VERSION ""

NS_ :

BS_:
BU_: ME SC01 BMS01 BMS PT
BO_ 1860 BMS05_DebugSlowMpex1: 8 BMS05
 SG_ SOHRecentChange_BMS05 m43 : 15|8@0+ (0.1,-15) [-15|10.5] ""  PT
 SG_ SOHConvergenceIndicator_BMS05 m43 : 31|8@0+ (1,0) [0|255] ""  PT
 SG_ SOHConvergenceCounter_BMS05 m43 : 39|8@0+ (0.024,3) [0|6] ""  PT
 SG_ SOHMinFiltered_BMS05 m43 : 23|8@0+ (0.3,50) [50|126.5] "PCT"  PT
 SG_ prechargeCyMatchWaitTime_BMS05 m43 : 47|16@0+ (1,0) [0|65535] "ms"  PT
 SG_ medianModuleTempGrp2_BMS05 m13 : 63|8@0+ (1,-40) [-40|200] "C"  PT
 SG_ medianModuleTempGrp1_BMS05 m13 : 55|8@0+ (1,-40) [-40|200] "C"  PT
 SG_ coolantWarningtAlert_BMS05 m12 : 49|2@0+ (1,0) [0|3] ""  PT
 SG_ coolantFaultAlert_BMS05 m12 : 51|2@0+ (1,0) [0|3] ""  PT
 SG_ hvilShutdownStrategy_BMS05 m42 : 63|8@0+ (1,0) [0|255] ""  PT
 SG_ J1939_nmState m12 : 55|4@0+ (1,0) [0|0] ""  PT
 SG_ PrechargeXCapMin_BMS05 m42 : 47|16@0+ (0.01,0) [0|1] "mF"  PT
 SG_ LimpHomeTimeOut_BMS05 m42 : 15|32@0+ (1,0) [0|4294967295] "ms"  PT
 SG_ hvWithstandTests_BMS05 m40 : 15|8@0+ (1,0) [0|255] ""  PT
 SG_ aux3prechargeState_BMS05 m41 : 19|4@0+ (1,0) [0|0] ""  PT
 SG_ aux2prechargeState_BMS05 m41 : 31|4@0+ (1,0) [0|0] ""  PT
 SG_ aux1prechargeState_BMS05 m41 : 27|4@0+ (1,0) [0|0] ""  PT
 SG_ auxLinkVoltage_BMS05 m40 : 23|16@0+ (0.02,0) [0|1310.7] "V"  PT
 SG_ invalidModuleVoltageFlags_BMS05 m41 : 39|32@0+ (1,0) [0|0] ""  PT
 SG_ invalidModuleTempFlags_BMS05 m40 : 39|32@0+ (1,0) [0|0] ""  PT
 SG_ pumpSpeedExpected_BMS05 m30 : 15|8@0+ (0.4,0) [0|102] "%"  PT
 SG_ rangeRequestIgnoreVehicle m28 : 55|4@0+ (1,0) [0|65535] ""  PT
 SG_ rangeRequestEepromValue m28 : 63|4@0+ (1,0) [0|65535] ""  PT
 SG_ pressure2_BMS05 m35 : 31|8@0+ (0.4,0) [0|19] "psi"  PT
 SG_ calibration_version_BMS05 m37 : 63|8@0+ (1,0) [0|0] ""  PT
 SG_ currentLowTimer_BMS05 m39 : 55|16@0+ (1,0) [0|65535] "s"  PT
 SG_ auxCntrrOpenUnderLoadCntr_BMS05 m39 : 39|16@0+ (1,0) [0|0] ""  PT
 SG_ rabbitContactorState_BMS05 m34 : 31|8@0+ (1,0) [0|255] ""  PT
 SG_ analogIsenseSupplyCurr_BMS05 m37 : 55|8@0+ (0.04,0) [0|10] "A"  PT
 SG_ pumpSpeedReqCoolPrfmc_BMS05 m29 : 15|8@0+ (1,0) [0|0] "PCT"  PT
 SG_ microsarOs_IdleTask_OsCr0_BMS05 m39 : 23|8@0+ (1,0) [0|100] "PCT"  PT
 SG_ microsarOs_BswTask_BMS05 m39 : 15|8@0+ (1,0) [0|100] "PCT"  PT
 SG_ microsarOs_InitTask_BMS05 m39 : 31|8@0+ (1,0) [0|100] "PCT"  PT
 SG_ microsarOs_ApplTask_1Hz_BMS05 m38 : 63|8@0+ (1,0) [0|100] "PCT"  PT
 SG_ microsarOs_ApplTask_10Hz_BMS05 m38 : 55|8@0+ (1,0) [0|100] "PCT"  PT
 SG_ microsarOs_ApplTask_100Hz_BMS05 m38 : 47|8@0+ (1,0) [0|100] "PCT"  PT
 SG_ microsarOs_ApplLowTask_BMS05 m38 : 39|8@0+ (1,0) [0|100] "PCT"  PT
 SG_ microsarOs_ApplLateInit_BMS05 m38 : 31|8@0+ (1,0) [0|100] "PCT"  PT
 SG_ microsarOs_ApplHighTask_BMS05 m38 : 23|8@0+ (1,0) [0|100] "PCT"  PT
 SG_ microsarOs_ApplEarlyInit_BMS05 m38 : 15|8@0+ (1,0) [0|100] "PCT"  PT
 SG_ pumpRecoveryAttempts_BMS05 m31 : 15|8@0+ (1,0) [0|0] ""  PT
 SG_ appTaskBSWMaxDuration_BMS05 m37 : 47|8@0+ (0.5,0) [0|100] "PCT"  PT
 SG_ appTaskApplHighMaxDuration_BMS05 m37 : 15|16@0+ (0.5,0) [0|100] "PCT"  PT
 SG_ appTask1HzMaxDuration_BMS05 m36 : 63|8@0+ (0.5,0) [0|100] "PCT"  PT
 SG_ appTask100HzMaxDuration_BMS05 m36 : 47|8@0+ (0.5,0) [0|100] "PCT"  PT
 SG_ appTask10HzMaxDuration_BMS05 m36 : 55|8@0+ (0.5,0) [0|100] "PCT"  PT
 SG_ appTask100HzDuration_BMS05 m36 : 15|8@0+ (0.5,0) [0|100] "PCT"  PT
 SG_ appTask10HzDuration_BMS05 m36 : 23|8@0+ (0.5,0) [0|100] "PCT"  PT
 SG_ appTask1HzDuration_BMS05 m36 : 31|8@0+ (0.5,0) [0|100] "PCT"  PT
 SG_ appTaskBSWDuration_BMS05 m36 : 39|8@0+ (0.5,0) [0|100] "PCT"  PT
 SG_ appTaskApplHighDuration_BMS05 m37 : 31|16@0+ (0.5,0) [0|100] "PCT"  PT
 SG_ iumprMaxRatioDTCId_BMS05 m35 : 15|8@0+ (1,0) [0|0] ""  PT
 SG_ iumprMaxRatio_BMS05 m35 : 23|8@0+ (1,0) [0|0] ""  PT
 SG_ iumprMinRatioDTCId_BMS05 m33 : 63|8@0+ (1,0) [0|0] ""  PT
 SG_ iumprMinRatio_BMS05 m33 : 55|8@0+ (1,0) [0|0] ""  PT
 SG_ eepromWriteCyclesMax_BMS05 m11 : 55|16@0+ (64,0) [0|0] ""  PT
 SG_ eepromWriteCyclesUds_BMS05 m10 : 55|8@0+ (1,0) [0|0] ""  PT
 SG_ eepromWriteCyclesStat_BMS05 m10 : 63|8@0+ (1,0) [0|0] ""  PT
 SG_ eepromWriteCyclesSoh_BMS05 m11 : 47|8@0+ (1,0) [0|0] ""  PT
 SG_ fluidLvlCount_BMS05 m34 : 15|8@0+ (1,0) [0|255] ""  PT
 SG_ fluidLvlSensr2_BMS05 m34 : 19|2@0+ (1,0) [0|0] ""  PT
 SG_ fluidLvlSensr1_BMS05 m34 : 17|2@0+ (1,0) [0|0] ""  PT
 SG_ pumpSpeedReqVhcleSpeed_BMS05 m2 : 15|8@0+ (1,0) [0|0] "PCT"  PT
 SG_ appTaskBSWCpuUsage_BMS05 m18 : 15|8@0+ (0.5,0) [0|100] "PCT"  PT
 SG_ appTask200HzCpuUsage_BMS05 m17 : 15|8@0+ (0.5,0) [0|100] "PCT"  PT
 SG_ SWVersionBL_BMS05 m34 : 39|32@0+ (1,0) [0|4294967295] ""  PT
 SG_ SWVersionApp_BMS05 m35 : 39|32@0+ (1,0) [0|4294967295] ""  PT
 SG_ hvSNACounter_BMS05 m31 : 23|16@0+ (1,0) [0|0] ""  PT
 SG_ pyroState_BMS05 m28 : 59|4@0+ (1,0) [0|0] ""  PT
 SG_ ecuSerialNrChar15_BMS05 m33 : 47|8@0+ (1,0) [0|0] ""  PT
 SG_ ecuSerialNrChar14_BMS05 m33 : 39|8@0+ (1,0) [0|0] ""  PT
 SG_ ecuSerialNrChar13_BMS05 m33 : 31|8@0+ (1,0) [0|0] ""  PT
 SG_ ecuSerialNrChar12_BMS05 m33 : 23|8@0+ (1,0) [0|0] ""  PT
 SG_ ecuSerialNrChar11_BMS05 m32 : 63|8@0+ (1,0) [0|0] ""  PT
 SG_ ecuSerialNrChar10_BMS05 m32 : 55|8@0+ (1,0) [0|0] ""  PT
 SG_ ecuSerialNrChar09_BMS05 m32 : 47|8@0+ (1,0) [0|0] ""  PT
 SG_ ecuSerialNrChar08_BMS05 m32 : 39|8@0+ (1,0) [0|0] ""  PT
 SG_ ecuSerialNrChar07_BMS05 m32 : 31|8@0+ (1,0) [0|0] ""  PT
 SG_ ecuSerialNrChar06_BMS05 m32 : 23|8@0+ (1,0) [0|0] ""  PT
 SG_ ecuSerialNrChar05_BMS05 m32 : 15|8@0+ (1,0) [0|0] ""  PT
 SG_ analogGPIO1Current_BMS05 m22 : 39|8@0+ (0.015,0) [0|3.825] "A"  PT
 SG_ analogGPIO1Volt_BMS05 m22 : 55|8@0+ (0.1,0) [0|25] "V"  PT
 SG_ analogGPIO2Current_BMS05 m22 : 47|8@0+ (0.015,0) [0|3.825] "A"  PT
 SG_ analogGPIO2Volt_BMS05 m22 : 63|8@0+ (0.1,0) [0|25] "V"  PT
 SG_ pumpSpeedReqLoadValue_BMS05 m22 : 15|8@0+ (1,0) [0|0] "PCT"  PT
 SG_ ssaRTYear_BMS05 m31 : 55|16@0+ (1,0) [0|0] "yyyy"  PT
 SG_ ssaRTMonth_BMS05 m31 : 47|8@0+ (1,0) [0|0] "mm"  PT
 SG_ ssaRTDay_BMS05 m31 : 39|8@0+ (1,0) [0|0] "dd"  PT
 SG_ ssaTimeMRealTimeOffset_BMS05 m30 : 23|48@0+ (1,0) [0|0] ""  PT
 SG_ ssaTimeMTickCount_BMS05 m29 : 23|48@0+ (1,0) [0|0] ""  PT
 SG_ appTask50HzStackUsage_BMS05 m24 : 15|8@0+ (0.5,0) [0|100] "PCT"  PT
 SG_ OBDMILRequested_BMS05 m28 : 49|2@0+ (1,0) [0|3] ""  PT
 SG_ OBDConfirmedDTCsCount_BMS05 m28 : 15|8@0+ (1,0) [0|255] ""  PT
 SG_ OBDFirstConfirmedDTC_BMS05 m28 : 31|8@0+ (1,0) [0|255] ""  PT
 SG_ OBDFirstConfDTCWarmCyc_BMS05 m28 : 47|6@0+ (1,0) [0|63] ""  PT
 SG_ OBDPermanentDTCCount_BMS05 m28 : 23|8@0+ (1,0) [0|255] ""  PT
 SG_ OBDFirstPermanentDTC_BMS05 m28 : 39|8@0+ (1,0) [0|255] ""  PT
 SG_ OBDFirstPermDTCDriveCyc_BMS05 m28 : 41|2@0+ (1,0) [0|3] ""  PT
 SG_ nmStartupReason_BMS05 m16 : 15|4@0+ (1,0) [0|0] ""  PT
 SG_ SOCdynamicRecal_BMS05 m10 : 19|1@0+ (1,0) [0|1] ""  PT
 SG_ SOCuserSOCInit_BMS05 m10 : 18|1@0+ (1,0) [0|1] ""  PT
 SG_ contactorType_BMS05 m25 : 11|4@0+ (1,0) [0|0] ""  PT
 SG_ activeIsoTestDuration_BMS05 m13 : 15|8@0+ (200,0) [0|51000] "ms"  PT
 SG_ balancingState_BMS05 m16 : 11|4@0+ (1,0) [0|0] ""  PT
 SG_ storCondSysNwOk_BMS05 m27 : 25|1@0+ (1,0) [0|0] ""  PT
 SG_ storCondSysPwrOk_BMS05 m27 : 26|1@0+ (1,0) [0|0] ""  PT
 SG_ storCondECUOk_BMS05 m27 : 24|1@0+ (1,0) [0|0] ""  PT
 SG_ chronoStackWrCnt_BMS05 m27 : 39|32@0+ (1,0) [0|0] ""  PT
 SG_ wakeReason_BMS05 m10 : 15|4@0+ (1,0) [0|0] ""  PT
 SG_ cntrUnderLoadOpenCntr7_BMS05 m26 : 63|8@0+ (1,0) [0|0] ""  PT
 SG_ cntrUnderLoadOpenCntr6_BMS05 m26 : 55|8@0+ (1,0) [0|0] ""  PT
 SG_ cntrUnderLoadOpenCntr5_BMS05 m26 : 47|8@0+ (1,0) [0|0] ""  PT
 SG_ cntrUnderLoadOpenCntr4_BMS05 m26 : 39|8@0+ (1,0) [0|0] ""  PT
 SG_ cntrUnderLoadOpenCntr3_BMS05 m26 : 31|8@0+ (1,0) [0|0] ""  PT
 SG_ cntrUnderLoadOpenCntr2_BMS05 m26 : 23|8@0+ (1,0) [0|0] ""  PT
 SG_ cntrUnderLoadOpenCntr1_BMS05 m26 : 15|8@0+ (1,0) [0|0] ""  PT
 SG_ coolantOutletTemperature_BMS05 m27 : 23|8@0+ (1,-40) [-40|215] "C"  PT
 SG_ coolantInletTemperature_BMS05 m27 : 15|8@0+ (1,-40) [-40|215] "C"  PT
 SG_ prchgResHeatModel_BMS05 m3 : 55|16@0+ (0.1,0) [0|0] "Ws"  PT
 SG_ variantCodingCount_BMS05 m7 : 15|8@0+ (1,0) [0|0] ""  PT
 SG_ SWVersionCusApp_BMS05 m7 : 39|32@0+ (1,0) [0|0] ""  PT
 SG_ contactorOpenRequest_BMS05 m25 : 15|4@0+ (1,0) [0|0] ""  PT
 SG_ maxBrickVoltageChargeLimit_BMS05 m25 : 23|16@0+ (0.0001,0) [0|6.5] "V"  PT
 SG_ desiccantTimer_BMS05 m25 : 39|32@0+ (1,0) [0|0] "s"  PT
 SG_ batSwitchOpenReason_BMS05 m4 : 55|16@0+ (1,0) [0|0] ""  PT
 SG_ balancingTime_BMS05 m24 : 55|16@0+ (1,0) [0|65535] ""  PT
 SG_ bmsIsESSMaster_BMS05 m6 : 14|1@0+ (1,0) [0|0] ""  PT
 SG_ ecuSerialNrChar01_BMS05 m12 : 23|8@0+ (1,0) [0|0] ""  PT
 SG_ ecuSerialNrChar02_BMS05 m12 : 31|8@0+ (1,0) [0|0] ""  PT
 SG_ ecuSerialNrChar03_BMS05 m12 : 39|8@0+ (1,0) [0|0] ""  PT
 SG_ ecuSerialNrChar04_BMS05 m12 : 47|8@0+ (1,0) [0|0] ""  PT
 SG_ ecuSerialNrChar16_BMS05 m13 : 23|8@0+ (1,0) [0|0] ""  PT
 SG_ ecuSerialNrChar17_BMS05 m13 : 31|8@0+ (1,0) [0|0] ""  PT
 SG_ ecuSerialNrChar18_BMS05 m13 : 39|8@0+ (1,0) [0|0] ""  PT
 SG_ ecuSerialNrChar19_BMS05 m13 : 47|8@0+ (1,0) [0|0] ""  PT
 SG_ maxModuleTemperature_BMS05 m5 : 63|8@0+ (1,-40) [-40|200] "C"  PT
 SG_ meanModuleTemperature_BMS05 m8 : 15|8@0+ (1,-40) [-40|200] "C"  PT
 SG_ minModuleTemperature_BMS05 m5 : 55|8@0+ (1,-40) [-40|200] "C"  PT
 SG_ currentEventsShrt_BMS05 m6 : 15|1@0+ (1,0) [0|0] ""  PT
 SG_ nmOperationalMode_BMS05 m1 : 13|2@0+ (1,0) [0|0] ""  PT
 SG_ nmNetworkMode_BMS05 m1 : 15|2@0+ (1,0) [0|0] ""  PT
 SG_ nmNetworkState_BMS05 m1 : 11|1@0+ (1,0) [0|0] ""  PT
 SG_ ecuState_BMS05 m1 : 10|3@0+ (1,0) [0|7] ""  PT
 SG_ SPIRxTxDiag_BMS05 m10 : 11|4@0+ (2,0) [0|30] ""  PT
 SG_ minSOC_BMS05 m24 : 23|16@0+ (0.01,0) [0|100] "PCT"  PT
 SG_ maxSOC_BMS05 m24 : 39|16@0+ (0.01,0) [0|100] "PCT"  PT
 SG_ appTaskMaxCpuUsage_BMS05 m23 : 63|8@0+ (0.5,0) [0|100] "PCT"  PT
 SG_ appTaskCpuUsage_BMS05 m23 : 55|8@0+ (0.5,0) [0|100] "PCT"  PT
 SG_ appTask50HzCpuUsage_BMS05 m23 : 47|8@0+ (0.5,0) [0|100] "PCT"  PT
 SG_ appTask10HzStackUsage_BMS05 m23 : 39|8@0+ (0.5,0) [0|100] "PCT"  PT
 SG_ appTask100HzCpuUsage_BMS05 m23 : 31|8@0+ (0.5,0) [0|100] "PCT"  PT
 SG_ appTask10HzCpuUsage_BMS05 m23 : 23|8@0+ (0.5,0) [0|100] "PCT"  PT
 SG_ appTask1HzCpuUsage_BMS05 m23 : 15|8@0+ (0.5,0) [0|100] "PCT"  PT
 SG_ pumpSpeedReq_BMS05 m12 : 15|8@0+ (1,0) [0|0] "PCT"  PT
 SG_ numberOfStrings_BMS05 m4 : 15|5@0+ (1,0) [0|0] ""  PT
 SG_ hvComponentOpLimit_BMS05 m22 : 23|16@0+ (0.05,0) [0|3276.75] "A"  PT
 SG_ regenCurrPredBrickVOffset_BMS05 m5 : 15|8@0+ (0.5,0) [0|127.5] "A"  PT
 SG_ dischgCurrPredBrickVOffset_BMS05 m3 : 15|8@0+ (0.5,0) [0|127.5] "A"  PT
 SG_ PCANBusOffState_BMS05 m6 : 11|2@0+ (1,0) [0|0] ""  PT
 SG_ SCANBusOffState_BMS05 m6 : 13|2@0+ (1,0) [0|0] ""  PT
 SG_ PTCANBusOffState_BMS05 m6 : 9|2@0+ (1,0) [0|0] ""  PT
 SG_ eepromWriteCyclesSoc_BMS05 m11 : 39|8@0+ (1,0) [0|0] ""  PT
 SG_ eepromWriteCyclesDiag_BMS05 m11 : 31|8@0+ (1,0) [0|0] ""  PT
 SG_ eepromWriteCyclesChrono_BMS05 m10 : 39|8@0+ (1,0) [0|0] ""  PT
 SG_ eepromWriteCyclesCust_BMS05 m10 : 47|8@0+ (1,0) [0|0] ""  PT
 SG_ customerModelVsYear_BMS05 m14 : 23|8@0+ (1,0) [0|0] ""  PT
 SG_ customerModelVsWeek_BMS05 m14 : 31|8@0+ (1,0) [0|0] ""  PT
 SG_ customerModelVsCellType_BMS05 m14 : 15|1@0+ (1,0) [0|0] ""  PT
 SG_ customerModelVsCellGen_BMS05 m14 : 14|7@0+ (1,0) [0|0] ""  PT
 SG_ SWVersion_BMS05 m14 : 39|32@0+ (1,0) [0|4294967295] ""  PT
 SG_ balancingRequest288_to_295_BMS05 m21 : 63|8@0+ (1,0) [0|0] ""  PT
 SG_ balancingRequest296_to_303_BMS05 m21 : 55|8@0+ (1,0) [0|0] ""  PT
 SG_ balancingRequest304_to_311_BMS05 m21 : 47|8@0+ (1,0) [0|0] ""  PT
 SG_ balancingRequest312_to_319_BMS05 m21 : 39|8@0+ (1,0) [0|0] ""  PT
 SG_ balancingRequest320_to_327_BMS05 m21 : 31|8@0+ (1,0) [0|0] ""  PT
 SG_ balancingRequest328_to_335_BMS05 m21 : 23|8@0+ (1,0) [0|0] ""  PT
 SG_ balancingRequest240_to_247_BMS05 m20 : 63|8@0+ (1,0) [0|0] ""  PT
 SG_ balancingRequest248_to_255_BMS05 m20 : 55|8@0+ (1,0) [0|0] ""  PT
 SG_ balancingRequest256_to_263_BMS05 m20 : 47|8@0+ (1,0) [0|0] ""  PT
 SG_ balancingRequest264_to_271_BMS05 m20 : 39|8@0+ (1,0) [0|0] ""  PT
 SG_ balancingRequest272_to_279_BMS05 m20 : 31|8@0+ (1,0) [0|0] ""  PT
 SG_ balancingRequest280_to_287_BMS05 m20 : 23|8@0+ (1,0) [0|0] ""  PT
 SG_ balancingRequest192_to_199_BMS05 m19 : 63|8@0+ (1,0) [0|0] ""  PT
 SG_ balancingRequest200_to_207_BMS05 m19 : 55|8@0+ (1,0) [0|0] ""  PT
 SG_ balancingRequest208_to_215_BMS05 m19 : 47|8@0+ (1,0) [0|0] ""  PT
 SG_ balancingRequest216_to_223_BMS05 m19 : 39|8@0+ (1,0) [0|0] ""  PT
 SG_ balancingRequest224_to_231_BMS05 m19 : 31|8@0+ (1,0) [0|0] ""  PT
 SG_ balancingRequest232_to_239_BMS05 m19 : 23|8@0+ (1,0) [0|0] ""  PT
 SG_ balancingRequest144_to_151_BMS05 m18 : 63|8@0+ (1,0) [0|0] ""  PT
 SG_ balancingRequest152_to_159_BMS05 m18 : 55|8@0+ (1,0) [0|0] ""  PT
 SG_ balancingRequest160_to_167_BMS05 m18 : 47|8@0+ (1,0) [0|0] ""  PT
 SG_ balancingRequest168_to_175_BMS05 m18 : 39|8@0+ (1,0) [0|0] ""  PT
 SG_ balancingRequest176_to_183_BMS05 m18 : 31|8@0+ (1,0) [0|0] ""  PT
 SG_ balancingRequest184_to_191_BMS05 m18 : 23|8@0+ (1,0) [0|0] ""  PT
 SG_ balancingRequest096_to_103_BMS05 m17 : 63|8@0+ (1,0) [0|0] ""  PT
 SG_ balancingRequest104_to_111_BMS05 m17 : 55|8@0+ (1,0) [0|0] ""  PT
 SG_ balancingRequest112_to_119_BMS05 m17 : 47|8@0+ (1,0) [0|0] ""  PT
 SG_ balancingRequest120_to_127_BMS05 m17 : 39|8@0+ (1,0) [0|0] ""  PT
 SG_ balancingRequest128_to_135_BMS05 m17 : 31|8@0+ (1,0) [0|0] ""  PT
 SG_ balancingRequest136_to_143_BMS05 m17 : 23|8@0+ (1,0) [0|0] ""  PT
 SG_ balancingRequest048_to_055_BMS05 m16 : 63|8@0+ (1,0) [0|0] ""  PT
 SG_ balancingRequest056_to_063_BMS05 m16 : 55|8@0+ (1,0) [0|0] ""  PT
 SG_ balancingRequest064_to_071_BMS05 m16 : 47|8@0+ (1,0) [0|0] ""  PT
 SG_ balancingRequest072_to_079_BMS05 m16 : 39|8@0+ (1,0) [0|0] ""  PT
 SG_ balancingRequest080_to_087_BMS05 m16 : 31|8@0+ (1,0) [0|0] ""  PT
 SG_ balancingRequest088_to_095_BMS05 m16 : 23|8@0+ (1,0) [0|0] ""  PT
 SG_ balancingRequest000_to_007_BMS05 m15 : 63|8@0+ (1,0) [0|0] ""  PT
 SG_ balancingRequest008_to_015_BMS05 m15 : 55|8@0+ (1,0) [0|0] ""  PT
 SG_ balancingRequest016_to_023_BMS05 m15 : 47|8@0+ (1,0) [0|0] ""  PT
 SG_ balancingRequest024_to_031_BMS05 m15 : 39|8@0+ (1,0) [0|0] ""  PT
 SG_ balancingRequest032_to_039_BMS05 m15 : 31|8@0+ (1,0) [0|0] ""  PT
 SG_ balancingRequest040_to_047_BMS05 m15 : 23|8@0+ (1,0) [0|0] ""  PT
 SG_ balancingVoltageTarget_BMS05 m15 : 15|8@0+ (0.02,0) [0|5.1] ""  PT
 SG_ numberOfPacksPerString_BMS05 m4 : 10|3@0+ (1,0) [0|0] ""  PT
 SG_ analogAddr5_BMS05 m1 : 23|8@0+ (0.05,0) [0|12] "V"  PT
 SG_ analogAddr0_BMS05 m1 : 63|8@0+ (0.05,0) [0|12] "V"  PT
 SG_ analogAddr4_BMS05 m1 : 31|8@0+ (0.05,0) [0|12] "V"  PT
 SG_ analogAddr3_BMS05 m1 : 39|8@0+ (0.05,0) [0|12] "V"  PT
 SG_ analogAddr2_BMS05 m1 : 47|8@0+ (0.05,0) [0|12] "V"  PT
 SG_ analogAddr1_BMS05 m1 : 55|8@0+ (0.05,0) [0|12] "V"  PT
 SG_ debugSlowMpex1_BMS05 M : 7|8@0+ (1,0) [0|0] ""  PT
 SG_ analog3V3DSupply_BMS05 m9 : 15|8@0+ (0.015,0) [0|0] "V"  PT
 SG_ pressure_BMS05 m9 : 63|8@0+ (0.4,0) [0|19] "psi"  PT
 SG_ analog3P3VA_BMS05 m9 : 55|8@0+ (0.015,0) [0|3.825] "V"  PT
 SG_ analog5VA_BMS05 m9 : 31|8@0+ (0.025,0) [0|6] "V"  PT
 SG_ analog5VD_BMS05 m9 : 23|8@0+ (0.025,0) [0|6] "V"  PT
 SG_ analog5VSensorSupply_BMS05 m9 : 47|8@0+ (0.025,0) [0|6.375] "V"  PT
 SG_ analog6V5_BMS05 m9 : 39|8@0+ (0.0075,5) [5|6.9125] "V"  PT
 SG_ isolationResistanceIntern_BMS05 m8 : 55|16@0+ (2,0) [0|130000] "kOhm"  PT
 SG_ isolationResistanceExtern_BMS05 m8 : 39|16@0+ (2,0) [0|130000] "kOhm"  PT
 SG_ linkVoltage_BMS05 m8 : 23|16@0+ (0.02,0) [0|1310.7] "V"  PT
 SG_ eepromWriteCyclesBasics_BMS05 m11 : 23|8@0+ (1,0) [0|0] ""  PT
 SG_ eepromBlockIndex_BMS05 m11 : 15|8@0+ (1,0) [0|0] ""  PT
 SG_ CAN1MIATimerISR_BMS05 m7 : 23|8@0+ (1,0) [0|255] ""  PT
 SG_ CAN2MIATimerISR_BMS05 m7 : 31|8@0+ (1,0) [0|255] ""  PT
 SG_ regenCurrentOpLimit_BMS05 m5 : 39|16@0+ (0.05,0) [0|3200] "A"  PT
 SG_ regenCurrentErrorLimit_BMS05 m5 : 23|16@0+ (0.05,0) [0|3200] "A"  PT
 SG_ lifetime_BMS05 m6 : 39|32@0+ (1,0) [0|0] "s"  PT
 SG_ eepromReadTime_BMS05 m0 : 15|8@0+ (10,0) [0|2550] "ms"  PT
 SG_ chargerCurrentOpLimit_BMS05 m4 : 39|16@0+ (0.05,0) [0|3200] "A"  PT
 SG_ dischargeCurrentOpLimit_BMS05 m3 : 39|16@0+ (0.05,-3200) [-3200|0] "A"  PT
 SG_ chargerCurrentErrorLimit_BMS05 m4 : 23|16@0+ (0.05,0) [0|3200] "A"  PT
 SG_ dischargeCurrentErrorLimit_BMS05 m3 : 23|16@0+ (0.05,-3200) [-3200|0] "A"  PT
 SG_ pumpSpeedReqMaxT_BMS05 m2 : 23|8@0+ (1,0) [0|0] "PCT"  PT
 SG_ pumpSpeedReqDeltaT_BMS05 m2 : 31|8@0+ (1,0) [0|0] "PCT"  PT
 SG_ energyThroughput_BMS05 m2 : 39|32@0+ (0.001,0) [0|4294967.295] "kWh"  PT
 SG_ packVoltageCMB_BMS05 m6 : 23|16@0+ (0.02,0) [0|1200] "V"  PT
 SG_ ctrOffTimeLast_BMS05 m0 : 23|16@0+ (1,0) [0|0] "s"  PT
 SG_ ctrOffTime_BMS05 m0 : 39|16@0+ (1,0) [0|0] "s"  PT
 SG_ sleepTime_BMS05 m0 : 55|16@0+ (1,0) [0|0] "s"  PT
 SG_ SPIRxTxTimeAllPckts_BMS05 m10 : 31|8@0+ (2,0) [0|500] "ms"  PT
 SG_ isolationTestState_BMS05 m10 : 17|2@0+ (1,0) [0|0] ""  PT
 SG_ SOCvoltageInit_BMS05 m10 : 21|1@0+ (1,0) [0|1] ""  PT
 SG_ SOCocvInit_BMS05 m10 : 23|1@0+ (1,0) [0|1] ""  PT
 SG_ SOCeepromInit_BMS05 m10 : 22|1@0+ (1,0) [0|1] ""  PT
 SG_ SOCdefaultInit_BMS05 m10 : 20|1@0+ (1,0) [0|1] ""  PT

BO_ 1732 BMS05_DebugFastMpex1: 8 BMS05
 SG_ SPIRxTxHeaderMux3Status_BMS05 m1 : 23|1@0+ (1,0) [0|1] ""  PT
 SG_ SPIRxTxHeaderMux2Status_BMS05 m1 : 22|1@0+ (1,0) [0|1] ""  PT
 SG_ SPIRxTxHeaderMux1Status_BMS05 m1 : 21|1@0+ (1,0) [0|1] ""  PT
 SG_ SPIRxTxHeaderMux0Status_BMS05 m1 : 20|1@0+ (1,0) [0|1] ""  PT
 SG_ activeIsoTestPsbl_BMS05 m0 : 27|1@0+ (1,0) [0|0] ""  PT
 SG_ activeIsoState_BMS05 m3 : 15|8@0+ (1,0) [0|0] ""  PT
 SG_ activeIsoNegLink_BMS05 m3 : 39|16@0+ (0.04,-1250) [-1250|1371.4] "V"  PT
 SG_ activeIsoPosLink_BMS05 m3 : 23|16@0+ (0.04,-1250) [-1250|1371.4] "V"  PT
 SG_ activeIsoTestStateTimer_BMS05 m2 : 15|8@0+ (200,0) [0|51000] "ms"  PT
 SG_ activeIsoPosBuffer_BMS05 m2 : 23|16@0+ (0.04,-1250) [-1250|1371.4] "V"  PT
 SG_ activeIsoNegBuffer_BMS05 m2 : 39|16@0+ (0.04,-1250) [-1250|1371.4] "V"  PT
 SG_ activeIsoResRaw_BMS05 m2 : 55|16@0+ (2,0) [0|130000] "kOhm"  PT
 SG_ activeIsoResFilter_BMS05 m3 : 55|16@0+ (2,0) [0|130000] "kOhm"  PT
 SG_ contactorStateAux_BMS05 m1 : 34|3@0+ (1,0) [0|0] ""  PT
 SG_ batSwitchOpenReqEssMstr_BMS05 m0 : 35|2@0+ (1,0) [0|0] ""  PT
 SG_ packShutdownTarget_BMS05 m1 : 12|2@0+ (1,0) [0|0] ""  PT
 SG_ weldedState_BMS05 m1 : 39|2@0+ (1,0) [0|0] ""  PT
 SG_ DIGIO_GPIO2_ON_BMS05 m1 : 19|1@0+ (1,0) [0|0] ""  PT
 SG_ DIGIO_GPIO1_ON_BMS05 m1 : 18|1@0+ (1,0) [0|0] ""  PT
 SG_ DIGIO_12VCURR_SENSE_ON_BMS05 m1 : 37|1@0+ (1,0) [0|0] ""  PT
 SG_ DIGIO_PSUP_SAFETY_OK_BMS05 m1 : 17|1@0+ (1,0) [0|0] ""  PT
 SG_ contactorStateRq_BMS05 m1 : 36|2@0+ (1,0) [0|0] ""  PT
 SG_ contactorPwrOkToPrechg_BMS05 m1 : 16|1@0+ (1,0) [0|0] ""  PT
 SG_ strMstrStrPrechgState_BMS05 m1 : 58|3@0+ (1,0) [0|0] ""  PT
 SG_ packShutdwnTmrQual_BMS05 m1 : 27|1@0+ (1,0) [0|0] ""  PT
 SG_ packStateRequest_BMS05 m1 : 15|3@0+ (1,0) [0|0] ""  PT
 SG_ packState_BMS05 m1 : 31|4@0+ (1,0) [0|0] ""  PT
 SG_ SPIRxTxTimer_BMS05 m1 : 47|8@0+ (2,0) [0|500] "ms"  PT
 SG_ moduleTMinMaxMeanQual_BMS05 m1 : 26|1@0+ (1,0) [0|0] ""  PT
 SG_ currentQual_BMS05 m1 : 25|1@0+ (1,0) [0|0] ""  PT
 SG_ brickVMinMaxMeanQual_BMS05 m1 : 24|1@0+ (1,0) [0|0] ""  PT
 SG_ negCtr1OnReqASW_BMS05 m1 : 8|1@0+ (1,0) [0|0] ""  PT
 SG_ prechgCtr1OnReqASW_BMS05 m1 : 9|1@0+ (1,0) [0|0] ""  PT
 SG_ posCtr1OnReqASW_BMS05 m1 : 10|1@0+ (1,0) [0|0] ""  PT
 SG_ DIGIO_CNTR_HISIDE_ON_MC_BMS05 m0 : 38|1@0+ (1,0) [0|0] ""  PT
 SG_ DIGIO_CNTR_HISIDE_ON_CHCKD_BMS05 m0 : 37|1@0+ (1,0) [0|0] ""  PT
 SG_ DIGIO_CNTR_CLOSE_OK_CHCKD_BMS05 m0 : 36|1@0+ (1,0) [0|0] ""  PT
 SG_ debugFastMpex1_BMS05 M : 7|8@0+ (1,0) [0|0] ""  PT
 SG_ stateContactorControl_BMS05 m0 : 41|1@0+ (1,0) [0|0] ""  PT
 SG_ stateVoltage_BMS05 m0 : 43|1@0+ (1,0) [0|0] ""  PT
 SG_ stateTemperature_BMS05 m0 : 44|1@0+ (1,0) [0|0] ""  PT
 SG_ stateSelfTest_BMS05 m0 : 45|1@0+ (1,0) [0|0] ""  PT
 SG_ stateHVIL_BMS05 m0 : 46|1@0+ (1,0) [0|0] ""  PT
 SG_ stateCurrent_BMS05 m0 : 47|1@0+ (1,0) [0|0] ""  PT
 SG_ stateCrash_BMS05 m0 : 42|1@0+ (1,0) [0|0] ""  PT
 SG_ stateContactors_BMS05 m0 : 40|1@0+ (1,0) [0|0] ""  PT
 SG_ stateCANRx_BMS05 m0 : 39|1@0+ (1,0) [0|0] ""  PT
 SG_ itemState_BMS05 m0 : 33|2@0+ (1,0) [0|0] ""  PT
 SG_ negLink_BMS05 m0 : 23|8@0+ (10,-1200) [-1200|1350] "V"  PT
 SG_ posLink_BMS05 m0 : 15|8@0+ (10,-1200) [-1200|1350] "V"  PT
 SG_ negPack_BMS05 m0 : 63|8@0+ (10,-1200) [-1200|1350] "V"  PT
 SG_ posPack_BMS05 m0 : 55|8@0+ (10,-1200) [-1200|1350] "V"  PT
 SG_ prechargeState_BMS05 m0 : 31|4@0+ (1,0) [0|0] ""  PT
 SG_ contactorState_BMS05 m0 : 26|3@0+ (1,0) [0|0] ""  PT
 SG_ diagStandbyImmShutdown_BMS05 m1 : 61|1@0+ (1,0) [0|1] ""  PT
 SG_ diagAllOffRequired_BMS05 m1 : 60|1@0+ (1,0) [0|1] ""  PT
 SG_ diagDriveTransitionNotOK_BMS05 m1 : 55|1@0+ (1,0) [0|1] ""  PT
 SG_ diagDriveImmShutdown_BMS05 m1 : 54|1@0+ (1,0) [0|1] ""  PT
 SG_ diagDriveDelShutdown2_BMS05 m1 : 52|1@0+ (1,0) [0|1] ""  PT
 SG_ diagDriveDelShutdown1_BMS05 m1 : 53|1@0+ (1,0) [0|1] ""  PT
 SG_ diagUnused_BMS05 m1 : 59|1@0+ (1,0) [0|1] ""  PT
 SG_ diagChargeTransitionNotOK_BMS05 m1 : 51|1@0+ (1,0) [0|1] ""  PT
 SG_ diagChargeImmShutdown_BMS05 m1 : 50|1@0+ (1,0) [0|1] ""  PT
 SG_ diagAccDelShutdown1_BMS05 m1 : 62|1@0+ (1,0) [0|1] ""  PT
 SG_ diagChargeDelShutdown1_BMS05 m1 : 49|1@0+ (1,0) [0|1] ""  PT
 SG_ diagAccTransitionNotOK_BMS05 m1 : 48|1@0+ (1,0) [0|1] ""  PT
 SG_ diagAccImmShutdown_BMS05 m1 : 63|1@0+ (1,0) [0|1] ""  PT

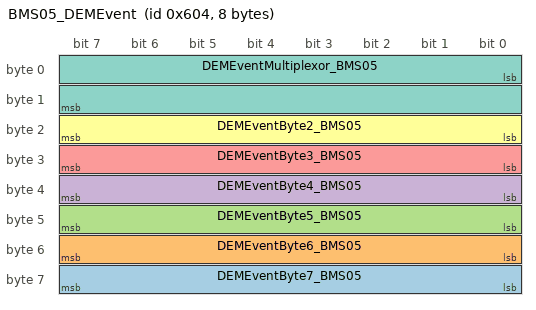
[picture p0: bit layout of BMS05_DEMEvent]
BO_ 1540 BMS05_DEMEvent: 8 BMS05
 SG_ DEMEventByte7_BMS05 : 63|8@0+ (1,0) [0|0] ""  PT
 SG_ DEMEventByte6_BMS05 : 55|8@0+ (1,0) [0|0] ""  PT
 SG_ DEMEventByte5_BMS05 : 47|8@0+ (1,0) [0|0] ""  PT
 SG_ DEMEventByte4_BMS05 : 39|8@0+ (1,0) [0|0] ""  PT
 SG_ DEMEventByte3_BMS05 : 31|8@0+ (1,0) [0|0] ""  PT
 SG_ DEMEventByte2_BMS05 : 23|8@0+ (1,0) [0|0] ""  PT
 SG_ DEMEventMultiplexor_BMS05 M : 0|16@1+ (1,0) [0|0] ""  PT

BO_ 1028 BMS05_DebugEventMap1: 8 BMS05
 SG_ DEM001_POWERUP_BMS05 : 11|2@0+ (1,0) [0|0] ""  PT
 SG_ DEM002_VOLTAGE_BRICK_OV_BMS05 : 13|2@0+ (1,0) [0|0] ""  PT
 SG_ DEM003_VOLTAGE_BRICK_UV_BMS05 : 15|2@0+ (1,0) [0|0] ""  PT
 SG_ DEM004_VOLTAGE_BRICK_SNA_BMS05 : 1|2@0+ (1,0) [0|0] ""  PT
 SG_ DEM005_VOLTAGE_BRICK_IMBAL_BMS05 : 3|2@0+ (1,0) [0|0] ""  PT
 SG_ DEM006_VOLTAGE_CAPCY_IMBAL_BMS05 : 5|2@0+ (1,0) [0|0] ""  PT
 SG_ DEM007_MODULET_HIGH_DELTA_BMS05 : 7|2@0+ (1,0) [0|0] ""  PT
 SG_ DEM008_VOLTAGE_PACK_UV_BMS05 : 25|2@0+ (1,0) [0|0] ""  PT
 SG_ DEM009_VOLTAGE_PACK_OV_BMS05 : 27|2@0+ (1,0) [0|0] ""  PT
 SG_ DEM010_VOLTAGE_PACK_PLAUSI_BMS05 : 29|2@0+ (1,0) [0|0] ""  PT
 SG_ DEM011_VOLTAGE_PCKLINK_MIS_BMS05 : 31|2@0+ (1,0) [0|0] ""  PT
 SG_ DEM012_VOLTAGE_BMS_SUPPLY_BMS05 : 17|2@0+ (1,0) [0|0] ""  PT
 SG_ DEM013_ADC_ERROR_BMS05 : 19|2@0+ (1,0) [0|0] ""  PT
 SG_ DEM014_MODULET_OT_BMS05 : 21|2@0+ (1,0) [0|0] ""  PT
 SG_ DEM015_MODULET_SNA_BMS05 : 23|2@0+ (1,0) [0|0] ""  PT
 SG_ DEM016_MODULET_LIMPHOME_BMS05 : 41|2@0+ (1,0) [0|0] ""  PT
 SG_ DEM017_COOLING_SYS_LHOME_BMS05 : 43|2@0+ (1,0) [0|0] ""  PT
 SG_ DEM018_HVIL_LIMPHOME_BMS05 : 45|2@0+ (1,0) [0|0] ""  PT
 SG_ DEM019_HVIL_ESS_INHIBIT_BMS05 : 47|2@0+ (1,0) [0|0] ""  PT
 SG_ DEM020_MODULET_CHANGE_BMS05 : 33|2@0+ (1,0) [0|0] ""  PT
 SG_ DEM021_LG_MAVD_FAULT_BMS05 : 35|2@0+ (1,0) [0|0] ""  PT
 SG_ DEM022_LG_RDV_FAULT_BMS05 : 37|2@0+ (1,0) [0|0] ""  PT
 SG_ DEM023_BMS_ONBOARDT_SNA_BMS05 : 39|2@0+ (1,0) [0|0] ""  PT
 SG_ DEM024_BMS_ONBOARDRH_OH_BMS05 : 57|2@0+ (1,0) [0|0] ""  PT
 SG_ DEM025_BMS_ONBOARDRH_SNA_BMS05 : 59|2@0+ (1,0) [0|0] ""  PT
 SG_ DEM026_CURRENT_OVERCHARGE_BMS05 : 61|2@0+ (1,0) [0|0] ""  PT
 SG_ DEM027_CURRENT_OVERDISCHGE_BMS05 : 63|2@0+ (1,0) [0|0] ""  PT
 SG_ DEM028_CURRENT_INVALID_BMS05 : 49|2@0+ (1,0) [0|0] ""  PT
 SG_ DEM029_CURRENT_SHORTCIRCT_BMS05 : 51|2@0+ (1,0) [0|0] ""  PT
 SG_ DEM030_CRASH_CAN_LATCH_BMS05 : 53|2@0+ (1,0) [0|0] ""  PT
 SG_ DEM031_EEPROM_FAIL_BMS05 : 55|2@0+ (1,0) [0|0] ""  PT

BO_ 1092 BMS05_DebugEventMap2: 8 BMS05
 SG_ DEM032_PCHG_PACKS_CONNECT_BMS05 : 9|2@0+ (1,0) [0|0] ""  PT
 SG_ DEM033_PCHG_ILLEGAL_PRCHG_BMS05 : 11|2@0+ (1,0) [0|0] ""  PT
 SG_ DEM034_PCHG_RELAY_FAIL_BMS05 : 13|2@0+ (1,0) [0|0] ""  PT
 SG_ DEM035_PCHG_NEG_WELD_BMS05 : 15|2@0+ (1,0) [0|0] ""  PT
 SG_ DEM036_PCHG_NEG_PULLIN_BMS05 : 1|2@0+ (1,0) [0|0] ""  PT
 SG_ DEM037_PCHG_SHORTCIRCUIT_BMS05 : 3|2@0+ (1,0) [0|0] ""  PT
 SG_ DEM038_PCHG_OPENCIRCUIT_BMS05 : 5|2@0+ (1,0) [0|0] ""  PT
 SG_ DEM039_PCHG_TIMEOUT_BMS05 : 7|2@0+ (1,0) [0|0] ""  PT
 SG_ DEM040_PCHG_FAILED_BMS05 : 25|2@0+ (1,0) [0|0] ""  PT
 SG_ DEM041_HVIL_SHUTDOWN_BMS05 : 27|2@0+ (1,0) [0|0] ""  PT
 SG_ DEM042_PCHG_POS_WELD_BMS05 : 29|2@0+ (1,0) [0|0] ""  PT
 SG_ DEM043_HV_LOCK_TRANSPORT_BMS05 : 31|2@0+ (1,0) [0|0] ""  PT
 SG_ DEM044_CTRS_END_OF_LIFE_BMS05 : 17|2@0+ (1,0) [0|0] ""  PT
 SG_ DEM045_CTRS_CTRPWRV_HI_BMS05 : 19|2@0+ (1,0) [0|0] ""  PT
 SG_ DEM046_CTRS_COILCURR_LOW_BMS05 : 21|2@0+ (1,0) [0|0] ""  PT
 SG_ DEM047_CTRS_COILCURR_HIGH_BMS05 : 23|2@0+ (1,0) [0|0] ""  PT
 SG_ DEM048_CTRS_CTRPWRV_LOW_BMS05 : 41|2@0+ (1,0) [0|0] ""  PT
 SG_ DEM049_CHGE_ILLEGAL_DISCHG_BMS05 : 43|2@0+ (1,0) [0|0] ""  PT
 SG_ DEM050_STARTUP_CONDITIONS_BMS05 : 45|2@0+ (1,0) [0|0] ""  PT
 SG_ DEM051_VOLTAGE_BMS_SUPPLYH_BMS05 : 47|2@0+ (1,0) [0|0] ""  PT
 SG_ DEM052_SAFETYSPI_FAIL_BMS05 : 33|2@0+ (1,0) [0|0] ""  PT
 SG_ DEM053_WATCHDOG_ERRORPIN_BMS05 : 35|2@0+ (1,0) [0|0] ""  PT
 SG_ DEM054_SAFESTATE_TRIGGERED_BMS05 : 37|2@0+ (1,0) [0|0] ""  PT
 SG_ DEM055_DEBUG_CMND_ACTIVE_BMS05 : 39|2@0+ (1,0) [0|0] ""  PT
 SG_ DEM056_CRASH_CAN_BMS05 : 57|2@0+ (1,0) [0|0] ""  PT
 SG_ DEM057_ISO_EXT_STRAT_4_BMS05 : 59|2@0+ (1,0) [0|0] ""  PT
 SG_ DEM058_ISO_EXT_RES_ERR_BMS05 : 61|2@0+ (1,0) [0|0] ""  PT
 SG_ DEM059_ISO_EXT_RES_WARN_BMS05 : 63|2@0+ (1,0) [0|0] ""  PT
 SG_ DEM060_ISO_INT_RES_ERR_BMS05 : 49|2@0+ (1,0) [0|0] ""  PT
 SG_ DEM061_ISO_INT_RES_WARN_BMS05 : 51|2@0+ (1,0) [0|0] ""  PT
 SG_ DEM062_EMERGENCY_OPERATION_BMS05 : 53|2@0+ (1,0) [0|0] ""  PT
 SG_ DEM063_ENDOFDRIVE_BMS05 : 55|2@0+ (1,0) [0|0] ""  PT

BO_ 1156 BMS05_DebugEventMap3: 8 BMS05
 SG_ DEM064_STRINGV_IMBALANCE_BMS05 : 9|2@0+ (1,0) [0|0] ""  PT
 SG_ DEM065_STRING_FAULT_BMS05 : 11|2@0+ (1,0) [0|0] ""  PT
 SG_ DEM066_ESS_FAULT_BMS05 : 13|2@0+ (1,0) [0|0] ""  PT
 SG_ DEM067_ISO_EXT_STRAT_3_BMS05 : 15|2@0+ (1,0) [0|0] ""  PT
 SG_ DEM068_MODULE_COUNT_INVALI_BMS05 : 1|2@0+ (1,0) [0|0] ""  PT
 SG_ DEM069_PT_MIA_BMS05 : 3|2@0+ (1,0) [0|0] ""  PT
 SG_ DEM070_BMSMIA_STRNGMSTR_01_BMS05 : 5|2@0+ (1,0) [0|0] ""  PT
 SG_ DEM071_BMSMIA_STRNGMSTR_05_BMS05 : 7|2@0+ (1,0) [0|0] ""  PT
 SG_ DEM072_BMSMIA_STRNGMSTR_09_BMS05 : 25|2@0+ (1,0) [0|0] ""  PT
 SG_ DEM073_BMSMIA_STRNGMSTR_13_BMS05 : 27|2@0+ (1,0) [0|0] ""  PT
 SG_ DEM074_BMSMIA_STRNGMSTR_17_BMS05 : 29|2@0+ (1,0) [0|0] ""  PT
 SG_ DEM075_BMSMIA_STRNGMSTR_21_BMS05 : 31|2@0+ (1,0) [0|0] ""  PT
 SG_ DEM076_BMSMIA_STRNGMSTR_25_BMS05 : 17|2@0+ (1,0) [0|0] ""  PT
 SG_ DEM077_BMSMIA_STRNGMSTR_29_BMS05 : 19|2@0+ (1,0) [0|0] ""  PT
 SG_ DEM078_BMSMIA_STRNGMSTR_33_BMS05 : 21|2@0+ (1,0) [0|0] ""  PT
 SG_ DEM079_BMSMIA_STRNGMSTR_37_BMS05 : 23|2@0+ (1,0) [0|0] ""  PT
 SG_ DEM080_BMSMIA_STRNGMSTR_41_BMS05 : 41|2@0+ (1,0) [0|0] ""  PT
 SG_ DEM081_BMSMIA_STRNGMSTR_45_BMS05 : 43|2@0+ (1,0) [0|0] ""  PT
 SG_ DEM082_BMSMIA_STRNGMSTR_49_BMS05 : 45|2@0+ (1,0) [0|0] ""  PT
 SG_ DEM083_BMSMIA_STRNGMSTR_53_BMS05 : 47|2@0+ (1,0) [0|0] ""  PT
 SG_ DEM084_BMSMIA_STRNGMSTR_57_BMS05 : 33|2@0+ (1,0) [0|0] ""  PT
 SG_ DEM085_BMSMIA_STRNGMSTR_61_BMS05 : 35|2@0+ (1,0) [0|0] ""  PT
 SG_ DEM086_ESSCURRENT_SHORT_BMS05 : 37|2@0+ (1,0) [0|0] ""  PT
 SG_ DEM087_PT_MIA_SHUTDOWN_BMS05 : 39|2@0+ (1,0) [0|0] ""  PT
 SG_ DEM088_OUTLET_NTC_HI_BMS05 : 57|2@0+ (1,0) [0|0] ""  PT
 SG_ DEM089_OUTLET_NTC_LO_BMS05 : 59|2@0+ (1,0) [0|0] ""  PT
 SG_ DEM090_BMSMIA_ESSMASTER_BMS05 : 61|2@0+ (1,0) [0|0] ""  PT
 SG_ DEM091_PCHG_RES_OVERHEAT_BMS05 : 63|2@0+ (1,0) [0|0] ""  PT
 SG_ DEM092_BMSMIA_STRNGSLAVE_0_BMS05 : 49|2@0+ (1,0) [0|0] ""  PT
 SG_ DEM093_BMSMIA_STRNGSLAVE_1_BMS05 : 51|2@0+ (1,0) [0|0] ""  PT
 SG_ DEM094_BMSMIA_STRNGSLAVE_2_BMS05 : 53|2@0+ (1,0) [0|0] ""  PT
 SG_ DEM095_BMSMIA_STRNGSLAVE_3_BMS05 : 55|2@0+ (1,0) [0|0] ""  PT

BO_ 1220 BMS05_DebugEventMap4: 8 BMS05
 SG_ DEM096_SC_STATE_SELFTEST_BMS05 : 9|2@0+ (1,0) [0|0] ""  PT
 SG_ DEM097_SC_STATE_TEMP_BMS05 : 11|2@0+ (1,0) [0|0] ""  PT
 SG_ DEM098_SC_STATE_VOLTAGE_BMS05 : 13|2@0+ (1,0) [0|0] ""  PT
 SG_ DEM099_SC_STATE_HVIL_BMS05 : 15|2@0+ (1,0) [0|0] ""  PT
 SG_ DEM100_SC_STATE_CONTACTORS_BMS05 : 1|2@0+ (1,0) [0|0] ""  PT
 SG_ DEM101_SC_STATE_CURRENT_BMS05 : 3|2@0+ (1,0) [0|0] ""  PT
 SG_ DEM102_SC_STATE_CANRX_BMS05 : 5|2@0+ (1,0) [0|0] ""  PT
 SG_ DEM103_SC_STATE_CRASH_BMS05 : 7|2@0+ (1,0) [0|0] ""  PT
 SG_ DEM104_SC_STATE_CCTRL_BMS05 : 25|2@0+ (1,0) [0|0] ""  PT
 SG_ DEM105_SC_STATE_CANTX_BMS05 : 27|2@0+ (1,0) [0|0] ""  PT
 SG_ DEM106_SC_STATE_THERMALEVT_BMS05 : 29|2@0+ (1,0) [0|0] ""  PT
 SG_ DEM107_SC_STATE_COOLANT_BMS05 : 31|2@0+ (1,0) [0|0] ""  PT
 SG_ DEM108_SC_SELFTEST_SFTY_UC_BMS05 : 17|2@0+ (1,0) [0|0] ""  PT
 SG_ DEM109_SC_TEMP_HIGH_BMS05 : 19|2@0+ (1,0) [0|0] ""  PT
 SG_ DEM110_SC_TEMP_NTC_OPEN_BMS05 : 21|2@0+ (1,0) [0|0] ""  PT
 SG_ DEM111_SC_TEMP_NTC_SHORT_BMS05 : 23|2@0+ (1,0) [0|0] ""  PT
 SG_ DEM112_CMB_DISCONNECTED_BMS05 : 41|2@0+ (1,0) [0|0] ""  PT
 SG_ DEM113_CMB_DEFECT_BMS05 : 43|2@0+ (1,0) [0|0] ""  PT
 SG_ DEM114_CMB_COMMERROR_BMS05 : 45|2@0+ (1,0) [0|0] ""  PT
 SG_ DEM115_SC_CURR_HALL_PWR_LO_BMS05 : 47|2@0+ (1,0) [0|0] ""  PT
 SG_ DEM116_SC_CURR_HALL_VHIGH_BMS05 : 33|2@0+ (1,0) [0|0] ""  PT
 SG_ DEM117_SC_CURR_HALL_ADC_BMS05 : 35|2@0+ (1,0) [0|0] ""  PT
 SG_ DEM118_SC_CURR_HALL_VLOW_BMS05 : 37|2@0+ (1,0) [0|0] ""  PT
 SG_ DEM119_SC_CURR_ISENSE_PWR_BMS05 : 39|2@0+ (1,0) [0|0] ""  PT
 SG_ DEM120_SC_CURR_ISENSE1_MIA_BMS05 : 57|2@0+ (1,0) [0|0] ""  PT
 SG_ DEM121_SC_CURR_ISENSE2_MIA_BMS05 : 59|2@0+ (1,0) [0|0] ""  PT
 SG_ DEM122_SC_CURR_ISENSE3_MIA_BMS05 : 61|2@0+ (1,0) [0|0] ""  PT
 SG_ DEM123_SC_CURR_ISENSE4_MIA_BMS05 : 63|2@0+ (1,0) [0|0] ""  PT
 SG_ DEM124_SC_CURR_ISENSE5_MIA_BMS05 : 49|2@0+ (1,0) [0|0] ""  PT
 SG_ DEM125_SC_CURR_ISENSE1_FLT_BMS05 : 51|2@0+ (1,0) [0|0] ""  PT
 SG_ DEM126_SC_CURR_ISENSE2_FLT_BMS05 : 53|2@0+ (1,0) [0|0] ""  PT
 SG_ DEM127_SC_CURR_ISENSE3_FLT_BMS05 : 55|2@0+ (1,0) [0|0] ""  PT

BO_ 1284 BMS05_DebugEventMap5: 8 BMS05
 SG_ DEM128_SC_CURR_ISENSE4_FLT_BMS05 : 9|2@0+ (1,0) [0|0] ""  PT
 SG_ DEM129_SC_CURR_ISENSE5_FLT_BMS05 : 11|2@0+ (1,0) [0|0] ""  PT
 SG_ DEM130_SC_CURR_OFFSET_BMS05 : 13|2@0+ (1,0) [0|0] ""  PT
 SG_ DEM131_SC_CURR_PLAUSI_BMS05 : 15|2@0+ (1,0) [0|0] ""  PT
 SG_ DEM132_SC_CURR_CHARGE_HIGH_BMS05 : 1|2@0+ (1,0) [0|0] ""  PT
 SG_ DEM133_SC_CURR_DSCHAR_HIGH_BMS05 : 3|2@0+ (1,0) [0|0] ""  PT
 SG_ DEM134_SC_V_CMB_SUMOFCELL_BMS05 : 5|2@0+ (1,0) [0|0] ""  PT
 SG_ DEM135_SC_V_SENSE_OPENWIRE_BMS05 : 7|2@0+ (1,0) [0|0] ""  PT
 SG_ DEM136_SC_V_CMB_DRV_FROZEN_BMS05 : 25|2@0+ (1,0) [0|0] ""  PT
 SG_ DEM137_SC_V_PACK_PLAUSI_BMS05 : 27|2@0+ (1,0) [0|0] ""  PT
 SG_ DEM138_SC_HVIL_HW_FLT_BMS05 : 29|2@0+ (1,0) [0|0] ""  PT
 SG_ DEM139_SC_HVIL_OPEN_BMS05 : 31|2@0+ (1,0) [0|0] ""  PT
 SG_ DEM140_SC_HVIL_TO_SUP_BMS05 : 17|2@0+ (1,0) [0|0] ""  PT
 SG_ DEM141_SC_HVIL_TO_CHAS_BMS05 : 19|2@0+ (1,0) [0|0] ""  PT
 SG_ DEM142_SC_HVIL_R_HIGH_BMS05 : 21|2@0+ (1,0) [0|0] ""  PT
 SG_ DEM143_SC_HVIL_SHORT_BMS05 : 23|2@0+ (1,0) [0|0] ""  PT
 SG_ DEM144_SC_CN_ISO_FAIL_BMS05 : 41|2@0+ (1,0) [0|0] ""  PT
 SG_ DEM145_HVIL_SYS_BMS05 : 43|2@0+ (1,0) [0|0] ""  PT
 SG_ DEM146_SC_CN_POS1_WELDED_BMS05 : 45|2@0+ (1,0) [0|0] ""  PT
 SG_ DEM147_SC_CN_NEG1_WELDED_BMS05 : 47|2@0+ (1,0) [0|0] ""  PT
 SG_ DEM148_SC_CN_POS2_WELDED_BMS05 : 33|2@0+ (1,0) [0|0] ""  PT
 SG_ DEM149_SC_CN_NEG2_WELDED_BMS05 : 35|2@0+ (1,0) [0|0] ""  PT
 SG_ DEM150_SC_CN_POS3_WELDED_BMS05 : 37|2@0+ (1,0) [0|0] ""  PT
 SG_ DEM151_SC_CN_NEG3_WELDED_BMS05 : 39|2@0+ (1,0) [0|0] ""  PT
 SG_ DEM152_SC_CN_HIGH_CY_BMS05 : 57|2@0+ (1,0) [0|0] ""  PT
 SG_ DEM153_SC_CN_ISOANDPOTWELD_BMS05 : 59|2@0+ (1,0) [0|0] ""  PT
 SG_ DEM154_SC_TEMP_PLAUSI_BMS05 : 61|2@0+ (1,0) [0|0] ""  PT
 SG_ DEM155_SC_CURR_HALL_PWR_HI_BMS05 : 63|2@0+ (1,0) [0|0] ""  PT
 SG_ DEM156_SC_PYRO_TRIGGERED_BMS05 : 49|2@0+ (1,0) [0|0] ""  PT
 SG_ DEM157_SC_PYRO_OPEN_BMS05 : 51|2@0+ (1,0) [0|0] ""  PT
 SG_ DEM158_AUX_CTRS_END_OF_LIF_BMS05 : 53|2@0+ (1,0) [0|0] ""  PT
 SG_ DEM159_SC_CANRX_PT_MIA_BMS05 : 55|2@0+ (1,0) [0|0] ""  PT

BO_ 1348 BMS05_DebugEventMap6: 8 BMS05
 SG_ DEM160_SC_CANRX_PT_CRCALIV_BMS05 : 9|2@0+ (1,0) [0|0] ""  PT
 SG_ DEM161_SC_CANRX_LIN_SHUTDN_BMS05 : 11|2@0+ (1,0) [0|0] ""  PT
 SG_ DEM162_SC_CANRX_LIN_MIA_BMS05 : 13|2@0+ (1,0) [0|0] ""  PT
 SG_ DEM163_SC_CRASH1_BMS05 : 15|2@0+ (1,0) [0|0] ""  PT
 SG_ DEM164_SC_CRASH2_BMS05 : 1|2@0+ (1,0) [0|0] ""  PT
 SG_ DEM165_SC_CRASHCAN_BMS05 : 3|2@0+ (1,0) [0|0] ""  PT
 SG_ DEM166_SC_CCTRL_SELFTEST_BMS05 : 5|2@0+ (1,0) [0|0] ""  PT
 SG_ DEM167_SC_CCTRL_DRIVER_FAU_BMS05 : 7|2@0+ (1,0) [0|0] ""  PT
 SG_ DEM168_SC_CCTRL_HISIDESTCL_BMS05 : 25|2@0+ (1,0) [0|0] ""  PT
 SG_ DEM169_SC_CCTRL_HISIDESTOP_BMS05 : 27|2@0+ (1,0) [0|0] ""  PT
 SG_ DEM170_SC_CCTRL_LOSIDESTCL_BMS05 : 29|2@0+ (1,0) [0|0] ""  PT
 SG_ DEM171_SC_CCTRL_HVCNDITION_BMS05 : 31|2@0+ (1,0) [0|0] ""  PT
 SG_ DEM172_SC_CCTRL_POS1_OPN_BMS05 : 17|2@0+ (1,0) [0|0] ""  PT
 SG_ DEM173_SC_CCTRL_POS2_OPN_BMS05 : 19|2@0+ (1,0) [0|0] ""  PT
 SG_ DEM174_SC_CCTRL_POS3_OPN_BMS05 : 21|2@0+ (1,0) [0|0] ""  PT
 SG_ DEM175_SC_CCTRL_NEG1_OPN_BMS05 : 23|2@0+ (1,0) [0|0] ""  PT
 SG_ DEM176_SC_CCTRL_NEG2_OPN_BMS05 : 41|2@0+ (1,0) [0|0] ""  PT
 SG_ DEM177_SC_CCTRL_PRE2_OPN_BMS05 : 43|2@0+ (1,0) [0|0] ""  PT
 SG_ DEM178_SC_CCTRL_PRE1_OPN_BMS05 : 45|2@0+ (1,0) [0|0] ""  PT
 SG_ DEM179_SC_CCTRL_LOSIDESTOP_BMS05 : 47|2@0+ (1,0) [0|0] ""  PT
 SG_ DEM180_SC_CCTRL_UNEXPECTED_BMS05 : 33|2@0+ (1,0) [0|0] ""  PT
 SG_ DEM181_SC_V_OUT_OF_RANGE_BMS05 : 35|2@0+ (1,0) [0|0] ""  PT
 SG_ DEM182_SC_V_LATCHED_UVOV_BMS05 : 37|2@0+ (1,0) [0|0] ""  PT
 SG_ DEM183_ISO_EXT_STRAT_2_BMS05 : 39|2@0+ (1,0) [0|0] ""  PT
 SG_ DEM184_SC_CANTX_CTRS_BMS05 : 57|2@0+ (1,0) [0|0] ""  PT
 SG_ DEM185_SC_CANTX_HVIL_BMS05 : 59|2@0+ (1,0) [0|0] ""  PT
 SG_ DEM186_SC_CANTX_ISOL_BMS05 : 61|2@0+ (1,0) [0|0] ""  PT
 SG_ DEM187_SC_SBC_WATCHDOG_BMS05 : 63|2@0+ (1,0) [0|0] ""  PT
 SG_ DEM188_SC_SBC_FAULT_BMS05 : 49|2@0+ (1,0) [0|0] ""  PT
 SG_ DEM189_SC_WATCHDOG_BMS05 : 51|2@0+ (1,0) [0|0] ""  PT
 SG_ DEM190_SC_SELFTEST_RAM_BMS05 : 53|2@0+ (1,0) [0|0] ""  PT
 SG_ DEM191_SC_SELFTEST_FLASH_BMS05 : 55|2@0+ (1,0) [0|0] ""  PT

BO_ 1412 BMS05_DebugEventMap7: 8 BMS05
 SG_ DEM192_CMB_ONBOARDRH_OH_BMS05 : 9|2@0+ (1,0) [0|0] ""  PT
 SG_ DEM193_CMB_ONBOARDRH_SNA_BMS05 : 11|2@0+ (1,0) [0|0] ""  PT
 SG_ DEM194_CMB_ONBOARDT_OT_BMS05 : 13|2@0+ (1,0) [0|0] ""  PT
 SG_ DEM195_CMB_ONBOARDT_CHANGE_BMS05 : 15|2@0+ (1,0) [0|0] ""  PT
 SG_ DEM196_PRESSURE_CHANGE_BMS05 : 1|2@0+ (1,0) [0|0] ""  PT
 SG_ DEM197_PRESSURE_OVER_BMS05 : 3|2@0+ (1,0) [0|0] ""  PT
 SG_ DEM198_PRESSURE_UNDER_BMS05 : 5|2@0+ (1,0) [0|0] ""  PT
 SG_ DEM199_PRESSURE_INVALID_BMS05 : 7|2@0+ (1,0) [0|0] ""  PT
 SG_ DEM200_THERMAL_EVENT_BMS05 : 25|2@0+ (1,0) [0|0] ""  PT
 SG_ DEM201_CMB_ONBOARDT_SNA_BMS05 : 27|2@0+ (1,0) [0|0] ""  PT
 SG_ DEM202_REPLACE_DESICCANT_BMS05 : 29|2@0+ (1,0) [0|0] ""  PT
 SG_ DEM203_COOLANT_FLOOD_FAULT_BMS05 : 31|2@0+ (1,0) [0|0] ""  PT
 SG_ DEM204_LOW_BRICKCAPACITY_BMS05 : 17|2@0+ (1,0) [0|0] ""  PT
 SG_ DEM205_BMS_ONBOARDT_OT_BMS05 : 19|2@0+ (1,0) [0|0] ""  PT
 SG_ DEM206_HUMIDITY_CHANGE_BMS05 : 21|2@0+ (1,0) [0|0] ""  PT
 SG_ DEM207_ISENSE_SUPPLY_CURR_BMS05 : 23|2@0+ (1,0) [0|0] ""  PT
 SG_ DEM208_SOC_LOW_BMS05 : 41|2@0+ (1,0) [0|0] ""  PT
 SG_ DEM209_SOC_TOOLOW_BMS05 : 43|2@0+ (1,0) [0|0] ""  PT
 SG_ DEM210_SOC_TOOHIGH_BMS05 : 45|2@0+ (1,0) [0|0] ""  PT
 SG_ DEM211_BALANCING_REQUIRED_BMS05 : 47|2@0+ (1,0) [0|0] ""  PT
 SG_ DEM212_DEEP_DISCHARGE_BMS05 : 33|2@0+ (1,0) [0|0] ""  PT
 SG_ DEM213_CAN1_BUS_OFF_BMS05 : 35|2@0+ (1,0) [0|0] ""  PT
 SG_ DEM214_CAN2_BUS_OFF_BMS05 : 37|2@0+ (1,0) [0|0] ""  PT
 SG_ DEM215_CAN3_BUS_OFF_BMS05 : 39|2@0+ (1,0) [0|0] ""  PT
 SG_ DEM216_OUTLET_NTC_RATNAL_BMS05 : 57|2@0+ (1,0) [0|0] ""  PT
 SG_ DEM217_FUSE_PACK_BMS05 : 59|2@0+ (1,0) [0|0] ""  PT
 SG_ DEM218_FUSE_B_OPEN_BMS05 : 61|2@0+ (1,0) [0|0] ""  PT
 SG_ DEM219_FUSE_C_OPEN_BMS05 : 63|2@0+ (1,0) [0|0] ""  PT
 SG_ DEM220_FUSE_D_OPEN_BMS05 : 49|2@0+ (1,0) [0|0] ""  PT
 SG_ DEM221_FUSE_E_OPEN_BMS05 : 51|2@0+ (1,0) [0|0] ""  PT
 SG_ DEM222_PUMP_DRY_RUN_BMS05 : 53|2@0+ (1,0) [0|0] ""  PT
 SG_ DEM223_PUMP_PERFORMANCE_BMS05 : 55|2@0+ (1,0) [0|0] ""  PT

BO_ 1476 BMS05_DebugEventMap8: 8 BMS05
 SG_ DEM224_PUMP_LIN_FAILURE_BMS05 : 9|2@0+ (1,0) [0|0] ""  PT
 SG_ DEM225_PUMP_SUPPLY_VOLTAGE_BMS05 : 11|2@0+ (1,0) [0|0] ""  PT
 SG_ DEM226_PUMP_RECOVERY_FAIL_BMS05 : 13|2@0+ (1,0) [0|0] ""  PT
 SG_ DEM227_CTR_POS_OPENED_BMS05 : 15|2@0+ (1,0) [0|0] ""  PT
 SG_ DEM228_CTR_NEG_OPENED_BMS05 : 1|2@0+ (1,0) [0|0] ""  PT
 SG_ DEM229_STRSET_SLAVE1_FAULT_BMS05 : 3|2@0+ (1,0) [0|0] ""  PT
 SG_ DEM230_STRSET_SLAVE2_FAULT_BMS05 : 5|2@0+ (1,0) [0|0] ""  PT
 SG_ DEM231_CTRSAUX_CLFAIL_HVON_BMS05 : 7|2@0+ (1,0) [0|0] ""  PT
 SG_ DEM232_CTRSAUX_CLFAIL_VDIF_BMS05 : 25|2@0+ (1,0) [0|0] ""  PT
 SG_ DEM233_CTRSAUX_POS1_OPENED_BMS05 : 27|2@0+ (1,0) [0|0] ""  PT
 SG_ DEM234_CTRSAUX_NEG1_OPENED_BMS05 : 29|2@0+ (1,0) [0|0] ""  PT
 SG_ DEM235_CTRSAUX_POS1_WELDED_BMS05 : 31|2@0+ (1,0) [0|0] ""  PT
 SG_ DEM236_CTRSAUX_NEG1_WELDED_BMS05 : 17|2@0+ (1,0) [0|0] ""  PT
 SG_ DEM237_CTRSAUX_POS1_PULLIN_BMS05 : 19|2@0+ (1,0) [0|0] ""  PT
 SG_ DEM238_CTRSAUX_NEG1_PULLIN_BMS05 : 21|2@0+ (1,0) [0|0] ""  PT
 SG_ DEM239_INLET_NTC_RATNAL_BMS05 : 23|2@0+ (1,0) [0|0] ""  PT
 SG_ DEM240_INLET_NTC_HI_BMS05 : 41|2@0+ (1,0) [0|0] ""  PT
 SG_ DEM241_INLET_NTC_LO_BMS05 : 43|2@0+ (1,0) [0|0] ""  PT
 SG_ DEM242_VOLTAGE_LINK2_RATNA_BMS05 : 45|2@0+ (1,0) [0|0] ""  PT
 SG_ DEM243_VOLTAGE_LINK2_HI_BMS05 : 47|2@0+ (1,0) [0|0] ""  PT
 SG_ DEM244_VOLTAGE_LINK2_LO_BMS05 : 33|2@0+ (1,0) [0|0] ""  PT
 SG_ DEM245_CMB_ONBOARD_IMPOSSI_BMS05 : 35|2@0+ (1,0) [0|0] ""  PT
 SG_ DEM246_VOLTAGE_LINK1_HI_BMS05 : 37|2@0+ (1,0) [0|0] ""  PT
 SG_ DEM247_VOLTAGE_LINK1_LO_BMS05 : 39|2@0+ (1,0) [0|0] ""  PT
 SG_ DEM248_NTC_SUPPLY_LO_BMS05 : 57|2@0+ (1,0) [0|0] ""  PT
 SG_ DEM249_NTC_SUPPLY_HI_BMS05 : 59|2@0+ (1,0) [0|0] ""  PT
 SG_ DEM250_VOLTAGE_LINK3_RATNA_BMS05 : 61|2@0+ (1,0) [0|0] ""  PT
 SG_ DEM251_VOLTAGE_LINK3_HI_BMS05 : 63|2@0+ (1,0) [0|0] ""  PT
 SG_ DEM252_VOLTAGE_LINK3_LO_BMS05 : 49|2@0+ (1,0) [0|0] ""  PT
 SG_ DEM253_BALANCING_STUCK_BMS05 : 51|2@0+ (1,0) [0|0] ""  PT
 SG_ DEM254_ARM_EXCEPTION_BMS05 : 53|2@0+ (1,0) [0|0] ""  PT
 SG_ DEM255_ERROR_HOOKS_BMS05 : 55|2@0+ (1,0) [0|0] ""  PT

BO_ 836 BMS05_DebugEventMap9: 8 BMS05
 SG_ DEM256_XCP_CAL_CHANGE_BMS05 : 9|2@0+ (1,0) [0|0] ""  PT
 SG_ DEM257_XCP_CAL_PERM_CHANGE_BMS05 : 11|2@0+ (1,0) [0|0] ""  PT
 SG_ DEM258_TASK_TIME_OVERFLOW_BMS05 : 13|2@0+ (1,0) [0|0] ""  PT
 SG_ DEM259_ISO_CIRCUIT_BMS05 : 15|2@0+ (1,0) [0|0] ""  PT
 SG_ DEM260_COOLANT_MOIST_FAULT_BMS05 : 1|2@0+ (1,0) [0|0] ""  PT
 SG_ DEM261_COOLANT_FLOOD_WARN_BMS05 : 3|2@0+ (1,0) [0|0] ""  PT
 SG_ DEM262_COOLANT_MOIST_WARN_BMS05 : 5|2@0+ (1,0) [0|0] ""  PT
 SG_ DEM263_MODULET_IMPLAUSIBLE_BMS05 : 7|2@0+ (1,0) [0|0] ""  PT
 SG_ DEM264_REQUEST_ON_WITH_HV__BMS05 : 25|2@0+ (1,0) [0|0] ""  PT
 SG_ DEM265_CSERS_PCODE_BMS05 : 27|2@0+ (1,0) [0|0] ""  PT
 SG_ DEM266_PRELIM_CNTR_CL_FAIL_BMS05 : 29|2@0+ (1,0) [0|0] ""  PT
 SG_ DEM267_FLUIDLVL_LOW_BMS05 : 31|2@0+ (1,0) [0|0] ""  PT
 SG_ DEM268_FLUIDLVL_FAILURE_BMS05 : 17|2@0+ (1,0) [0|0] ""  PT
 SG_ DEM269_SC_COOLANT_CONTAM_BMS05 : 19|2@0+ (1,0) [0|0] ""  PT
 SG_ DEM270_SC_COOLANT_MIA_BMS05 : 21|2@0+ (1,0) [0|0] ""  PT
 SG_ DEM271_PRESSURE_VHI_BMS05 : 23|2@0+ (1,0) [0|0] ""  PT
 SG_ DEM272_PRESSURE_VLO_BMS05 : 41|2@0+ (1,0) [0|0] ""  PT
 SG_ DEM273_SC_COOLANT_FAIL_BMS05 : 43|2@0+ (1,0) [0|0] ""  PT
 SG_ DEM274_CTRSAUX_POS2_OPENED_BMS05 : 45|2@0+ (1,0) [0|0] ""  PT
 SG_ DEM275_CTRSAUX_POS3_OPENED_BMS05 : 47|2@0+ (1,0) [0|0] ""  PT
 SG_ DEM276_CTRSAUX_POS2_WELDED_BMS05 : 33|2@0+ (1,0) [0|0] ""  PT
 SG_ DEM277_CTRSAUX_POS3_WELDED_BMS05 : 35|2@0+ (1,0) [0|0] ""  PT
 SG_ DEM278_CTRSAUX_POS2_PULLIN_BMS05 : 37|2@0+ (1,0) [0|0] ""  PT
 SG_ DEM279_CTRSAUX_POS3_PULLIN_BMS05 : 39|2@0+ (1,0) [0|0] ""  PT
 SG_ DEM280_CMB_HUMIDITY_TEMP_C_BMS05 : 57|2@0+ (1,0) [0|0] ""  PT
 SG_ DEM281_THERMAL_EVENT_CMB_R_BMS05 : 59|2@0+ (1,0) [0|0] ""  PT
 SG_ DEM282_CUS_BRICKOV_BMS05 : 61|2@0+ (1,0) [0|0] ""  PT
 SG_ DEM283_CUS_BRICKUV_BMS05 : 63|2@0+ (1,0) [0|0] ""  PT
 SG_ DEM284_CUS_OVERCHRG_BMS05 : 49|2@0+ (1,0) [0|0] ""  PT
 SG_ DEM285_CUS_OVERDCHRG_BMS05 : 51|2@0+ (1,0) [0|0] ""  PT
 SG_ DEM286_CUS_CURRENT_CHG_BMS05 : 53|2@0+ (1,0) [0|0] ""  PT
 SG_ DEM287_CUS_CURRENT_DCHG_BMS05 : 55|2@0+ (1,0) [0|0] ""  PT

BO_ 1604 SC05_DebugSlowMpex: 8 SC05
 SG_ FeeInitStatus_SC05 m43 : 23|16@0+ (1,0) [0|65535] ""  PT
 SG_ pressureFiltered_SC05 m22 : 47|8@0+ (0.4,0) [0|102] "psi"  PT
 SG_ shunt2IntegralAs_SC05 m46 : 23|32@0- (1,0) [-2147483648|2147483647] "As"  PT
 SG_ shunt1IntegralAs_SC05 m45 : 31|32@0- (1,0) [-2147483648|2147483647] "As"  PT
 SG_ selfTestStartupFault_SC05 m22 : 39|8@0+ (1,0) [0|255] ""  PT
 SG_ sbcARTimerStatus_SC05 m45 : 11|4@0+ (1,0) [0|15] ""  PT
 SG_ sbcARTimerValue_SC05 m45 : 23|8@0+ (1,0) [0|255] "s"  PT
 SG_ ESM_EFUSE_SAFETY_CHECK_FAIL_SC05 m21 : 41|1@0+ (1,0) [0|0] ""  PT
 SG_ ESM_EFUSE_SINGLEBIT_ERROR_SC05 m21 : 42|1@0+ (1,0) [0|0] ""  PT
 SG_ cmbVAIndex_SC05 m44 : 31|8@0+ (1,0) [0|0] ""  PT
 SG_ minVACMB_SC05 m44 : 39|16@0+ (0.0001,0) [0|6.5] "V"  PT
 SG_ maxVACMB_SC05 m44 : 55|16@0+ (0.0001,0) [0|6.5] "V"  PT
 SG_ pumpInternalFaultError_SC05 m23 : 16|1@0+ (1,0) [0|0] ""  PT
 SG_ pumpShortCircuitError_SC05 m23 : 17|1@0+ (1,0) [0|0] ""  PT
 SG_ pumpElectricError_SC05 m23 : 19|2@0+ (1,0) [0|0] ""  PT
 SG_ pumpPostRunMode_SC05 m23 : 22|3@0+ (1,0) [0|0] ""  PT
 SG_ pumpRsError_SC05 m23 : 23|1@0+ (1,0) [0|0] ""  PT
 SG_ pumpWakeUpStatus_SC05 m23 : 25|2@0+ (1,0) [0|0] ""  PT
 SG_ pumpRpmMonStat_SC05 m23 : 27|2@0+ (1,0) [0|0] ""  PT
 SG_ pumpPwmInStat_SC05 m23 : 29|2@0+ (1,0) [0|0] ""  PT
 SG_ pumpDiagTriggered_SC05 m23 : 30|1@0+ (1,0) [0|0] ""  PT
 SG_ pumpHwFault_SC05 m23 : 31|1@0+ (1,0) [0|0] ""  PT
 SG_ pumpPumpState_SC05 m23 : 34|3@0+ (1,0) [0|0] ""  PT
 SG_ pumpBlockError_SC05 m23 : 36|2@0+ (1,0) [0|0] ""  PT
 SG_ pumpLinError_SC05 m23 : 37|1@0+ (1,0) [0|0] ""  PT
 SG_ pumpDryRun_SC05 m23 : 39|2@0+ (1,0) [0|0] ""  PT
 SG_ pumpOverCurrent_SC05 m23 : 41|2@0+ (1,0) [0|0] ""  PT
 SG_ pumpVoltageDeratingError_SC05 m23 : 42|1@0+ (1,0) [0|0] ""  PT
 SG_ pumpSupVoltageError_SC05 m23 : 44|2@0+ (1,0) [0|0] ""  PT
 SG_ pumpUnderVoltage_SC05 m23 : 45|1@0+ (1,0) [0|0] ""  PT
 SG_ pumpOverVoltage_SC05 m23 : 46|1@0+ (1,0) [0|0] ""  PT
 SG_ pumpTempProtect_SC05 m23 : 47|1@0+ (1,0) [0|0] ""  PT
 SG_ pumpOverTempDeratingErr_SC05 m23 : 48|1@0+ (1,0) [0|0] ""  PT
 SG_ pumpOverTemperature_SC05 m23 : 50|2@0+ (1,0) [0|0] ""  PT
 SG_ cmbSM30MinSettleTime_SC05 m44 : 15|16@0+ (1,0) [0|65535] "ms"  PT
 SG_ cmbSM30SettleTimeFault_SC05 m32 : 42|1@0+ (1,0) [0|1] ""  PT
 SG_ pressure2_SC05 m22 : 15|8@0+ (0.4,0) [0|102] "psi"  PT
 SG_ cmbSM29ScoutTempIndex_SC05 m42 : 15|8@0+ (1,0) [0|255] ""  PT
 SG_ cmbSM19ScoutPDO_SC05 m42 : 55|16@0+ (0.0001,0) [0|6.5] "V"  PT
 SG_ cmbMaxSM15ratio_SC05 m41 : 39|16@0+ (0.00390625,0) [0|255.99609375] ""  PT
 SG_ cmbMinSM15ratio_SC05 m41 : 55|16@0+ (0.00390625,0) [0|255.99609375] ""  PT
 SG_ cmbMinSM17Ratio m42 : 39|16@0+ (0.00390625,0) [0|255.99609375] ""  PT
 SG_ cmbMaxSM17Ratio m42 : 23|16@0+ (0.00390625,0) [0|255.99609375] ""  PT
 SG_ cmbMaxSM16DiffC2S_SC05 m41 : 23|16@0+ (0.2,0) [0|13107] "mV"  PT
 SG_ isolationResInternRelaxed_SC05 m32 : 23|16@0+ (2,0) [0|130000] "kOhm"  PT
 SG_ pressureSensH2Concentr_SC05 m40 : 55|16@0+ (0.0025,0) [0|163.8375] "% H2"  PT
 SG_ pressureSensIntakePres_SC05 m40 : 39|16@0+ (0.0078125,-250) [-250|251.99] "kPa"  PT
 SG_ pressureSensIntakeTemp_SC05 m40 : 23|16@0+ (0.03125,-273) [-273|1734.96875] "C"  PT
 SG_ pressureSensRelHumidity_SC05 m40 : 15|8@0+ (0.4,0) [0|100] "%"  PT
 SG_ isolationSelftestMaxDiff_SC05 m32 : 39|8@0+ (0.1,0) [0|25.5] "V"  PT
 SG_ FEESector2Flags_SC05 m22 : 23|16@0+ (1,0) [0|0] ""  PT
 SG_ appTask500HzMaxAvg_SC05 m41 : 15|8@0+ (0.02,0) [0|5.1] "ms"  PT
 SG_ safetyHangLastLinkReg_SC05 m39 : 23|32@0+ (1,0) [0|4294967295] ""  PT
 SG_ safetyHangPresentLinkReg_SC05 m38 : 23|32@0+ (1,0) [0|4294967295] ""  PT
 SG_ safetyHangDataFaultStatus_SC05 m37 : 23|32@0+ (1,0) [0|4294967295] ""  PT
 SG_ safetyHangDataFaultAddr_SC05 m36 : 23|32@0+ (1,0) [0|4294967295] ""  PT
 SG_ safetyHangLastARMMode_SC05 m35 : 63|8@0+ (1,0) [0|255] ""  PT
 SG_ safetyHangPresARMMode_SC05 m35 : 55|8@0+ (1,0) [0|255] ""  PT
 SG_ safetyHangESMGrp3Reg_SC05 m35 : 23|32@0+ (1,0) [0|4294967295] ""  PT
 SG_ safetyHangInstrFaultStatus_SC05 m34 : 23|32@0+ (1,0) [0|4294967295] ""  PT
 SG_ safetyHangInstrFaultAddr_SC05 m33 : 23|32@0+ (1,0) [0|4294967295] ""  PT
 SG_ pressure_SC05 m4 : 63|8@0+ (0.4,0) [0|102] "psi"  PT
 SG_ cmbMaxSM33Diff_SC05 m31 : 15|8@0+ (0.001,0) [0|0.255] "V"  PT
 SG_ cmbMinSM29Diff_SC05 m17 : 15|8@0+ (0.001,0) [0|0.255] "V"  PT
 SG_ cmbSM4MinIndex_SC05 m24 : 15|8@0+ (1,0) [0|0] ""  PT
 SG_ cmbSM4DiffC2_SC05 m31 : 23|16@0+ (0.0001,0) [0|6.5] "V"  PT
 SG_ cmbMinSM4Diff_SC05 m31 : 39|16@0+ (0.0001,0) [0|6.5] "V"  PT
 SG_ cmbMaxSM4Diff_SC05 m21 : 55|16@0+ (0.0001,0) [0|6.5] "V"  PT
 SG_ cmbSM27MinIndex_SC05 m15 : 63|8@0+ (1,0) [0|0] ""  PT
 SG_ cmbSM27DiffC2_SC05 m24 : 55|16@0+ (0.0001,0) [0|6.5] "V"  PT
 SG_ cmbMinSM27Diff_SC05 m31 : 55|16@0+ (0.0001,0) [0|6.5] "V"  PT
 SG_ cmbMaxSM27Diff_SC05 m25 : 55|16@0+ (0.0001,0) [0|6.5] "V"  PT
 SG_ adcDriverFail_SC05 m4 : 51|4@0+ (1,0) [0|0] ""  PT
 SG_ mainUcHvilState_SC05 m32 : 41|2@0+ (1,0) [0|0] ""  PT
 SG_ mainUcIntIsoErr_SC05 m32 : 13|2@0+ (1,0) [0|0] ""  PT
 SG_ mainUcExtIsoErr_SC05 m32 : 15|2@0+ (1,0) [0|0] ""  PT
 SG_ safetyUcThermalStatus_SC05 m32 : 9|2@0+ (1,0) [0|0] ""  PT
 SG_ mainUcThermalStatus_SC05 m32 : 11|2@0+ (1,0) [0|0] ""  PT
 SG_ selfTestErrorAddress_SC05 m30 : 23|32@0+ (1,0) [0|4294967295] ""  PT
 SG_ selfTestDataFaultStatus_SC05 m29 : 23|32@0+ (1,0) [0|4294967295] ""  PT
 SG_ selfTestInstrFaultAddr_SC05 m28 : 23|32@0+ (1,0) [0|4294967295] ""  PT
 SG_ selfTestDataFaultAddr_SC05 m27 : 23|32@0+ (1,0) [0|4294967295] ""  PT
 SG_ selfTestInstrFaultStatus_SC05 m26 : 23|32@0+ (1,0) [0|4294967295] ""  PT
 SG_ internalIsolationError_SC05 m25 : 11|2@0+ (1,0) [0|0] ""  PT
 SG_ externalIsolationError_SC05 m25 : 13|2@0+ (1,0) [0|0] ""  PT
 SG_ isolationTestState_SC05 m25 : 9|2@0+ (1,0) [0|0] ""  PT
 SG_ isolationResistanceIntern_SC05 m25 : 23|16@0+ (2,0) [0|130000] "kOhm"  PT
 SG_ isolationResistanceExtern_SC05 m25 : 39|16@0+ (2,0) [0|130000] "kOhm"  PT
 SG_ maxAdolV13Diff_SC05 m24 : 23|16@0+ (0.0001,0) [0|6.5] "V"  PT
 SG_ maxAdolV7Diff_SC05 m24 : 39|16@0+ (0.0001,0) [0|6.5] "V"  PT
 SG_ pumpType_SC05 m23 : 15|8@0+ (1,0) [0|0] ""  PT
 SG_ pumpPhaseCurrent_SC05 m18 : 47|8@0+ (0.1,0) [0|0] "A"  PT
 SG_ hvWithstandTestQual_SC05 m21 : 15|8@0+ (1,0) [0|255] ""  PT
 SG_ ESM_RAM_ODD_ADDR_UNCORR_SC05 m21 : 18|1@0+ (1,0) [0|0] ""  PT
 SG_ ESM_RAM_EVEN_ADDR_UNCORR_SC05 m21 : 17|1@0+ (1,0) [0|0] ""  PT
 SG_ ESM_FMC_UNCORR_ERR_SC05 m21 : 40|1@0+ (1,0) [0|0] ""  PT
 SG_ ESM_RAM_ODDECC_UNCORR_SC05 m21 : 23|1@0+ (1,0) [0|0] ""  PT
 SG_ ESM_RAM_EVENECC_UNCORR_SC05 m21 : 22|1@0+ (1,0) [0|0] ""  PT
 SG_ ESM_EFUSE_FARM_ERR_SC05 m21 : 21|1@0+ (1,0) [0|0] ""  PT
 SG_ ESM_RTI_WWD_NMI_SC05 m21 : 20|1@0+ (1,0) [0|0] ""  PT
 SG_ ESM_TCM_ECC_LIVE_LOCK_SC05 m21 : 19|1@0+ (1,0) [0|0] ""  PT
 SG_ ESM_RAM_ODD_UNCORR_ERR_SC05 m21 : 16|1@0+ (1,0) [0|0] ""  PT
 SG_ ESM_RAM_EVEN_UNCORR_ERR_SC05 m21 : 31|1@0+ (1,0) [0|0] ""  PT
 SG_ ESM_FMC_ADDR_UNCORR_ERR_SC05 m21 : 30|1@0+ (1,0) [0|0] ""  PT
 SG_ ESM_CCM4_COMPARE_FAULT_SC05 m21 : 29|1@0+ (1,0) [0|0] ""  PT
 SG_ ESM_RAM_ODD_CORR_ERR_SC05 m21 : 28|1@0+ (1,0) [0|0] ""  PT
 SG_ ESM_RAM_EVEN_CORR_ERR_SC05 m21 : 27|1@0+ (1,0) [0|0] ""  PT
 SG_ ESM_CLK_MONITOR_SC05 m21 : 26|1@0+ (1,0) [0|0] ""  PT
 SG_ ESM_PLL_SLIP_SC05 m21 : 25|1@0+ (1,0) [0|0] ""  PT
 SG_ ESM_FMC_CORR_ERR_SC05 m21 : 24|1@0+ (1,0) [0|0] ""  PT
 SG_ analogMMCUSleepTrigger_SC05 m20 : 55|8@0+ (0.015,0) [0|0] "V"  PT
 SG_ analogPyroLSDStatus_SC05 m20 : 63|8@0+ (0.015,0) [0|0] "V"  PT
 SG_ analogGPIO2Volt_SC05 m19 : 47|8@0+ (0.1,0) [0|25] "V"  PT
 SG_ analogGPIO2Current_SC05 m19 : 55|8@0+ (0.015,0) [0|3.825] "A"  PT
 SG_ analogGPIO1Volt_SC05 m19 : 63|8@0+ (0.1,0) [0|25] "V"  PT
 SG_ analogGPIO1Current_SC05 m20 : 15|8@0+ (0.015,0) [0|3.825] "A"  PT
 SG_ currentModuleMax_SC05 m1 : 55|16@0+ (0.1,-3200) [-3200|3200] "A"  PT
 SG_ currentModuleMin_SC05 m1 : 39|16@0+ (0.1,-3200) [-3200|3200] "A"  PT
 SG_ cmbSumOfCellSTATRef_SC05 m20 : 39|16@0+ (0.0015,0) [0|131.07] "V"  PT
 SG_ cmbSumOfCells_SC05 m20 : 23|16@0+ (0.0015,0) [0|131.07] "V"  PT
 SG_ maxCMBDieTemp_SC05 m1 : 31|8@0+ (1,-40) [-40|200] "C"  PT
 SG_ minCMBDieTemp_SC05 m1 : 23|8@0+ (1,-40) [-40|200] "C"  PT
 SG_ appTaskSpiRxTx_SC05 m16 : 15|8@0+ (0.02,0) [0|5.1] "ms"  PT
 SG_ variantCodingCounts_SC05 m4 : 39|8@0+ (1,0) [0|0] ""  PT
 SG_ cmbMaxUpdateTime_SC05 m17 : 23|8@0+ (2,0) [0|500] "ms"  PT
 SG_ pumpSetSpeed_SC05 m18 : 55|8@0+ (1,0) [0|255] "PCT"  PT
 SG_ hvilResistance_SC05 m17 : 31|8@0+ (2,0) [0|0] "Ohm"  PT
 SG_ cmbAvgUpdateTime_SC05 m18 : 63|8@0+ (2,0) [0|500] "ms"  PT
 SG_ pumpTemperature_SC05 m18 : 39|8@0+ (1,-50) [0|0] "C"  PT
 SG_ pumpSpeed_SC05 m18 : 15|8@0+ (1,0) [0|255] "PCT"  PT
 SG_ pumpVoltage_SC05 m18 : 23|8@0+ (0.1,0) [0|0] "V"  PT
 SG_ pumpCurrent_SC05 m18 : 31|8@0+ (0.1,0) [0|0] "A"  PT
 SG_ posLink3_SC05 m17 : 39|16@0+ (0.04,-1250) [-1250|1371.4] "V"  PT
 SG_ negLink3_SC05 m17 : 55|16@0+ (0.04,-1250) [-1250|1371.4] "V"  PT
 SG_ posLink2_SC05 m16 : 39|16@0+ (0.04,-1250) [-1250|1371.4] "V"  PT
 SG_ negLink2_SC05 m16 : 55|16@0+ (0.04,-1250) [-1250|1371.4] "V"  PT
 SG_ cmbNrOfSamples_SC05 m16 : 23|8@0+ (1,0) [0|0] ""  PT
 SG_ cmbTaskTime_SC05 m16 : 31|8@0+ (1,0) [0|0] "ms"  PT
 SG_ appTask500HzMax_SC05 m15 : 15|8@0+ (0.02,0) [0|5.1] "ms"  PT
 SG_ moduleCount_SC05 m6 : 15|8@0+ (1,0) [0|0] ""  PT
 SG_ analogHallSense_SC05 m15 : 23|16@0+ (0.0001,0) [0|6.5535] "V"  PT
 SG_ cmbMaxDiagStepPeriodicity_SC05 m15 : 55|8@0+ (4,0) [0|1019] "ms"  PT
 SG_ minBrickVoltageLimit_SC05 m15 : 39|16@0+ (0.0001,0) [0|6.5535] "V"  PT
 SG_ appTask100Hz_SC05 m14 : 63|8@0+ (0.02,0) [0|5.1] "ms"  PT
 SG_ appTask10Hz_SC05 m14 : 55|8@0+ (0.02,0) [0|5.1] "ms"  PT
 SG_ appTaskAnalog_SC05 m14 : 47|8@0+ (0.02,0) [0|5.1] "ms"  PT
 SG_ appTaskADC_SC05 m14 : 39|8@0+ (0.02,0) [0|5.1] "ms"  PT
 SG_ appTask500HzAvg_SC05 m14 : 31|8@0+ (0.02,0) [0|5.1] "ms"  PT
 SG_ appTaskSBC_SC05 m14 : 23|8@0+ (0.02,0) [0|5.1] "ms"  PT
 SG_ appTaskCMBDriver_SC05 m14 : 15|8@0+ (0.02,0) [0|5.1] "ms"  PT
 SG_ safetyInitTime_SC05 m12 : 15|8@0+ (2,0) [0|500] "ms"  PT
 SG_ debugSlowMpex_SC05 M : 7|8@0+ (1,0) [0|0] ""  PT
 SG_ sbcWUAuto_SC05 m11 : 9|1@0+ (1,0) [0|0] ""  PT
 SG_ sbcWUUnknown_SC05 m11 : 8|1@0+ (1,0) [0|0] ""  PT
 SG_ sbcWUDebug_SC05 m11 : 10|1@0+ (1,0) [0|0] ""  PT
 SG_ sbcWUPOR_SC05 m11 : 11|1@0+ (1,0) [0|0] ""  PT
 SG_ sbcWUPressure_SC05 m11 : 12|1@0+ (1,0) [0|0] ""  PT
 SG_ sbcWUClock_SC05 m11 : 13|1@0+ (1,0) [0|0] ""  PT
 SG_ sbcWUCAN_SC05 m11 : 14|1@0+ (1,0) [0|0] ""  PT
 SG_ sbcWUKey_SC05 m11 : 15|1@0+ (1,0) [0|0] ""  PT
 SG_ mux960N3VRef_SC05 m13 : 39|16@0+ (-0.000805664,0) [0|0] "V"  PT
 SG_ mux960P2P5VRef_SC05 m13 : 55|16@0+ (0.000805664,0) [0|0] "V"  PT
 SG_ mux440Gnd_SC05 m10 : 15|8@0+ (0.000805664,0) [0|0] "V"  PT
 SG_ analogHallGain_SC05 m13 : 23|16@0+ (1E-005,0.8) [0.8|1.455] "k"  PT
 SG_ analogHallOffset_SC05 m13 : 15|8@0+ (0.0001,-0.005) [-0.005|0.0205] "V"  PT
 SG_ negPackPrime_SC05 m12 : 55|16@0+ (0.04,-1250) [-1250|1250] "V"  PT
 SG_ posPackPrime_SC05 m12 : 39|16@0+ (0.04,-1250) [-1250|1250] "V"  PT
 SG_ packVoltage_SC05 m12 : 23|16@0+ (0.04,-1250) [-1250|1250] "V"  PT
 SG_ sleepTime_SC05 m11 : 23|16@0+ (1,0) [0|0] "s"  PT
 SG_ analogNegHVOffset_SC05 m10 : 63|8@0+ (1,-120) [-120|120] "Bits"  PT
 SG_ analogPosHVOffset_SC05 m10 : 55|8@0+ (1,-120) [-120|120] "Bits"  PT
 SG_ analogNegHVGain_SC05 m10 : 39|16@0+ (1E-005,0.8) [0|0] "k"  PT
 SG_ analogPosHVGain_SC05 m10 : 23|16@0+ (1E-005,0.8) [0.8|1.45535] "k"  PT
 SG_ mux910Gnd_SC05 m8 : 15|8@0+ (0.000805664,0) [0|0] "V"  PT
 SG_ mux960Gnd_SC05 m9 : 15|8@0+ (0.000805664,0) [0|0] "V"  PT
 SG_ analogAddr5_SC05 m9 : 55|16@0+ (0.000805861,0) [0|0] "V"  PT
 SG_ analogAddr4_SC05 m9 : 39|16@0+ (0.000805861,0) [0|0] "V"  PT
 SG_ analogAddr3_SC05 m9 : 23|16@0+ (0.000805861,0) [0|0] "V"  PT
 SG_ analogAddr2_SC05 m8 : 55|16@0+ (0.000805861,0) [0|0] "V"  PT
 SG_ analogAddr1_SC05 m8 : 39|16@0+ (0.000805861,0) [0|0] "V"  PT
 SG_ analogAddr0_SC05 m8 : 23|16@0+ (0.000805861,0) [0|0] "V"  PT
 SG_ sbcVREF2P5_SC05 m7 : 15|8@0+ (0.003222656,2.25) [2.25|3.0715] "V"  PT
 SG_ mux910N3VRef_SC05 m7 : 39|16@0+ (-0.000805664,0) [0|0] "V"  PT
 SG_ mux910P2P5VRef_SC05 m7 : 55|16@0+ (0.000805664,0) [0|0] "V"  PT
 SG_ analogHvilCurrentPWM_SC05 m3 : 31|8@0+ (1,0) [0|255] "mA"  PT
 SG_ analogSBCSupply_SC05 m4 : 47|8@0+ (0.1,0) [0|25] "V"  PT
 SG_ analogHvilCurrent_SC05 m3 : 23|8@0+ (1,0) [0|255] "mA"  PT
 SG_ analogPressureSense_SC05 m4 : 23|8@0+ (0.025,0) [0|6.375] "V"  PT
 SG_ analog5VSensorSupply_SC05 m4 : 15|8@0+ (0.025,0) [0|6.375] "V"  PT
 SG_ analogPrechgRel2CoilMinus_SC05 m2 : 23|8@0+ (0.2,0) [0|51] "V"  PT
 SG_ analogPrechgRel1CoilMinus_SC05 m3 : 55|8@0+ (0.2,0) [0|51] "V"  PT
 SG_ analogNegCntr3CoilMinus_SC05 m2 : 31|8@0+ (0.2,0) [0|51] "V"  PT
 SG_ analogNegCntr2CoilMinus_SC05 m2 : 39|8@0+ (0.2,0) [0|51] "V"  PT
 SG_ analogNegCntr1CoilMinus_SC05 m2 : 47|8@0+ (0.2,0) [0|51] "V"  PT
 SG_ analogPosCntr3CoilMinus_SC05 m2 : 55|8@0+ (0.2,0) [0|51] "V"  PT
 SG_ analogPosCntr2CoilMinus_SC05 m2 : 63|8@0+ (0.2,0) [0|51] "V"  PT
 SG_ analogPosCntr1CoilMinus_SC05 m3 : 15|8@0+ (0.2,0) [0|51] "V"  PT
 SG_ minModuleTemperature_SC05 m1 : 15|8@0+ (1,-40) [-40|200] "C"  PT
 SG_ maxModuleTemperature_SC05 m2 : 15|8@0+ (1,-40) [-40|200] "C"  PT
 SG_ analogHvilReturn_SC05 m3 : 39|8@0+ (0.1,0) [0|25] "V"  PT
 SG_ analog5VDSupply_SC05 m3 : 47|8@0+ (0.025,0) [0|6.375] "V"  PT
 SG_ analogHvilOut_SC05 m3 : 63|8@0+ (0.1,0) [0|25] "V"  PT
 SG_ analogCurrentSensor12V_SC05 m4 : 31|8@0+ (0.075,0) [0|19] "V"  PT
 SG_ cmbErrorCounter_SC05 m6 : 47|8@0+ (1,0) [0|255] ""  PT
 SG_ PECErrorCounter_SC05 m6 : 39|8@0+ (1,0) [0|255] ""  PT
 SG_ maxVREF2_SC05 m7 : 23|16@0+ (0.0001,0) [0|6.5] "V"  PT
 SG_ minVREF2_SC05 m6 : 55|16@0+ (0.0001,0) [0|6.5] "V"  PT
 SG_ currentPlausiCounter_SC05 m5 : 15|8@0+ (1,0) [0|0] ""  PT
 SG_ hallCurrentOffset_SC05 m5 : 39|16@0+ (0.001,-30) [-30|30] "A"  PT
 SG_ sumOfCurrentsFiltered_SC05 m5 : 23|16@0+ (0.1,-3200) [-3200|3353.5] "A"  PT
 SG_ hallCurrentAveraged_SC05 m5 : 55|16@0+ (0.1,-3200) [-3200|3200] "A"  PT
 SG_ analogHallSupply_SC05 m6 : 23|16@0+ (0.0005,0) [0|32.7675] "V"  PT
 SG_ SWVersion_SC05 m11 : 39|32@0+ (1,0) [0|4294967295] ""  PT
 SG_ contactorControlPos1_SC05 m19 : 23|4@0+ (1,0) [0|7] ""  PT
 SG_ contactorControlNeg1_SC05 m19 : 19|4@0+ (1,0) [0|7] ""  PT
 SG_ contactorControlPre1_SC05 m19 : 11|4@0+ (1,0) [0|7] ""  PT
 SG_ contactorControlPos2_SC05 m19 : 31|4@0+ (1,0) [0|7] ""  PT
 SG_ contactorControlNeg2_SC05 m19 : 27|4@0+ (1,0) [0|7] ""  PT
 SG_ contactorControlPre2_SC05 m19 : 15|4@0+ (1,0) [0|7] ""  PT
 SG_ contactorControlPos3_SC05 m19 : 39|4@0+ (1,0) [0|7] ""  PT
 SG_ contactorControlNeg3_SC05 m19 : 35|4@0+ (1,0) [0|7] ""  PT

BO_ 1668 SC05_DebugFastMpex: 8 SC05
 SG_ selfTestFaultCntrCtrl_SC05 m11 : 23|8@0+ (1,0) [0|0] ""  PT
 SG_ cmbASICFault_SC05 m11 : 15|8@0+ (1,0) [0|0] ""  PT
 SG_ DIGIO_PYRO_LSD_EN_SC05 m2 : 12|1@0+ (1,0) [0|0] ""  PT
 SG_ mainUcExtIsoResistance_SC05 m10 : 55|16@0+ (1,0) [0|0] "KOhm"  PT
 SG_ BMS_C38_AR2MsgFault_SC05 m10 : 47|2@0+ (1,0) [0|0] ""  PT
 SG_ stateCoolant_SC05 m10 : 45|1@0+ (1,0) [0|0] ""  PT
 SG_ stateThermalEvent_SC05 m10 : 44|1@0+ (1,0) [0|0] ""  PT
 SG_ stateCANTx_SC05 m10 : 43|1@0+ (1,0) [0|0] ""  PT
 SG_ CANTxFaultTriggerFailed_SC05 m10 : 42|1@0+ (1,0) [0|0] ""  PT
 SG_ CANTxBMS1ST3MsgFault_SC05 m10 : 10|1@0+ (1,0) [0|0] ""  PT
 SG_ CANTxBMSDispReqMsgFault_SC05 m10 : 9|1@0+ (1,0) [0|0] ""  PT
 SG_ CANTxHVBatMsgFault_SC05 m10 : 8|1@0+ (1,0) [0|0] ""  PT
 SG_ mainUcCntrCtrlReq_SC05 m10 : 41|2@0+ (1,0) [0|0] ""  PT
 SG_ mainUcCntrWeldState_SC05 m10 : 39|4@0+ (1,0) [0|0] ""  PT
 SG_ safetyUcCntrState_SC05 m10 : 33|2@0+ (1,0) [0|0] ""  PT
 SG_ mainUcCntrState_SC05 m10 : 35|2@0+ (1,0) [0|0] ""  PT
 SG_ safetyCANMsg4Fault_SC05 m10 : 31|4@0+ (1,0) [0|0] ""  PT
 SG_ safetyCANMsg3Fault_SC05 m10 : 27|4@0+ (1,0) [0|0] ""  PT
 SG_ safetyCANMsg2Fault_SC05 m10 : 23|4@0+ (1,0) [0|0] ""  PT
 SG_ safetyCANMsg1Fault_SC05 m10 : 19|4@0+ (1,0) [0|0] ""  PT
 SG_ cmbBalancingDesired_SC05 m10 : 15|1@0+ (1,0) [0|0] ""  PT
 SG_ DIGIO_GPIO1_ON_SC05 m2 : 10|1@0+ (1,0) [0|0] ""  PT
 SG_ DIGIO_ZDW_LSD_EN_SC05 m2 : 11|1@0+ (1,0) [0|0] ""  PT
 SG_ currentShortCircuit_SC05 m2 : 9|1@0+ (1,0) [0|0] ""  PT
 SG_ contactorCntrSelfTest_SC05 m10 : 14|4@0+ (1,0) [0|15] ""  PT
 SG_ maxBrickVoltage_SC05 m11 : 39|16@0+ (0.0001,0) [0|6.5] "V"  PT
 SG_ minBrickVoltage_SC05 m11 : 55|16@0+ (0.0001,0) [0|6.5] "V"  PT
 SG_ cmbLastUpdateTime_SC05 m0 : 55|8@0+ (2,0) [0|500] "ms"  PT
 SG_ weldCheckState_SC05 m2 : 15|3@0+ (1,0) [0|0] ""  PT
 SG_ debugFastMpex_SC05 M : 7|8@0+ (1,0) [0|0] ""  PT
 SG_ SPIRxTxTimeAllPckts_SC05 m0 : 63|8@0+ (2,0) [0|500] "ms"  PT
 SG_ sleepRqASW_SC05 m2 : 8|1@0+ (1,0) [0|0] ""  PT
 SG_ prechgCtr1OnReqASW_SC05 m1 : 27|1@0+ (1,0) [0|0] ""  PT
 SG_ negCtr1OnReqASW_SC05 m1 : 25|1@0+ (1,0) [0|0] ""  PT
 SG_ posCtr1OnReqASW_SC05 m1 : 26|1@0+ (1,0) [0|0] ""  PT
 SG_ key_SC05 m1 : 24|1@0+ (1,0) [0|0] ""  PT
 SG_ stateContactorControl_SC05 m0 : 41|1@0+ (1,0) [0|0] ""  PT
 SG_ DIGIO_MULTIPLEX_m101_S3_SC05 m0 : 40|1@0+ (1,0) [0|0] ""  PT
 SG_ analogCntrPwrPlus_SC05 m1 : 15|8@0+ (0.2,0) [0|50] "V"  PT
 SG_ weldedState_SC05 m11 : 25|2@0+ (1,0) [0|3] ""  PT
 SG_ stateVoltage_SC05 m0 : 43|1@0+ (1,0) [0|0] ""  PT
 SG_ stateTemperature_SC05 m0 : 44|1@0+ (1,0) [0|0] ""  PT
 SG_ stateSelfTest_SC05 m0 : 45|1@0+ (1,0) [0|0] ""  PT
 SG_ stateHVIL_SC05 m0 : 46|1@0+ (1,0) [0|0] ""  PT
 SG_ stateCurrent_SC05 m0 : 47|1@0+ (1,0) [0|0] ""  PT
 SG_ stateCrash2_SC05 m0 : 36|1@0+ (1,0) [0|0] ""  PT
 SG_ stateCrash1_SC05 m0 : 37|1@0+ (1,0) [0|0] ""  PT
 SG_ stateContactors_SC05 m0 : 38|1@0+ (1,0) [0|0] ""  PT
 SG_ stateCANRx_SC05 m0 : 39|1@0+ (1,0) [0|0] ""  PT
 SG_ itemState_SC05 m0 : 35|4@0+ (1,0) [0|0] ""  PT
 SG_ DIGIO_SAFETY_GPIO0_SC05 m0 : 8|1@0+ (1,0) [0|0] ""  PT
 SG_ DIGIO_SC_LED501_CONTROL_SC05 m0 : 9|1@0+ (1,0) [0|0] ""  PT
 SG_ DIGIO_LNK_ISO_TST_SW_SC05 m0 : 10|1@0+ (1,0) [0|0] ""  PT
 SG_ DIGIO_SC_LED500_CONTROL_SC05 m0 : 11|1@0+ (1,0) [0|0] ""  PT
 SG_ DIGIO_POS_CNTR1_ON_SC05 m0 : 12|1@0+ (1,0) [0|0] ""  PT
 SG_ DIGIO_NEG_CNTR3_ON_SC05 m0 : 13|1@0+ (1,0) [0|0] ""  PT
 SG_ DIGIO_PRECHG_REL2_ON_SC05 m0 : 14|1@0+ (1,0) [0|0] ""  PT
 SG_ DIGIO_NEG_ISO_TEST_SW_SC05 m0 : 15|1@0+ (1,0) [0|0] ""  PT
 SG_ DIGIO_PRECHG_REL1_ON_SC05 m0 : 16|1@0+ (1,0) [0|0] ""  PT
 SG_ DIGIO_POS_ISO_TEST_SC05 m0 : 17|1@0+ (1,0) [0|0] ""  PT
 SG_ DIGIO_HVIL_PWM_SC05 m0 : 18|1@0+ (1,0) [0|0] ""  PT
 SG_ DIGIO_CNTR_HISIDE_ON_SC_SC05 m0 : 19|1@0+ (1,0) [0|0] ""  PT
 SG_ DIGIO_CRASH_DETECT_SC05 m0 : 20|1@0+ (1,0) [0|0] ""  PT
 SG_ DIGIO_NEG_CNTR2_ON_SC05 m0 : 21|1@0+ (1,0) [0|0] ""  PT
 SG_ DIGIO_NEG_CNTR1_ON_SC05 m0 : 22|1@0+ (1,0) [0|0] ""  PT
 SG_ DIGIO_POS_CNTR3_ON_SC05 m0 : 23|1@0+ (1,0) [0|0] ""  PT
 SG_ DIGIO_POS_CNTR2_ON_SC05 m0 : 24|1@0+ (1,0) [0|0] ""  PT
 SG_ DIGIO_MULTIPLEX_m101_S2_SC05 m0 : 25|1@0+ (1,0) [0|0] ""  PT
 SG_ DIGIO_MULTIPLEX_8TO1_S1_SC05 m0 : 26|1@0+ (1,0) [0|0] ""  PT
 SG_ DIGIO_CNTR_CLOSE_OK_CHCKD_SC05 m0 : 27|1@0+ (1,0) [0|0] ""  PT
 SG_ DIGIO_MULTIPLEX_8TO1_S2_SC05 m0 : 28|1@0+ (1,0) [0|0] ""  PT
 SG_ DIGIO_CNTR_CLOSE_OK_SC05 m0 : 29|1@0+ (1,0) [0|0] ""  PT
 SG_ DIGIO_MULTIPLEX_m101_S1_SC05 m0 : 30|1@0+ (1,0) [0|0] ""  PT
 SG_ DIGIO_CNTR_HISIDE_ON_CHCKD_SC05 m0 : 31|1@0+ (1,0) [0|0] ""  PT
 SG_ posPack_SC05 m2 : 23|16@0+ (0.04,-1250) [-1250|1250] "V"  PT
 SG_ posLink_SC05 m2 : 55|16@0+ (0.04,-1250) [-1250|1371.4] "V"  PT
 SG_ negPack_SC05 m2 : 39|16@0+ (0.04,-1250) [-1250|1250] "V"  PT
 SG_ negLink_SC05 m1 : 39|16@0+ (0.04,-1250) [-1250|1371.4] "V"  PT
 SG_ hallCurrent_SC05 m1 : 23|12@0+ (0.6,-1200) [-1200|1257] "A"  PT
 SG_ analogCntrPwrPlusISense_SC05 m1 : 63|8@0+ (0.05,0) [0|12.5] "A"  PT
 SG_ analogCntrPwrPlusSwitched_SC05 m1 : 55|8@0+ (0.2,0) [0|50] "V"  PT
 SG_ BIT_ANALOG_REF_FAIL_SC05 m3 : 8|1@0+ (1,0) [0|0] ""  PT
 SG_ BIT_ANALOG_ADCDRIVER_FAIL_SC05 m3 : 9|1@0+ (1,0) [0|0] ""  PT
 SG_ BIT_ANALOG_MUX910_HW_SC05 m3 : 10|1@0+ (1,0) [0|0] ""  PT
 SG_ BIT_ANALOG_MUX960_HW_SC05 m3 : 11|1@0+ (1,0) [0|0] ""  PT
 SG_ BIT_ANALOG_MUX301_HW_SC05 m3 : 12|1@0+ (1,0) [0|0] ""  PT
 SG_ BIT_ANALOG_MUX440_HW_SC05 m3 : 13|1@0+ (1,0) [0|0] ""  PT
 SG_ BIT_ANALOG_5VA_FAIL_SC05 m3 : 14|1@0+ (1,0) [0|0] ""  PT
 SG_ BIT_ANALOG_HV_SIGN_SC05 m3 : 15|1@0+ (1,0) [0|0] ""  PT
 SG_ BIT_CAN_ISENSE01_MIA_SC05 m3 : 24|1@0+ (1,0) [0|0] ""  PT
 SG_ BIT_CAN_ISENSE02_MIA_SC05 m3 : 25|1@0+ (1,0) [0|0] ""  PT
 SG_ BIT_CAN_ISENSE03_MIA_SC05 m3 : 26|1@0+ (1,0) [0|0] ""  PT
 SG_ BIT_CAN_ISENSE04_MIA_SC05 m3 : 27|1@0+ (1,0) [0|0] ""  PT
 SG_ BIT_CAN_ISENSE05_MIA_SC05 m3 : 28|1@0+ (1,0) [0|0] ""  PT
 SG_ BIT_CAN_PT_MIA_SC05 m3 : 29|1@0+ (1,0) [0|0] ""  PT
 SG_ BIT_CAN_PT_CRC_SC05 m3 : 30|1@0+ (1,0) [0|0] ""  PT
 SG_ BIT_CAN_PT_ALIVE_SC05 m3 : 31|1@0+ (1,0) [0|0] ""  PT
 SG_ BIT_CAN_SAFETYLIN_MIA_SC05 m3 : 32|1@0+ (1,0) [0|0] ""  PT
 SG_ BIT_CAN_SAFETYLIN_SHUTDOWN_SC05 m3 : 33|1@0+ (1,0) [0|0] ""  PT
 SG_ BIT_CMB_GPIO_SHORT_SC05 m3 : 40|1@0+ (1,0) [0|0] ""  PT
 SG_ BIT_CMB_C2S_LEAK_SC05 m3 : 41|1@0+ (1,0) [0|0] ""  PT
 SG_ BIT_CMB_SENSE_LINE_SC05 m3 : 42|1@0+ (1,0) [0|0] ""  PT
 SG_ BIT_CMB_SUMOFCELL_CHECK_SC05 m3 : 43|1@0+ (1,0) [0|0] ""  PT
 SG_ BIT_CMB_DRIVER_TIMING_SC05 m3 : 44|1@0+ (1,0) [0|0] ""  PT
 SG_ BIT_CMB_CLEAR_SC05 m3 : 45|1@0+ (1,0) [0|0] ""  PT
 SG_ BIT_CMB_SELFTEST_SC05 m3 : 46|1@0+ (1,0) [0|0] ""  PT
 SG_ BIT_CMB_GPIO_OPEN_SC05 m3 : 47|1@0+ (1,0) [0|0] ""  PT
 SG_ BIT_CMB_CELLV_RANGE_ERR_SC05 m3 : 48|1@0+ (1,0) [0|0] ""  PT
 SG_ BIT_CMB_ADOL_CHECK_SC05 m3 : 49|1@0+ (1,0) [0|0] ""  PT
 SG_ BIT_CMB_BALANCING_STUCK_SC05 m3 : 50|1@0+ (1,0) [0|0] ""  PT
 SG_ BIT_CMB_SUPPLY_SC05 m3 : 51|1@0+ (1,0) [0|0] ""  PT
 SG_ BIT_CMB_DEFECT_SC05 m3 : 52|1@0+ (1,0) [0|0] ""  PT
 SG_ BIT_CMB_PEC_ERROR_SC05 m3 : 53|1@0+ (1,0) [0|0] ""  PT
 SG_ BIT_CMB_GPIO_ERROR_SC05 m3 : 54|1@0+ (1,0) [0|0] ""  PT
 SG_ BIT_CMB_DIGTLREDNCY_LF_SC05 m3 : 55|1@0+ (1,0) [0|0] ""  PT
 SG_ BIT_CCTRL_SELFTEST_SC05 m4 : 8|1@0+ (1,0) [0|0] ""  PT
 SG_ BIT_CCTRL_DRIVER_FAULT_SC05 m4 : 9|1@0+ (1,0) [0|0] ""  PT
 SG_ BIT_CCTRL_HISIDE_STCLSD_SC05 m4 : 10|1@0+ (1,0) [0|0] ""  PT
 SG_ BIT_CCTRL_LOSIDE_STCLSD_SC05 m4 : 11|1@0+ (1,0) [0|0] ""  PT
 SG_ BIT_CCTRL_HISIDE_STUCK_OPEN_SC05 m4 : 12|1@0+ (1,0) [0|0] ""  PT
 SG_ BIT_CCTRL_HVOLTAGE_COND_SC05 m4 : 13|1@0+ (1,0) [0|0] ""  PT
 SG_ BIT_CCTRL_POS1_OPENCIRC_SC05 m4 : 14|1@0+ (1,0) [0|0] ""  PT
 SG_ BIT_CCTRL_NEG1_OPENCIRC_SC05 m4 : 15|1@0+ (1,0) [0|0] ""  PT
 SG_ BIT_CCTRL_PRECHG1_OPENCIRC_SC05 m4 : 16|1@0+ (1,0) [0|0] ""  PT
 SG_ BIT_CCTRL_POS2_OPENCIRC_SC05 m4 : 17|1@0+ (1,0) [0|0] ""  PT
 SG_ BIT_CCTRL_NEG2_OPENCIRC_SC05 m4 : 18|1@0+ (1,0) [0|0] ""  PT
 SG_ BIT_CCTRL_LOSDE_STOPEN_SC05 m4 : 19|1@0+ (1,0) [0|0] ""  PT
 SG_ BIT_CCTRL_POS3_OPENCIRC_SC05 m4 : 20|1@0+ (1,0) [0|0] ""  PT
 SG_ BIT_CCTRL_PRECHG2_OPENCIRC_SC05 m4 : 21|1@0+ (1,0) [0|0] ""  PT
 SG_ BIT_CCTRL_ITEM_OFF_OPEN_SC05 m4 : 22|1@0+ (1,0) [0|0] ""  PT
 SG_ BIT_CCTRL_UNEXPECTED_OPEN_SC05 m4 : 23|1@0+ (1,0) [0|0] ""  PT
 SG_ BIT_CNTR_ISOLATION_SC05 m4 : 24|1@0+ (1,0) [0|0] ""  PT
 SG_ BIT_CNTR_ISO_AND_POT_WELD_SC05 m4 : 25|1@0+ (1,0) [0|0] ""  PT
 SG_ BIT_CNTR_POS1_WELDED_SC05 m4 : 26|1@0+ (1,0) [0|0] ""  PT
 SG_ BIT_CNTR_NEG1_WELDED_SC05 m4 : 27|1@0+ (1,0) [0|0] ""  PT
 SG_ BIT_CNTR_POS2_WELDED_SC05 m4 : 28|1@0+ (1,0) [0|0] ""  PT
 SG_ BIT_CNTR_NEG2_WELDED_SC05 m4 : 29|1@0+ (1,0) [0|0] ""  PT
 SG_ BIT_CNTR_POS3_WELDED_SC05 m4 : 30|1@0+ (1,0) [0|0] ""  PT
 SG_ BIT_CNTR_NEG3_WELDED_SC05 m4 : 31|1@0+ (1,0) [0|0] ""  PT
 SG_ BIT_CNTR_P_ANDOR_N_WELD_SC05 m4 : 32|1@0+ (1,0) [0|0] ""  PT
 SG_ BIT_CNTR_HIGH_CY_SC05 m4 : 33|1@0+ (1,0) [0|0] ""  PT
 SG_ BIT_CNTR_WELDCHECK_TIMEOUT_SC05 m4 : 34|1@0+ (1,0) [0|0] ""  PT
 SG_ BIT_CURRENT_PLAUSIBILITY_SC05 m4 : 40|1@0+ (1,0) [0|0] ""  PT
 SG_ BIT_CURRENT_OVERCHARGE_SC05 m4 : 41|1@0+ (1,0) [0|0] ""  PT
 SG_ BIT_CURRENT_OVERDISCHARGE_SC05 m4 : 42|1@0+ (1,0) [0|0] ""  PT
 SG_ BIT_CURRENT_ISENSE1_INVALID_SC05 m4 : 43|1@0+ (1,0) [0|0] ""  PT
 SG_ BIT_CURRENT_ISENSE2_INVALID_SC05 m4 : 44|1@0+ (1,0) [0|0] ""  PT
 SG_ BIT_CURRENT_ISENSE3_INVALID_SC05 m4 : 45|1@0+ (1,0) [0|0] ""  PT
 SG_ BIT_CURRENT_ISENSE4_INVALID_SC05 m4 : 46|1@0+ (1,0) [0|0] ""  PT
 SG_ BIT_CURRENT_ISENSE5_INVALID_SC05 m4 : 47|1@0+ (1,0) [0|0] ""  PT
 SG_ BIT_CURRENT_HALL_INVALID_SC05 m4 : 48|1@0+ (1,0) [0|0] ""  PT
 SG_ BIT_CURRENT_OFFSET_FAULT_SC05 m4 : 49|1@0+ (1,0) [0|0] ""  PT
 SG_ BIT_FLUXGATE1_CURRENT_FAULT_SC05 m5 : 8|1@0+ (1,0) [0|0] ""  PT
 SG_ BIT_FLUXGATE_12V_LOW_SC05 m5 : 18|1@0+ (1,0) [0|0] ""  PT
 SG_ BIT_HALL_INVALID_SC05 m5 : 24|1@0+ (1,0) [0|0] ""  PT
 SG_ BIT_HALL_PWR_FAIL_LO_SC05 m5 : 25|1@0+ (1,0) [0|0] ""  PT
 SG_ BIT_HALL_SENSELO_SC05 m5 : 26|1@0+ (1,0) [0|0] ""  PT
 SG_ BIT_HALL_SENSEHI_SC05 m5 : 27|1@0+ (1,0) [0|0] ""  PT
 SG_ BIT_HVIL_HW_FAULT_SC05 m5 : 40|1@0+ (1,0) [0|0] ""  PT
 SG_ BIT_HVIL_OPEN_CIRCUIT_SC05 m5 : 41|1@0+ (1,0) [0|0] ""  PT
 SG_ BIT_HVIL_SHORT_SUPPLY_SC05 m5 : 42|1@0+ (1,0) [0|0] ""  PT
 SG_ BIT_HVIL_SHORT_CHASSIS_SC05 m5 : 43|1@0+ (1,0) [0|0] ""  PT
 SG_ BIT_HVIL_RESISTANCE_HIGH_SC05 m5 : 44|1@0+ (1,0) [0|0] ""  PT
 SG_ BIT_HVIL_SHORT_CIRCUIT_SC05 m5 : 45|1@0+ (1,0) [0|0] ""  PT
 SG_ BIT_ISASHUNT1_CURRENT_FAULT_SC05 m7 : 24|1@0+ (1,0) [0|0] ""  PT
 SG_ BIT_ISASHUNT2_CURRENT_FAULT_SC05 m7 : 25|1@0+ (1,0) [0|0] ""  PT
 SG_ BIT_ISASHUNT3_CURRENT_FAULT_SC05 m7 : 26|1@0+ (1,0) [0|0] ""  PT
 SG_ BIT_ISASHUNT4_CURRENT_FAULT_SC05 m7 : 27|1@0+ (1,0) [0|0] ""  PT
 SG_ BIT_ISASHUNT5_CURRENT_FAULT_SC05 m7 : 28|1@0+ (1,0) [0|0] ""  PT
 SG_ BIT_ISASHUNT1_CHARGE_FAULT_SC05 m7 : 29|1@0+ (1,0) [0|0] ""  PT
 SG_ BIT_ISASHUNT2_CHARGE_FAULT_SC05 m7 : 30|1@0+ (1,0) [0|0] ""  PT
 SG_ BIT_ISASHUNT3_CHARGE_FAULT_SC05 m7 : 31|1@0+ (1,0) [0|0] ""  PT
 SG_ BIT_ISASHUNT4_CHARGE_FAULT_SC05 m7 : 32|1@0+ (1,0) [0|0] ""  PT
 SG_ BIT_ISASHUNT5_CHARGE_FAULT_SC05 m7 : 33|1@0+ (1,0) [0|0] ""  PT
 SG_ BIT_ISASHUNT_SUPPLY_LOW_SC05 m7 : 34|1@0+ (1,0) [0|0] ""  PT
 SG_ BIT_LINK_POS_HW_FAIL_SC05 m7 : 40|1@0+ (1,0) [0|0] ""  PT
 SG_ BIT_LINK_NEG_HW_FAIL_SC05 m7 : 41|1@0+ (1,0) [0|0] ""  PT
 SG_ BIT_PUMP_LIN_FAILURE_SC05 m8 : 8|1@0+ (1,0) [0|0] ""  PT
 SG_ BIT_PUMP_OVERTEMPERATURE_SC05 m8 : 9|1@0+ (1,0) [0|0] ""  PT
 SG_ BIT_PUMP_SPEED_HIGH_SC05 m8 : 10|1@0+ (1,0) [0|0] ""  PT
 SG_ BIT_PUMP_SPEED_LOW_SC05 m8 : 11|1@0+ (1,0) [0|0] ""  PT
 SG_ BIT_PUMP_DRY_RUN_SC05 m8 : 12|1@0+ (1,0) [0|0] ""  PT
 SG_ BIT_SBC_VCORE_OOR_SC05 m6 : 8|1@0+ (1,0) [0|0] ""  PT
 SG_ BIT_SBC_SELFTEST_SC05 m6 : 9|1@0+ (1,0) [0|0] ""  PT
 SG_ BIT_SBC_INIT_SC05 m6 : 10|1@0+ (1,0) [0|0] ""  PT
 SG_ BIT_SBC_WATCHDOG_SC05 m6 : 11|1@0+ (1,0) [0|0] ""  PT
 SG_ BIT_SBC_FECBITFLIP_SC05 m6 : 12|1@0+ (1,0) [0|0] ""  PT
 SG_ BIT_SBC_VREUV_SC05 m6 : 13|1@0+ (1,0) [0|0] ""  PT
 SG_ BIT_SBC_FAILSAFE_SC05 m6 : 14|1@0+ (1,0) [0|0] ""  PT
 SG_ BIT_SBC_VAUX_OOR_SC05 m6 : 15|1@0+ (1,0) [0|0] ""  PT
 SG_ BIT_SBC_VCCA_OOR_SC05 m6 : 16|1@0+ (1,0) [0|0] ""  PT
 SG_ BIT_SBC_FCRBM_OOR_SC05 m6 : 17|1@0+ (1,0) [0|0] ""  PT
 SG_ BIT_SBC_FLT_ERR_CNTR_SC05 m6 : 18|1@0+ (1,0) [0|0] ""  PT
 SG_ BIT_SBC_FS0B_FAIL_SC05 m6 : 19|1@0+ (1,0) [0|0] ""  PT
 SG_ BIT_SBC_SPI_ERRORS_SC05 m6 : 20|1@0+ (1,0) [0|0] ""  PT
 SG_ BIT_SBC_SPI_TX_FAIL_SC05 m6 : 21|1@0+ (1,0) [0|0] ""  PT
 SG_ BIT_SBC_NERROR_ACTIVE_SC05 m6 : 22|1@0+ (1,0) [0|0] ""  PT
 SG_ BIT_SELFTEST_RAM_SC05 m6 : 24|1@0+ (1,0) [0|0] ""  PT
 SG_ BIT_SELFTEST_FLASH_SC05 m6 : 25|1@0+ (1,0) [0|0] ""  PT
 SG_ BIT_SELFTEST_CLOCK_SC05 m6 : 26|1@0+ (1,0) [0|0] ""  PT
 SG_ BIT_SELFTEST_WATCHDOG_SC05 m6 : 27|1@0+ (1,0) [0|0] ""  PT
 SG_ BIT_SELFTEST_STACK_SC05 m6 : 28|1@0+ (1,0) [0|0] ""  PT
 SG_ BIT_SELFTEST_L2L3_SC05 m6 : 29|1@0+ (1,0) [0|0] ""  PT
 SG_ BIT_SELFTEST_EFUSE_SC05 m6 : 30|1@0+ (1,0) [0|0] ""  PT
 SG_ BIT_SELFTEST_EXCEPTION_SC05 m6 : 31|1@0+ (1,0) [0|0] ""  PT
 SG_ BIT_SELFTEST_5VD_FAIL_SC05 m6 : 32|1@0+ (1,0) [0|0] ""  PT
 SG_ BIT_SELFTEST_VIM_SC05 m6 : 33|1@0+ (1,0) [0|0] ""  PT
 SG_ BIT_SELFTEST_TASKTIME_SC05 m6 : 34|1@0+ (1,0) [0|0] ""  PT
 SG_ BIT_SELFTEST_RTI_SC05 m6 : 35|1@0+ (1,0) [0|0] ""  PT
 SG_ BIT_SELFTEST_ESM_SC05 m6 : 36|1@0+ (1,0) [0|0] ""  PT
 SG_ BIT_SELFTEST_IOM_SC05 m6 : 37|1@0+ (1,0) [0|0] ""  PT
 SG_ BIT_SELFTEST_SBC_SC05 m6 : 38|1@0+ (1,0) [0|0] ""  PT
 SG_ BIT_SELFTEST_STARTUP_SC05 m6 : 39|1@0+ (1,0) [0|0] ""  PT
 SG_ BIT_TEMP_MODULEOVERTEMP_SC05 m6 : 40|1@0+ (1,0) [0|0] ""  PT
 SG_ BIT_TEMP_MODULETEMP_INVALID_SC05 m6 : 41|1@0+ (1,0) [0|0] ""  PT
 SG_ BIT_TEMP_NTC_OPENWIRE_SC05 m6 : 42|1@0+ (1,0) [0|0] ""  PT
 SG_ BIT_TEMP_NTC_SHORT_SC05 m6 : 43|1@0+ (1,0) [0|0] ""  PT
 SG_ BIT_TEMP_PLAUSIBILITY_SC05 m6 : 44|1@0+ (1,0) [0|0] ""  PT
 SG_ BIT_VOLTAGE_BRICKV_INVALID_SC05 m7 : 8|1@0+ (1,0) [0|0] ""  PT
 SG_ BIT_VOLTAGE_BRICKUV_SC05 m7 : 9|1@0+ (1,0) [0|0] ""  PT
 SG_ BIT_VOLTAGE_BRICKOV_SC05 m7 : 10|1@0+ (1,0) [0|0] ""  PT
 SG_ BIT_VOLTAGE_BRICKDEEPDSCHG_SC05 m7 : 11|1@0+ (1,0) [0|0] ""  PT
 SG_ BIT_VOLTAGE_PACKV_INVALID_SC05 m7 : 12|1@0+ (1,0) [0|0] ""  PT
 SG_ BIT_VOLTAGE_PLAUSIBILITY_SC05 m7 : 13|1@0+ (1,0) [0|0] ""  PT
 SG_ BIT_VOLTAGE_CMB_PLAUSI_SC05 m7 : 14|1@0+ (1,0) [0|0] ""  PT
 SG_ BIT_VOLTAGE_SENSE_OPENWIRE_SC05 m7 : 15|1@0+ (1,0) [0|0] ""  PT
 SG_ BIT_VOLTAGE_BRICKV_FROZEN_SC05 m7 : 16|1@0+ (1,0) [0|0] ""  PT
 SG_ BIT_PUMP_BLOCK_SC05 m8 : 13|1@0+ (1,0) [0|0] ""  PT
 SG_ BIT_PUMP_SUPPLY_SC05 m8 : 14|1@0+ (1,0) [0|0] ""  PT
 SG_ BIT_PUMP_OVERCURRENT_SC05 m8 : 15|1@0+ (1,0) [0|0] ""  PT
 SG_ BIT_PUMP_ELECTRIC_SC05 m8 : 16|1@0+ (1,0) [0|0] ""  PT
 SG_ BIT_PUMP_RS_SC05 m8 : 17|1@0+ (1,0) [0|0] ""  PT
 SG_ BIT_HALL_PWR_FAIL_HI_SC05 m5 : 28|1@0+ (1,0) [0|0] ""  PT
 SG_ BIT_VOLTAGE_OUT_OF_RANGE_SC05 m7 : 17|1@0+ (1,0) [0|0] ""  PT
 SG_ BIT_ISO_OFF_TIME_SHORT_SC05 m8 : 24|1@0+ (1,0) [0|0] ""  PT
 SG_ BIT_ISO_ON_TIME_SHORT_SC05 m8 : 25|1@0+ (1,0) [0|0] ""  PT
 SG_ BIT_ISO_INTERNAL_INACTIVE_SC05 m8 : 26|1@0+ (1,0) [0|0] ""  PT
 SG_ BIT_ISO_SW_STATE_INVALID_SC05 m8 : 27|1@0+ (1,0) [0|0] ""  PT
 SG_ BIT_ISO_PACKV_SNA_SWOFF_SC05 m8 : 28|1@0+ (1,0) [0|0] ""  PT
 SG_ BIT_ISO_PACKV_SNA_SWON_SC05 m8 : 29|1@0+ (1,0) [0|0] ""  PT
 SG_ BIT_ISO_EXTERNAL_INACTIVE_SC05 m8 : 30|1@0+ (1,0) [0|0] ""  PT
 SG_ BIT_CANTX_CNTR_STAT_FAULT_SC05 m8 : 40|1@0+ (1,0) [0|0] ""  PT
 SG_ BIT_CANTX_CNTR_WELD_FAULT_SC05 m8 : 41|1@0+ (1,0) [0|0] ""  PT
 SG_ BIT_CANTX_THERMAL_FAULT_SC05 m8 : 42|1@0+ (1,0) [0|0] ""  PT
 SG_ BIT_CANTX_ISOLATION_FAULT_SC05 m8 : 43|1@0+ (1,0) [0|0] ""  PT
 SG_ BIT_CANTX_HVIL_FAULT_SC05 m8 : 44|1@0+ (1,0) [0|0] ""  PT
 SG_ BIT_VOLTAGE_STATELATCHED_SC05 m7 : 18|1@0+ (1,0) [0|0] ""  PT
 SG_ BIT_CANTX_ISOLATION_PREFLT_SC05 m8 : 45|1@0+ (1,0) [0|0] ""  PT
 SG_ BIT_CANTX_FLTRIGGER_FAILED_SC05 m8 : 46|1@0+ (1,0) [0|0] ""  PT
 SG_ BIT_ISO_TEST_SWITCH_FAULT_SC05 m8 : 31|1@0+ (1,0) [0|0] ""  PT
 SG_ BIT_THERMAL_ADC_FAULT_SC05 m9 : 8|1@0+ (1,0) [0|0] ""  PT
 SG_ BIT_THERMAL_PRESSURE_VHI_SC05 m9 : 9|1@0+ (1,0) [0|0] ""  PT
 SG_ BIT_THERMAL_PRESSURE_VLO_SC05 m9 : 10|1@0+ (1,0) [0|0] ""  PT
 SG_ BIT_THERMAL_PRIMARY_EVT_SC05 m9 : 11|1@0+ (1,0) [0|0] ""  PT
 SG_ BIT_THERMAL_SECONRY_EVT_SC05 m9 : 12|1@0+ (1,0) [0|0] ""  PT
 SG_ BIT_THERMAL_PRESSURE_INV_SC05 m9 : 13|1@0+ (1,0) [0|0] ""  PT
 SG_ BIT_THERMAL_EVTLATCHED_SC05 m9 : 14|1@0+ (1,0) [0|0] ""  PT
 SG_ BIT_COOLANT_CANMIA_SC05 m9 : 24|1@0+ (1,0) [0|0] ""  PT
 SG_ BIT_COOLANT_SENSRFAIL_SC05 m9 : 25|1@0+ (1,0) [0|0] ""  PT
 SG_ BIT_COOLANT_WATERDETCD_SC05 m9 : 26|1@0+ (1,0) [0|0] ""  PT
 SG_ BIT_COOLANT_LATCHED_SC05 m9 : 27|1@0+ (1,0) [0|0] ""  PT
 SG_ BIT_ANALOG_PULLUP_DSBLD_SC05 m3 : 17|1@0+ (1,0) [0|0] ""  PT
 SG_ BIT_ANALOG_PULLUP_DSBLRQ_SC05 m3 : 16|1@0+ (1,0) [0|0] ""  PT
 SG_ BIT_SBC_REG_ERROR_SC05 m6 : 23|1@0+ (1,0) [0|0] ""  PT
 SG_ BIT_CURRENT_LATCHED_SC05 m4 : 50|1@0+ (1,0) [0|0] ""  PT
 SG_ BIT_TEMP_LATCHED_SC05 m6 : 45|1@0+ (1,0) [0|0] ""  PT
 SG_ BIT_ISO_PLAUSI_SWOFF_SC05 m8 : 32|1@0+ (1,0) [0|0] ""  PT
 SG_ BIT_ISO_PLAUSI_SWON_SC05 m8 : 33|1@0+ (1,0) [0|0] ""  PT
 SG_ BIT_ISO_RELAXED_INACTIVE_SC05 m8 : 34|1@0+ (1,0) [0|0] ""  PT
 SG_ BIT_THERMAL_PRESSURE_MIA_SC05 m9 : 15|1@0+ (1,0) [0|0] ""  PT
 SG_ BIT_LINK_PACK_MISMATCH_SC05 m7 : 42|1@0+ (1,0) [0|0] ""  PT
 SG_ BIT_CAN_PT_EMERGENCY_SC05 m3 : 34|1@0+ (1,0) [0|0] ""  PT
 SG_ BIT_THERMAL_PRES_SUPPLY_OOR_SC05 m9 : 16|1@0+ (1,0) [0|0] ""  PT
 SG_ BIT_CAN_SM_DISABLE_SC05 m3 : 35|1@0+ (1,0) [0|0] ""  PT
 SG_ BIT_THERMAL_PRESSURE_FLT_SC05 m9 : 17|1@0+ (1,0) [0|0] ""  PT
 SG_ BIT_CURRENT_SENSOR_FAULT_SC05 m9 : 40|1@0+ (1,0) [0|0] ""  PT
 SG_ BIT_CURRENT_SENSOR_CHARGE_FAULT_SC05 m9 : 45|1@0+ (1,0) [0|0] ""  PT
 SG_ BIT_CURRENT_SENSOR_SUP_LOW_SC05 m9 : 50|1@0+ (1,0) [0|0] ""  PT
 SG_ BIT_THERMAL_H2SENSE_FAULT_SC05 m9 : 18|1@0+ (1,0) [0|0] ""  PT
 SG_ BIT_VOLTAGE_BRICKCOUNT_INVALID_SC05 m7 : 19|1@0+ (1,0) [0|0] ""  PT

BO_ 1924 BMS05_DebugOnboard: 7 BMS05
 SG_ cmbCoolantTemp08_BMS05 m8 : 55|8@0+ (1,-40) [-40|200] "C"  PT
 SG_ cmbCoolantTemp07_BMS05 m7 : 55|8@0+ (1,-40) [-40|200] "C"  PT
 SG_ cmbCoolantTemp06_BMS05 m6 : 55|8@0+ (1,-40) [-40|200] "C"  PT
 SG_ cmbCoolantTemp05_BMS05 m5 : 55|8@0+ (1,-40) [-40|200] "C"  PT
 SG_ cmbCoolantTemp04_BMS05 m4 : 55|8@0+ (1,-40) [-40|200] "C"  PT
 SG_ cmbCoolantTemp03_BMS05 m3 : 55|8@0+ (1,-40) [-40|200] "C"  PT
 SG_ cmbCoolantTemp02_BMS05 m2 : 55|8@0+ (1,-40) [-40|200] "C"  PT
 SG_ cmbCoolantTemp01_BMS05 m1 : 55|8@0+ (1,-40) [-40|200] "C"  PT
 SG_ cmbOnboardPressure32_BMS05 m32 : 39|16@0+ (1,0) [0|600] "kPa"  PT
 SG_ cmbOnboardPressure31_BMS05 m31 : 39|16@0+ (1,0) [0|600] "kPa"  PT
 SG_ cmbOnboardPressure30_BMS05 m30 : 39|16@0+ (1,0) [0|600] "kPa"  PT
 SG_ cmbOnboardPressure29_BMS05 m29 : 39|16@0+ (1,0) [0|600] "kPa"  PT
 SG_ cmbOnboardPressure28_BMS05 m28 : 39|16@0+ (1,0) [0|600] "kPa"  PT
 SG_ cmbOnboardPressure27_BMS05 m27 : 39|16@0+ (1,0) [0|600] "kPa"  PT
 SG_ cmbOnboardPressure26_BMS05 m26 : 39|16@0+ (1,0) [0|600] "kPa"  PT
 SG_ cmbOnboardPressure25_BMS05 m25 : 39|16@0+ (1,0) [0|600] "kPa"  PT
 SG_ cmbOnboardPressure24_BMS05 m24 : 39|16@0+ (1,0) [0|600] "kPa"  PT
 SG_ cmbOnboardPressure23_BMS05 m23 : 39|16@0+ (1,0) [0|600] "kPa"  PT
 SG_ cmbOnboardPressure22_BMS05 m22 : 39|16@0+ (1,0) [0|600] "kPa"  PT
 SG_ cmbOnboardPressure21_BMS05 m21 : 39|16@0+ (1,0) [0|600] "kPa"  PT
 SG_ cmbOnboardPressure20_BMS05 m20 : 39|16@0+ (1,0) [0|600] "kPa"  PT
 SG_ cmbOnboardPressure19_BMS05 m19 : 39|16@0+ (1,0) [0|600] "kPa"  PT
 SG_ cmbOnboardPressure18_BMS05 m18 : 39|16@0+ (1,0) [0|600] "kPa"  PT
 SG_ cmbOnboardPressure17_BMS05 m17 : 39|16@0+ (1,0) [0|600] "kPa"  PT
 SG_ cmbOnboardPressure16_BMS05 m16 : 39|16@0+ (1,0) [0|600] "kPa"  PT
 SG_ cmbOnboardPressure15_BMS05 m15 : 39|16@0+ (1,0) [0|600] "kPa"  PT
 SG_ cmbOnboardPressure14_BMS05 m14 : 39|16@0+ (1,0) [0|600] "kPa"  PT
 SG_ cmbOnboardPressure13_BMS05 m13 : 39|16@0+ (1,0) [0|600] "kPa"  PT
 SG_ cmbOnboardPressure12_BMS05 m12 : 39|16@0+ (1,0) [0|600] "kPa"  PT
 SG_ cmbOnboardPressure11_BMS05 m11 : 39|16@0+ (1,0) [0|600] "kPa"  PT
 SG_ cmbOnboardPressure10_BMS05 m10 : 39|16@0+ (1,0) [0|600] "kPa"  PT
 SG_ cmbOnboardPressure09_BMS05 m9 : 39|16@0+ (1,0) [0|600] "kPa"  PT
 SG_ cmbOnboardPressure08_BMS05 m8 : 39|16@0+ (1,0) [0|600] "kPa"  PT
 SG_ cmbOnboardPressure07_BMS05 m7 : 39|16@0+ (1,0) [0|600] "kPa"  PT
 SG_ cmbOnboardPressure06_BMS05 m6 : 39|16@0+ (1,0) [0|600] "kPa"  PT
 SG_ cmbOnboardPressure05_BMS05 m5 : 39|16@0+ (1,0) [0|600] "kPa"  PT
 SG_ cmbOnboardPressure04_BMS05 m4 : 39|16@0+ (1,0) [0|600] "kPa"  PT
 SG_ cmbOnboardPressure03_BMS05 m3 : 39|16@0+ (1,0) [0|600] "kPa"  PT
 SG_ cmbOnboardPressure02_BMS05 m2 : 39|16@0+ (1,0) [0|600] "kPa"  PT
 SG_ cmbOnboardPressure01_BMS05 m1 : 39|16@0+ (1,0) [0|600] "kPa"  PT
 SG_ onboardMultiplexor_BMS05 M : 7|8@0+ (1,0) [0|0] ""  PT
 SG_ minCmbOnboardTemperature_BMS05 m0 : 31|8@0+ (1,-40) [-40|200] "C"  PT
 SG_ minCmbOnboardHumidity_BMS05 m0 : 47|8@0+ (0.5,0) [0|120] "PCT"  PT
 SG_ maxCmbOnboardTemperature_BMS05 m0 : 39|8@0+ (1,-40) [-40|200] "C"  PT
 SG_ maxCmbOnboardHumidity_BMS05 m0 : 55|8@0+ (0.5,0) [0|120] "PCT"  PT
 SG_ bmsOnboardTemperature_BMS05 m0 : 15|8@0+ (1,-40) [-40|200] "C"  PT
 SG_ bmsOnboardHumidity_BMS05 m0 : 23|8@0+ (0.5,0) [0|120] "PCT"  PT
 SG_ cmbOnboardTemperature01_BMS05 m1 : 15|8@0+ (1,-40) [-40|200] "C"  PT
 SG_ cmbOnboardHumidity01_BMS05 m1 : 23|8@0+ (0.5,0) [0|120] "PCT"  PT
 SG_ moduleHeaterCurrent01_BMS05 m1 : 31|8@0+ (0.05,0) [0|10] "A"  PT
 SG_ cmbOnboardTemperature02_BMS05 m2 : 15|8@0+ (1,-40) [-40|200] "C"  PT
 SG_ cmbOnboardHumidity02_BMS05 m2 : 23|8@0+ (0.5,0) [0|120] "PCT"  PT
 SG_ moduleHeaterCurrent02_BMS05 m2 : 31|8@0+ (0.05,0) [0|10] "A"  PT
 SG_ cmbOnboardTemperature03_BMS05 m3 : 15|8@0+ (1,-40) [-40|200] "C"  PT
 SG_ cmbOnboardHumidity03_BMS05 m3 : 23|8@0+ (0.5,0) [0|120] "PCT"  PT
 SG_ moduleHeaterCurrent03_BMS05 m3 : 31|8@0+ (0.05,0) [0|10] "A"  PT
 SG_ cmbOnboardTemperature04_BMS05 m4 : 15|8@0+ (1,-40) [-40|200] "C"  PT
 SG_ cmbOnboardHumidity04_BMS05 m4 : 23|8@0+ (0.5,0) [0|120] "PCT"  PT
 SG_ moduleHeaterCurrent04_BMS05 m4 : 31|8@0+ (0.05,0) [0|10] "A"  PT
 SG_ cmbOnboardTemperature05_BMS05 m5 : 15|8@0+ (1,-40) [-40|200] "C"  PT
 SG_ cmbOnboardHumidity05_BMS05 m5 : 23|8@0+ (0.5,0) [0|120] "PCT"  PT
 SG_ moduleHeaterCurrent05_BMS05 m5 : 31|8@0+ (0.05,0) [0|10] "A"  PT
 SG_ cmbOnboardTemperature06_BMS05 m6 : 15|8@0+ (1,-40) [-40|200] "C"  PT
 SG_ cmbOnboardHumidity06_BMS05 m6 : 23|8@0+ (0.5,0) [0|120] "PCT"  PT
 SG_ moduleHeaterCurrent06_BMS05 m6 : 31|8@0+ (0.05,0) [0|10] "A"  PT
 SG_ cmbOnboardTemperature07_BMS05 m7 : 15|8@0+ (1,-40) [-40|200] "C"  PT
 SG_ cmbOnboardHumidity07_BMS05 m7 : 23|8@0+ (0.5,0) [0|120] "PCT"  PT
 SG_ moduleHeaterCurrent07_BMS05 m7 : 31|8@0+ (0.05,0) [0|10] "A"  PT
 SG_ cmbOnboardTemperature08_BMS05 m8 : 15|8@0+ (1,-40) [-40|200] "C"  PT
 SG_ cmbOnboardHumidity08_BMS05 m8 : 23|8@0+ (0.5,0) [0|120] "PCT"  PT
 SG_ moduleHeaterCurrent08_BMS05 m8 : 31|8@0+ (0.05,0) [0|10] "A"  PT
 SG_ cmbOnboardTemperature09_BMS05 m9 : 15|8@0+ (1,-40) [-40|200] "C"  PT
 SG_ cmbOnboardHumidity09_BMS05 m9 : 23|8@0+ (0.5,0) [0|120] "PCT"  PT
 SG_ moduleHeaterCurrent09_BMS05 m9 : 31|8@0+ (0.05,0) [0|10] "A"  PT
 SG_ cmbOnboardTemperature10_BMS05 m10 : 15|8@0+ (1,-40) [-40|200] "C"  PT
 SG_ cmbOnboardHumidity10_BMS05 m10 : 23|8@0+ (0.5,0) [0|120] "PCT"  PT
 SG_ moduleHeaterCurrent10_BMS05 m10 : 31|8@0+ (0.05,0) [0|10] "A"  PT
 SG_ cmbOnboardTemperature11_BMS05 m11 : 15|8@0+ (1,-40) [-40|200] "C"  PT
 SG_ cmbOnboardHumidity11_BMS05 m11 : 23|8@0+ (0.5,0) [0|120] "PCT"  PT
 SG_ moduleHeaterCurrent11_BMS05 m11 : 31|8@0+ (0.05,0) [0|10] "A"  PT
 SG_ cmbOnboardTemperature12_BMS05 m12 : 15|8@0+ (1,-40) [-40|200] "C"  PT
 SG_ cmbOnboardHumidity12_BMS05 m12 : 23|8@0+ (0.5,0) [0|120] "PCT"  PT
 SG_ moduleHeaterCurrent12_BMS05 m12 : 31|8@0+ (0.05,0) [0|10] "A"  PT
 SG_ cmbOnboardTemperature13_BMS05 m13 : 15|8@0+ (1,-40) [-40|200] "C"  PT
 SG_ cmbOnboardHumidity13_BMS05 m13 : 23|8@0+ (0.5,0) [0|120] "PCT"  PT
 SG_ moduleHeaterCurrent13_BMS05 m13 : 31|8@0+ (0.05,0) [0|10] "A"  PT
 SG_ cmbOnboardTemperature14_BMS05 m14 : 15|8@0+ (1,-40) [-40|200] "C"  PT
 SG_ cmbOnboardHumidity14_BMS05 m14 : 23|8@0+ (0.5,0) [0|120] "PCT"  PT
 SG_ moduleHeaterCurrent14_BMS05 m14 : 31|8@0+ (0.05,0) [0|10] "A"  PT
 SG_ cmbOnboardTemperature15_BMS05 m15 : 15|8@0+ (1,-40) [-40|200] "C"  PT
 SG_ cmbOnboardHumidity15_BMS05 m15 : 23|8@0+ (0.5,0) [0|120] "PCT"  PT
 SG_ moduleHeaterCurrent15_BMS05 m15 : 31|8@0+ (0.05,0) [0|10] "A"  PT
 SG_ cmbOnboardTemperature16_BMS05 m16 : 15|8@0+ (1,-40) [-40|200] "C"  PT
 SG_ cmbOnboardHumidity16_BMS05 m16 : 23|8@0+ (0.5,0) [0|120] "PCT"  PT
 SG_ moduleHeaterCurrent16_BMS05 m16 : 31|8@0+ (0.05,0) [0|10] "A"  PT
 SG_ cmbOnboardTemperature17_BMS05 m17 : 15|8@0+ (1,-40) [-40|200] "C"  PT
 SG_ cmbOnboardHumidity17_BMS05 m17 : 23|8@0+ (0.5,0) [0|120] "PCT"  PT
 SG_ moduleHeaterCurrent17_BMS05 m17 : 31|8@0+ (0.05,0) [0|10] "A"  PT
 SG_ cmbOnboardTemperature18_BMS05 m18 : 15|8@0+ (1,-40) [-40|200] "C"  PT
 SG_ cmbOnboardHumidity18_BMS05 m18 : 23|8@0+ (0.5,0) [0|120] "PCT"  PT
 SG_ moduleHeaterCurrent18_BMS05 m18 : 31|8@0+ (0.05,0) [0|10] "A"  PT
 SG_ cmbOnboardTemperature19_BMS05 m19 : 15|8@0+ (1,-40) [-40|200] "C"  PT
 SG_ cmbOnboardHumidity19_BMS05 m19 : 23|8@0+ (0.5,0) [0|120] "PCT"  PT
 SG_ moduleHeaterCurrent19_BMS05 m19 : 31|8@0+ (0.05,0) [0|10] "A"  PT
 SG_ cmbOnboardTemperature20_BMS05 m20 : 15|8@0+ (1,-40) [-40|200] "C"  PT
 SG_ cmbOnboardHumidity20_BMS05 m20 : 23|8@0+ (0.5,0) [0|120] "PCT"  PT
 SG_ moduleHeaterCurrent20_BMS05 m20 : 31|8@0+ (0.05,0) [0|10] "A"  PT
 SG_ cmbOnboardTemperature21_BMS05 m21 : 15|8@0+ (1,-40) [-40|200] "C"  PT
 SG_ cmbOnboardHumidity21_BMS05 m21 : 23|8@0+ (0.5,0) [0|120] "PCT"  PT
 SG_ moduleHeaterCurrent21_BMS05 m21 : 31|8@0+ (0.05,0) [0|10] "A"  PT
 SG_ cmbOnboardTemperature22_BMS05 m22 : 15|8@0+ (1,-40) [-40|200] "C"  PT
 SG_ cmbOnboardHumidity22_BMS05 m22 : 23|8@0+ (0.5,0) [0|120] "PCT"  PT
 SG_ moduleHeaterCurrent22_BMS05 m22 : 31|8@0+ (0.05,0) [0|10] "A"  PT
 SG_ cmbOnboardTemperature23_BMS05 m23 : 15|8@0+ (1,-40) [-40|200] "C"  PT
 SG_ cmbOnboardHumidity23_BMS05 m23 : 23|8@0+ (0.5,0) [0|120] "PCT"  PT
 SG_ moduleHeaterCurrent23_BMS05 m23 : 31|8@0+ (0.05,0) [0|10] "A"  PT
 SG_ cmbOnboardTemperature24_BMS05 m24 : 15|8@0+ (1,-40) [-40|200] "C"  PT
 SG_ cmbOnboardHumidity24_BMS05 m24 : 23|8@0+ (0.5,0) [0|120] "PCT"  PT
 SG_ moduleHeaterCurrent24_BMS05 m24 : 31|8@0+ (0.05,0) [0|10] "A"  PT
 SG_ cmbOnboardTemperature25_BMS05 m25 : 15|8@0+ (1,-40) [-40|200] "C"  PT
 SG_ cmbOnboardHumidity25_BMS05 m25 : 23|8@0+ (0.5,0) [0|120] "PCT"  PT
 SG_ moduleHeaterCurrent25_BMS05 m25 : 31|8@0+ (0.05,0) [0|10] "A"  PT
 SG_ cmbOnboardTemperature26_BMS05 m26 : 15|8@0+ (1,-40) [-40|200] "C"  PT
 SG_ cmbOnboardHumidity26_BMS05 m26 : 23|8@0+ (0.5,0) [0|120] "PCT"  PT
 SG_ moduleHeaterCurrent26_BMS05 m26 : 31|8@0+ (0.05,0) [0|10] "A"  PT
 SG_ cmbOnboardTemperature27_BMS05 m27 : 15|8@0+ (1,-40) [-40|200] "C"  PT
 SG_ cmbOnboardHumidity27_BMS05 m27 : 23|8@0+ (0.5,0) [0|120] "PCT"  PT
 SG_ moduleHeaterCurrent27_BMS05 m27 : 31|8@0+ (0.05,0) [0|10] "A"  PT
 SG_ cmbOnboardTemperature28_BMS05 m28 : 15|8@0+ (1,-40) [-40|200] "C"  PT
 SG_ cmbOnboardHumidity28_BMS05 m28 : 23|8@0+ (0.5,0) [0|120] "PCT"  PT
 SG_ moduleHeaterCurrent28_BMS05 m28 : 31|8@0+ (0.05,0) [0|10] "A"  PT
 SG_ cmbOnboardTemperature29_BMS05 m29 : 15|8@0+ (1,-40) [-40|200] "C"  PT
 SG_ cmbOnboardHumidity29_BMS05 m29 : 23|8@0+ (0.5,0) [0|120] "PCT"  PT
 SG_ moduleHeaterCurrent29_BMS05 m29 : 31|8@0+ (0.05,0) [0|10] "A"  PT
 SG_ cmbOnboardTemperature30_BMS05 m30 : 15|8@0+ (1,-40) [-40|200] "C"  PT
 SG_ cmbOnboardHumidity30_BMS05 m30 : 23|8@0+ (0.5,0) [0|120] "PCT"  PT
 SG_ moduleHeaterCurrent30_BMS05 m30 : 31|8@0+ (0.05,0) [0|10] "A"  PT
 SG_ cmbOnboardTemperature31_BMS05 m31 : 15|8@0+ (1,-40) [-40|200] "C"  PT
 SG_ cmbOnboardHumidity31_BMS05 m31 : 23|8@0+ (0.5,0) [0|120] "PCT"  PT
 SG_ moduleHeaterCurrent31_BMS05 m31 : 31|8@0+ (0.05,0) [0|10] "A"  PT
 SG_ cmbOnboardTemperature32_BMS05 m32 : 15|8@0+ (1,-40) [-40|200] "C"  PT
 SG_ cmbOnboardHumidity32_BMS05 m32 : 23|8@0+ (0.5,0) [0|120] "PCT"  PT
 SG_ moduleHeaterCurrent32_BMS05 m32 : 31|8@0+ (0.05,0) [0|10] "A"  PT

BA_DEF_ SG_  "GenSigSendType" ENUM  "Cyclic","OnWrite","OnWriteWithRepetition","OnChange","OnChangeWithRepetition","IfActive","IfActiveWithRepetition","NoSigSendType";
BA_DEF_ BO_  "GenMsgCycleTime" INT 0 0;
BA_DEF_ BO_  "GenMsgSendType" ENUM  "Cyclic","not_used","not_used","not_used","not_used","Cyclic","not_used","IfActive","NoMsgSendType";
BA_DEF_DEF_  "GenSigSendType" "Cyclic";
BA_DEF_DEF_  "GenMsgCycleTime" 0;
BA_DEF_DEF_  "GenMsgSendType" "NoMsgSendType";
BA_ "GenMsgCycleTime" BO_ 1860 1000;
BA_ "GenMsgCycleTime" BO_ 1732 100;
BA_ "GenMsgCycleTime" BO_ 1028 1000;
BA_ "GenMsgCycleTime" BO_ 1092 1000;
BA_ "GenMsgCycleTime" BO_ 1156 1000;
BA_ "GenMsgCycleTime" BO_ 1220 1000;
BA_ "GenMsgCycleTime" BO_ 1284 1000;
BA_ "GenMsgCycleTime" BO_ 1348 1000;
BA_ "GenMsgCycleTime" BO_ 1412 1000;
BA_ "GenMsgCycleTime" BO_ 1476 1000;
BA_ "GenMsgCycleTime" BO_ 1604 100;
BA_ "GenMsgCycleTime" BO_ 1668 10;
BA_ "GenMsgCycleTime" BO_ 1924 100;
VAL_ 1860 SOHRecentChange_BMS05 255 "SNA" ;
VAL_ 1860 SOHConvergenceIndicator_BMS05 255 "SNA" ;
VAL_ 1860 SOHConvergenceCounter_BMS05 255 "SNA" ;
VAL_ 1860 SOHMinFiltered_BMS05 255 "SNA" ;
VAL_ 1860 medianModuleTempGrp2_BMS05 255 "SNA" ;
VAL_ 1860 medianModuleTempGrp1_BMS05 255 "SNA" ;
VAL_ 1860 coolantWarningtAlert_BMS05 3 "SNA" 2 "COOLANT_FLOOD_WARNING" 0 "COOLANT_NOWARNING" 1 "COOLANT_MOISTURE_WARNING" ;
VAL_ 1860 coolantFaultAlert_BMS05 3 "SNA" 2 "COOLANT_FLOOD_FAULT" 0 "COOLANT_NOFAULT" 1 "COOLANT_MOISTURE_FAULT" ;
VAL_ 1860 hvilShutdownStrategy_BMS05 4 "Strategy_4" 3 "Strategy_3" 2 "Strategy_2" 1 "Strategy_1" 0 "Strategy_0" ;
VAL_ 1860 J1939_nmState 3 "J1939_NM_INACTIVE" 2 "J1939_NM_ACTIVE" 1 "J1939_NM_STARTUP" 0 "J1939_NM_INIT" ;
VAL_ 1860 PrechargeXCapMin_BMS05 65535 "SNA" ;
VAL_ 1860 LimpHomeTimeOut_BMS05 65535 "SNA" ;
VAL_ 1860 hvWithstandTests_BMS05 255 "SNA" ;
VAL_ 1860 aux3prechargeState_BMS05 15 "CTR_PRCHG_NEG_OPEN" 13 "CTR_PRCHG_POS_WELD_CHECK" 12 "CTR_PRCHG_PRE_COND_CHECK" 11 "CTR_PRCHG_NEG2_WELD_CHECK" 10 "CTR_PRCHG_CLOSEMID" 9 "CTR_PRCHG_CLOSEAUX" 8 "CTR_PRCHG_FAILED" 7 "CTR_PRCHG_COMPLETE" 6 "CTR_PRCHG_CLOSE_POS" 5 "CTR_PRCHG_MONITOR_VOLTAGE" 4 "CTR_PRCHG_CLOSE_NEG" 3 "CTR_PRCHG_NEG_WELD_CHECK" 2 "CTR_PRCHG_CLOSE_RELAY" 1 "CTR_PRCHG_WELD_CHECK" 0 "CTR_PRCHG_OFF" ;
VAL_ 1860 aux2prechargeState_BMS05 15 "CTR_PRCHG_NEG_OPEN" 13 "CTR_PRCHG_POS_WELD_CHECK" 12 "CTR_PRCHG_PRE_COND_CHECK" 11 "CTR_PRCHG_NEG2_WELD_CHECK" 10 "CTR_PRCHG_CLOSEMID" 9 "CTR_PRCHG_CLOSEAUX" 8 "CTR_PRCHG_FAILED" 7 "CTR_PRCHG_COMPLETE" 6 "CTR_PRCHG_CLOSE_POS" 5 "CTR_PRCHG_MONITOR_VOLTAGE" 4 "CTR_PRCHG_CLOSE_NEG" 3 "CTR_PRCHG_NEG_WELD_CHECK" 2 "CTR_PRCHG_CLOSE_RELAY" 1 "CTR_PRCHG_WELD_CHECK" 0 "CTR_PRCHG_OFF" ;
VAL_ 1860 aux1prechargeState_BMS05 15 "CTR_PRCHG_NEG_OPEN" 13 "CTR_PRCHG_POS_WELD_CHECK" 12 "CTR_PRCHG_PRE_COND_CHECK" 11 "CTR_PRCHG_NEG2_WELD_CHECK" 10 "CTR_PRCHG_CLOSEMID" 9 "CTR_PRCHG_CLOSEAUX" 8 "CTR_PRCHG_FAILED" 7 "CTR_PRCHG_COMPLETE" 6 "CTR_PRCHG_CLOSE_POS" 5 "CTR_PRCHG_MONITOR_VOLTAGE" 4 "CTR_PRCHG_CLOSE_NEG" 3 "CTR_PRCHG_NEG_WELD_CHECK" 2 "CTR_PRCHG_CLOSE_RELAY" 1 "CTR_PRCHG_WELD_CHECK" 0 "CTR_PRCHG_OFF" ;
VAL_ 1860 auxLinkVoltage_BMS05 65535 "SNA" ;
VAL_ 1860 rangeRequestIgnoreVehicle 255 "NO_COMMAND" 1 "IGNORE" 0 "DO_NOT_IGNORE" ;
VAL_ 1860 rangeRequestEepromValue 255 "NO_COMMAND" 15 "RANGE_INVALID" 14 "RANGE_MAXIMUM" 13 "RANGE_MODESOH8" 12 "RANGE_MODESOH7" 11 "RANGE_MODESOH6" 10 "RANGE_MODESOH5" 9 "RANGE_MODESOH4" 8 "RANGE_MODESOH3" 7 "RANGE_MODESOH2" 6 "RANGE_MODESOH1" 5 "RANGE_MODE407" 4 "RANGE_MODE405" 3 "RANGE_MODE4175" 2 "RANGE_MODE415" 1 "RANGE_LIMITED" 0 "RANGE_SHIPPING" ;
VAL_ 1860 pressure2_BMS05 255 "SNA" ;
VAL_ 1860 calibration_version_BMS05 255 "SNA" ;
VAL_ 1860 currentLowTimer_BMS05 65535 "SNA" ;
VAL_ 1860 auxCntrrOpenUnderLoadCntr_BMS05 65535 "SNA" ;
VAL_ 1860 rabbitContactorState_BMS05 5 "FAILURE" 4 "CLOSE" 3 "EXT_ISO_TEST" 2 "AUX_CLOSE" 1 "INT_ISO_TEST" 0 "OPEN" ;
VAL_ 1860 analogIsenseSupplyCurr_BMS05 255 "SNA" ;
VAL_ 1860 pumpSpeedReqCoolPrfmc_BMS05 255 "SNA" ;
VAL_ 1860 microsarOs_IdleTask_OsCr0_BMS05 255 "SNA" ;
VAL_ 1860 microsarOs_BswTask_BMS05 255 "SNA" ;
VAL_ 1860 microsarOs_InitTask_BMS05 255 "SNA" ;
VAL_ 1860 microsarOs_ApplTask_1Hz_BMS05 255 "SNA" ;
VAL_ 1860 microsarOs_ApplTask_10Hz_BMS05 255 "SNA" ;
VAL_ 1860 microsarOs_ApplTask_100Hz_BMS05 255 "SNA" ;
VAL_ 1860 microsarOs_ApplLowTask_BMS05 255 "SNA" ;
VAL_ 1860 microsarOs_ApplLateInit_BMS05 255 "SNA" ;
VAL_ 1860 microsarOs_ApplHighTask_BMS05 255 "SNA" ;
VAL_ 1860 microsarOs_ApplEarlyInit_BMS05 255 "SNA" ;
VAL_ 1860 appTaskBSWMaxDuration_BMS05 255 "SNA" ;
VAL_ 1860 appTaskApplHighMaxDuration_BMS05 255 "SNA" ;
VAL_ 1860 appTask1HzMaxDuration_BMS05 255 "SNA" ;
VAL_ 1860 appTask100HzMaxDuration_BMS05 255 "SNA" ;
VAL_ 1860 appTask10HzMaxDuration_BMS05 255 "SNA" ;
VAL_ 1860 appTask100HzDuration_BMS05 255 "SNA" ;
VAL_ 1860 appTask10HzDuration_BMS05 255 "SNA" ;
VAL_ 1860 appTask1HzDuration_BMS05 255 "SNA" ;
VAL_ 1860 appTaskBSWDuration_BMS05 255 "SNA" ;
VAL_ 1860 appTaskApplHighDuration_BMS05 255 "SNA" ;
VAL_ 1860 iumprMaxRatioDTCId_BMS05 0 "SNA" ;
VAL_ 1860 iumprMaxRatio_BMS05 0 "SNA" ;
VAL_ 1860 iumprMinRatioDTCId_BMS05 0 "SNA" ;
VAL_ 1860 iumprMinRatio_BMS05 0 "SNA" ;
VAL_ 1860 fluidLvlCount_BMS05 255 "SNA" ;
VAL_ 1860 fluidLvlSensr2_BMS05 3 "FLUIDLEVEL_ERROR" 2 "FLUIDLEVEL_OIL" 1 "FLUIDLEVEL_AIR" 0 "FLUIDLEVEL_SNA" ;
VAL_ 1860 fluidLvlSensr1_BMS05 3 "FLUIDLEVEL_ERROR" 2 "FLUIDLEVEL_OIL" 1 "FLUIDLEVEL_AIR" 0 "FLUIDLEVEL_SNA" ;
VAL_ 1860 pumpSpeedReqVhcleSpeed_BMS05 255 "SNA" ;
VAL_ 1860 appTaskBSWCpuUsage_BMS05 255 "SNA" ;
VAL_ 1860 appTask200HzCpuUsage_BMS05 255 "SNA" ;
VAL_ 1860 pyroState_BMS05 7 "PYRO_FIRE" 6 "PYRO_DIAG_PASS" 5 "PYRO_DIAG_FAIL" 4 "PYRO_DIAG_LS_ON" 3 "PYRO_DIAG_OPEN" 2 "PYRO_DIAG_HS_ON" 1 "PYRO_DIAG_INIT" 0 "PYRO_INACTIVE" ;
VAL_ 1860 ecuSerialNrChar15_BMS05 90 "'Z'" 89 "'Y'" 88 "'X'" 87 "'W'" 86 "'V'" 85 "'U'" 84 "'T'" 83 "'S'" 82 "'R'" 81 "'Q'" 80 "'P'" 79 "'O'" 78 "'N'" 77 "'M'" 76 "'L'" 75 "'K'" 74 "'J'" 73 "'I'" 72 "'H'" 71 "'G'" 70 "'F'" 69 "'E'" 68 "'D'" 67 "'C'" 66 "'B'" 65 "'A'" 57 "'9'" 56 "'8'" 55 "'7'" 54 "'6'" 53 "'5'" 52 "'4'" 51 "'3'" 50 "'2'" 49 "'1'" 48 "'0'" ;
VAL_ 1860 ecuSerialNrChar14_BMS05 90 "'Z'" 89 "'Y'" 88 "'X'" 87 "'W'" 86 "'V'" 85 "'U'" 84 "'T'" 83 "'S'" 82 "'R'" 81 "'Q'" 80 "'P'" 79 "'O'" 78 "'N'" 77 "'M'" 76 "'L'" 75 "'K'" 74 "'J'" 73 "'I'" 72 "'H'" 71 "'G'" 70 "'F'" 69 "'E'" 68 "'D'" 67 "'C'" 66 "'B'" 65 "'A'" 57 "'9'" 56 "'8'" 55 "'7'" 54 "'6'" 53 "'5'" 52 "'4'" 51 "'3'" 50 "'2'" 49 "'1'" 48 "'0'" ;
VAL_ 1860 ecuSerialNrChar13_BMS05 90 "'Z'" 89 "'Y'" 88 "'X'" 87 "'W'" 86 "'V'" 85 "'U'" 84 "'T'" 83 "'S'" 82 "'R'" 81 "'Q'" 80 "'P'" 79 "'O'" 78 "'N'" 77 "'M'" 76 "'L'" 75 "'K'" 74 "'J'" 73 "'I'" 72 "'H'" 71 "'G'" 70 "'F'" 69 "'E'" 68 "'D'" 67 "'C'" 66 "'B'" 65 "'A'" 57 "'9'" 56 "'8'" 55 "'7'" 54 "'6'" 53 "'5'" 52 "'4'" 51 "'3'" 50 "'2'" 49 "'1'" 48 "'0'" ;
VAL_ 1860 ecuSerialNrChar12_BMS05 90 "'Z'" 89 "'Y'" 88 "'X'" 87 "'W'" 86 "'V'" 85 "'U'" 84 "'T'" 83 "'S'" 82 "'R'" 81 "'Q'" 80 "'P'" 79 "'O'" 78 "'N'" 77 "'M'" 76 "'L'" 75 "'K'" 74 "'J'" 73 "'I'" 72 "'H'" 71 "'G'" 70 "'F'" 69 "'E'" 68 "'D'" 67 "'C'" 66 "'B'" 65 "'A'" 57 "'9'" 56 "'8'" 55 "'7'" 54 "'6'" 53 "'5'" 52 "'4'" 51 "'3'" 50 "'2'" 49 "'1'" 48 "'0'" ;
VAL_ 1860 ecuSerialNrChar11_BMS05 90 "'Z'" 89 "'Y'" 88 "'X'" 87 "'W'" 86 "'V'" 85 "'U'" 84 "'T'" 83 "'S'" 82 "'R'" 81 "'Q'" 80 "'P'" 79 "'O'" 78 "'N'" 77 "'M'" 76 "'L'" 75 "'K'" 74 "'J'" 73 "'I'" 72 "'H'" 71 "'G'" 70 "'F'" 69 "'E'" 68 "'D'" 67 "'C'" 66 "'B'" 65 "'A'" 57 "'9'" 56 "'8'" 55 "'7'" 54 "'6'" 53 "'5'" 52 "'4'" 51 "'3'" 50 "'2'" 49 "'1'" 48 "'0'" ;
VAL_ 1860 ecuSerialNrChar10_BMS05 90 "'Z'" 89 "'Y'" 88 "'X'" 87 "'W'" 86 "'V'" 85 "'U'" 84 "'T'" 83 "'S'" 82 "'R'" 81 "'Q'" 80 "'P'" 79 "'O'" 78 "'N'" 77 "'M'" 76 "'L'" 75 "'K'" 74 "'J'" 73 "'I'" 72 "'H'" 71 "'G'" 70 "'F'" 69 "'E'" 68 "'D'" 67 "'C'" 66 "'B'" 65 "'A'" 57 "'9'" 56 "'8'" 55 "'7'" 54 "'6'" 53 "'5'" 52 "'4'" 51 "'3'" 50 "'2'" 49 "'1'" 48 "'0'" ;
VAL_ 1860 ecuSerialNrChar09_BMS05 90 "'Z'" 89 "'Y'" 88 "'X'" 87 "'W'" 86 "'V'" 85 "'U'" 84 "'T'" 83 "'S'" 82 "'R'" 81 "'Q'" 80 "'P'" 79 "'O'" 78 "'N'" 77 "'M'" 76 "'L'" 75 "'K'" 74 "'J'" 73 "'I'" 72 "'H'" 71 "'G'" 70 "'F'" 69 "'E'" 68 "'D'" 67 "'C'" 66 "'B'" 65 "'A'" 57 "'9'" 56 "'8'" 55 "'7'" 54 "'6'" 53 "'5'" 52 "'4'" 51 "'3'" 50 "'2'" 49 "'1'" 48 "'0'" ;
VAL_ 1860 ecuSerialNrChar08_BMS05 90 "'Z'" 89 "'Y'" 88 "'X'" 87 "'W'" 86 "'V'" 85 "'U'" 84 "'T'" 83 "'S'" 82 "'R'" 81 "'Q'" 80 "'P'" 79 "'O'" 78 "'N'" 77 "'M'" 76 "'L'" 75 "'K'" 74 "'J'" 73 "'I'" 72 "'H'" 71 "'G'" 70 "'F'" 69 "'E'" 68 "'D'" 67 "'C'" 66 "'B'" 65 "'A'" 57 "'9'" 56 "'8'" 55 "'7'" 54 "'6'" 53 "'5'" 52 "'4'" 51 "'3'" 50 "'2'" 49 "'1'" 48 "'0'" ;
VAL_ 1860 ecuSerialNrChar07_BMS05 90 "'Z'" 89 "'Y'" 88 "'X'" 87 "'W'" 86 "'V'" 85 "'U'" 84 "'T'" 83 "'S'" 82 "'R'" 81 "'Q'" 80 "'P'" 79 "'O'" 78 "'N'" 77 "'M'" 76 "'L'" 75 "'K'" 74 "'J'" 73 "'I'" 72 "'H'" 71 "'G'" 70 "'F'" 69 "'E'" 68 "'D'" 67 "'C'" 66 "'B'" 65 "'A'" 57 "'9'" 56 "'8'" 55 "'7'" 54 "'6'" 53 "'5'" 52 "'4'" 51 "'3'" 50 "'2'" 49 "'1'" 48 "'0'" ;
VAL_ 1860 ecuSerialNrChar06_BMS05 90 "'Z'" 89 "'Y'" 88 "'X'" 87 "'W'" 86 "'V'" 85 "'U'" 84 "'T'" 83 "'S'" 82 "'R'" 81 "'Q'" 80 "'P'" 79 "'O'" 78 "'N'" 77 "'M'" 76 "'L'" 75 "'K'" 74 "'J'" 73 "'I'" 72 "'H'" 71 "'G'" 70 "'F'" 69 "'E'" 68 "'D'" 67 "'C'" 66 "'B'" 65 "'A'" 57 "'9'" 56 "'8'" 55 "'7'" 54 "'6'" 53 "'5'" 52 "'4'" 51 "'3'" 50 "'2'" 49 "'1'" 48 "'0'" ;
VAL_ 1860 ecuSerialNrChar05_BMS05 90 "'Z'" 89 "'Y'" 88 "'X'" 87 "'W'" 86 "'V'" 85 "'U'" 84 "'T'" 83 "'S'" 82 "'R'" 81 "'Q'" 80 "'P'" 79 "'O'" 78 "'N'" 77 "'M'" 76 "'L'" 75 "'K'" 74 "'J'" 73 "'I'" 72 "'H'" 71 "'G'" 70 "'F'" 69 "'E'" 68 "'D'" 67 "'C'" 66 "'B'" 65 "'A'" 57 "'9'" 56 "'8'" 55 "'7'" 54 "'6'" 53 "'5'" 52 "'4'" 51 "'3'" 50 "'2'" 49 "'1'" 48 "'0'" ;
VAL_ 1860 analogGPIO1Current_BMS05 255 "SNA" ;
VAL_ 1860 analogGPIO1Volt_BMS05 255 "SNA" ;
VAL_ 1860 analogGPIO2Current_BMS05 255 "SNA" ;
VAL_ 1860 analogGPIO2Volt_BMS05 255 "SNA" ;
VAL_ 1860 pumpSpeedReqLoadValue_BMS05 255 "SNA" ;
VAL_ 1860 ssaRTMonth_BMS05 255 "SNA" ;
VAL_ 1860 ssaRTDay_BMS05 255 "SNA" ;
VAL_ 1860 appTask50HzStackUsage_BMS05 255 "SNA" ;
VAL_ 1860 OBDMILRequested_BMS05 3 "MIL_SNA" 1 "MIL_ON" 0 "MIL_OFF" ;
VAL_ 1860 OBDConfirmedDTCsCount_BMS05 255 "SNA" ;
VAL_ 1860 OBDFirstConfirmedDTC_BMS05 255 "SNA" ;
VAL_ 1860 OBDPermanentDTCCount_BMS05 255 "SNA" ;
VAL_ 1860 OBDFirstPermanentDTC_BMS05 255 "SNA" ;
VAL_ 1860 nmStartupReason_BMS05 15 "NM_STARTUP_INVALID" 7 "NM_STARTUP_TESTERPRESENT" 6 "NM_STARTUP_RQ" 5 "NM_STARTUP_CAN" 4 "NM_STARTUP_THERMALEVENT" 3 "NM_STARTUP_AUXCONTACTORS" 2 "NM_STARTUP_CONTACTORS" 1 "NM_STARTUP_KEY" 0 "NM_STARTUP_NOSTARTUP" ;
VAL_ 1860 contactorType_BMS05 15 "SNA" 1 "GV240_12V" 0 "CTR_TYPE_CALIBRATION (GV240_24V)" ;
VAL_ 1860 activeIsoTestDuration_BMS05 255 "SNA" ;
VAL_ 1860 balancingState_BMS05 6 "BALANCING_OFF_TEMP_SHUTDOWN" 5 "BALANCING_OFF_VOLTAGE_SHUTDOWN" 4 "BALANCING_ON_DCM_EEPROM" 3 "BALANCING_ON_DCM_BRICK" 2 "BALANCING_ON_DCM_PATTERN" 1 "BALANCING_ON_ME_APP" 0 "BALANCING_OFF" ;
VAL_ 1860 chronoStackWrCnt_BMS05 -1 "SNA" ;
VAL_ 1860 wakeReason_BMS05 6 "ECU_WAKEREASON_MCUWDG" 14 "ECU_WAKEREASON_INIT" 15 "ECU_WAKEREASON_UNKNOWN" 5 "ECU_WAKEREASON_AUTO" 4 "ECU_WAKEREASON_POR" 3 "ECU_WAKEREASON_CLOCK" 2 "ECU_WAKEREASON_PRESSURE" 1 "ECU_WAKEREASON_CAN" 0 "ECU_WAKEREASON_KEY" ;
VAL_ 1860 coolantOutletTemperature_BMS05 255 "SNA" ;
VAL_ 1860 coolantInletTemperature_BMS05 255 "SNA" ;
VAL_ 1860 variantCodingCount_BMS05 65535 "SNA" ;
VAL_ 1860 SWVersionCusApp_BMS05 -1 "SNA" ;
VAL_ 1860 contactorOpenRequest_BMS05 15 "CTR_OPEN_INVALID" 1 "CTR_OPEN_IMMEDIATE" 0 "CTR_OPEN_FAST " ;
VAL_ 1860 maxBrickVoltageChargeLimit_BMS05 65535 "SNA" ;
VAL_ 1860 desiccantTimer_BMS05 -1 "SNA" ;
VAL_ 1860 batSwitchOpenReason_BMS05 65535 "SNA" ;
VAL_ 1860 balancingTime_BMS05 65535 "SNA" ;
VAL_ 1860 ecuSerialNrChar01_BMS05 90 "'Z'" 89 "'Y'" 88 "'X'" 87 "'W'" 86 "'V'" 85 "'U'" 84 "'T'" 83 "'S'" 82 "'R'" 81 "'Q'" 80 "'P'" 79 "'O'" 78 "'N'" 77 "'M'" 76 "'L'" 75 "'K'" 74 "'J'" 73 "'I'" 72 "'H'" 71 "'G'" 70 "'F'" 69 "'E'" 68 "'D'" 67 "'C'" 66 "'B'" 65 "'A'" 57 "'9'" 56 "'8'" 55 "'7'" 54 "'6'" 53 "'5'" 52 "'4'" 51 "'3'" 50 "'2'" 49 "'1'" 48 "'0'" ;
VAL_ 1860 ecuSerialNrChar02_BMS05 90 "'Z'" 89 "'Y'" 88 "'X'" 87 "'W'" 86 "'V'" 85 "'U'" 84 "'T'" 83 "'S'" 82 "'R'" 81 "'Q'" 80 "'P'" 79 "'O'" 78 "'N'" 77 "'M'" 76 "'L'" 75 "'K'" 74 "'J'" 73 "'I'" 72 "'H'" 71 "'G'" 70 "'F'" 69 "'E'" 68 "'D'" 67 "'C'" 66 "'B'" 65 "'A'" 57 "'9'" 56 "'8'" 55 "'7'" 54 "'6'" 53 "'5'" 52 "'4'" 51 "'3'" 50 "'2'" 49 "'1'" 48 "'0'" ;
VAL_ 1860 ecuSerialNrChar03_BMS05 90 "'Z'" 89 "'Y'" 88 "'X'" 87 "'W'" 86 "'V'" 85 "'U'" 84 "'T'" 83 "'S'" 82 "'R'" 81 "'Q'" 80 "'P'" 79 "'O'" 78 "'N'" 77 "'M'" 76 "'L'" 75 "'K'" 74 "'J'" 73 "'I'" 72 "'H'" 71 "'G'" 70 "'F'" 69 "'E'" 68 "'D'" 67 "'C'" 66 "'B'" 65 "'A'" 57 "'9'" 56 "'8'" 55 "'7'" 54 "'6'" 53 "'5'" 52 "'4'" 51 "'3'" 50 "'2'" 49 "'1'" 48 "'0'" ;
VAL_ 1860 ecuSerialNrChar04_BMS05 90 "'Z'" 89 "'Y'" 88 "'X'" 87 "'W'" 86 "'V'" 85 "'U'" 84 "'T'" 83 "'S'" 82 "'R'" 81 "'Q'" 80 "'P'" 79 "'O'" 78 "'N'" 77 "'M'" 76 "'L'" 75 "'K'" 74 "'J'" 73 "'I'" 72 "'H'" 71 "'G'" 70 "'F'" 69 "'E'" 68 "'D'" 67 "'C'" 66 "'B'" 65 "'A'" 57 "'9'" 56 "'8'" 55 "'7'" 54 "'6'" 53 "'5'" 52 "'4'" 51 "'3'" 50 "'2'" 49 "'1'" 48 "'0'" ;
VAL_ 1860 ecuSerialNrChar16_BMS05 90 "'Z'" 89 "'Y'" 88 "'X'" 87 "'W'" 86 "'V'" 85 "'U'" 84 "'T'" 83 "'S'" 82 "'R'" 81 "'Q'" 80 "'P'" 79 "'O'" 78 "'N'" 77 "'M'" 76 "'L'" 75 "'K'" 74 "'J'" 73 "'I'" 72 "'H'" 71 "'G'" 70 "'F'" 69 "'E'" 68 "'D'" 67 "'C'" 66 "'B'" 65 "'A'" 57 "'9'" 56 "'8'" 55 "'7'" 54 "'6'" 53 "'5'" 52 "'4'" 51 "'3'" 50 "'2'" 49 "'1'" 48 "'0'" ;
VAL_ 1860 ecuSerialNrChar17_BMS05 90 "'Z'" 89 "'Y'" 88 "'X'" 87 "'W'" 86 "'V'" 85 "'U'" 84 "'T'" 83 "'S'" 82 "'R'" 81 "'Q'" 80 "'P'" 79 "'O'" 78 "'N'" 77 "'M'" 76 "'L'" 75 "'K'" 74 "'J'" 73 "'I'" 72 "'H'" 71 "'G'" 70 "'F'" 69 "'E'" 68 "'D'" 67 "'C'" 66 "'B'" 65 "'A'" 57 "'9'" 56 "'8'" 55 "'7'" 54 "'6'" 53 "'5'" 52 "'4'" 51 "'3'" 50 "'2'" 49 "'1'" 48 "'0'" ;
VAL_ 1860 ecuSerialNrChar18_BMS05 90 "'Z'" 89 "'Y'" 88 "'X'" 87 "'W'" 86 "'V'" 85 "'U'" 84 "'T'" 83 "'S'" 82 "'R'" 81 "'Q'" 80 "'P'" 79 "'O'" 78 "'N'" 77 "'M'" 76 "'L'" 75 "'K'" 74 "'J'" 73 "'I'" 72 "'H'" 71 "'G'" 70 "'F'" 69 "'E'" 68 "'D'" 67 "'C'" 66 "'B'" 65 "'A'" 57 "'9'" 56 "'8'" 55 "'7'" 54 "'6'" 53 "'5'" 52 "'4'" 51 "'3'" 50 "'2'" 49 "'1'" 48 "'0'" ;
VAL_ 1860 ecuSerialNrChar19_BMS05 90 "'Z'" 89 "'Y'" 88 "'X'" 87 "'W'" 86 "'V'" 85 "'U'" 84 "'T'" 83 "'S'" 82 "'R'" 81 "'Q'" 80 "'P'" 79 "'O'" 78 "'N'" 77 "'M'" 76 "'L'" 75 "'K'" 74 "'J'" 73 "'I'" 72 "'H'" 71 "'G'" 70 "'F'" 69 "'E'" 68 "'D'" 67 "'C'" 66 "'B'" 65 "'A'" 57 "'9'" 56 "'8'" 55 "'7'" 54 "'6'" 53 "'5'" 52 "'4'" 51 "'3'" 50 "'2'" 49 "'1'" 48 "'0'" ;
VAL_ 1860 maxModuleTemperature_BMS05 255 "SNA" ;
VAL_ 1860 meanModuleTemperature_BMS05 255 "SNA" ;
VAL_ 1860 minModuleTemperature_BMS05 255 "SNA" ;
VAL_ 1860 nmOperationalMode_BMS05 2 "NM_BUSSLEEP_MODE" 1 "NM_PREPAREBUSSLEEP_MODE" 0 "NM_NETWORK_MODE" ;
VAL_ 1860 nmNetworkMode_BMS05 2 "NM_MODE_READY_SLEEP" 1 "NM_MODE_NORMAL_OPERATION" 0 "NM_MODE_REPEAT_MESSAGE" ;
VAL_ 1860 nmNetworkState_BMS05 1 "NM_STATE_REQUESTED" 0 "NM_STATE_RELEASED" ;
VAL_ 1860 ecuState_BMS05 4 "ECU_SLEEPING" 3 "ECU_GOING_TO_SLEEP" 2 "ECU_AWAKE_CAN_ACTIVE" 1 "ECU_AWAKE_CAN_INACTIVE" 0 "ECU_INIT" ;
VAL_ 1860 SPIRxTxDiag_BMS05 3 "SPIRXTX_SLAVEREQUESTPACKAGE" 2 "SPIRXTX_CRC" 1 "SPIRXTX_WRONG_PACKETINDEX" 0 "SPIRXTX_ALL_OK" ;
VAL_ 1860 minSOC_BMS05 65535 "SNA" ;
VAL_ 1860 maxSOC_BMS05 65535 "SNA" ;
VAL_ 1860 appTaskMaxCpuUsage_BMS05 255 "SNA" ;
VAL_ 1860 appTaskCpuUsage_BMS05 255 "SNA" ;
VAL_ 1860 appTask50HzCpuUsage_BMS05 255 "SNA" ;
VAL_ 1860 appTask10HzStackUsage_BMS05 255 "SNA" ;
VAL_ 1860 appTask100HzCpuUsage_BMS05 255 "SNA" ;
VAL_ 1860 appTask10HzCpuUsage_BMS05 255 "SNA" ;
VAL_ 1860 appTask1HzCpuUsage_BMS05 255 "SNA" ;
VAL_ 1860 pumpSpeedReq_BMS05 255 "SNA" ;
VAL_ 1860 regenCurrPredBrickVOffset_BMS05 255 "SNA" ;
VAL_ 1860 dischgCurrPredBrickVOffset_BMS05 255 "SNA" ;
VAL_ 1860 PCANBusOffState_BMS05 3 "SNA" 2 "CAN_BUSOFF_PHASE2" 1 "CAN_BUSOFF_PHASE1" 0 "CAN_BUSOFF_NORMAL" ;
VAL_ 1860 SCANBusOffState_BMS05 3 "SNA" 2 "CAN_BUSOFF_PHASE2" 1 "CAN_BUSOFF_PHASE1" 0 "CAN_BUSOFF_NORMAL" ;
VAL_ 1860 PTCANBusOffState_BMS05 3 "SNA" 2 "CAN_BUSOFF_PHASE2" 1 "CAN_BUSOFF_PHASE1" 0 "CAN_BUSOFF_NORMAL" ;
VAL_ 1860 customerModelVsCellType_BMS05 0 "L" 1 "P" ;
VAL_ 1860 balancingVoltageTarget_BMS05 255 "VOLTAGEBASED_BALANCING_INACTIVE" ;
VAL_ 1860 analogAddr5_BMS05 255 "SNA" ;
VAL_ 1860 analogAddr0_BMS05 255 "SNA" ;
VAL_ 1860 analogAddr4_BMS05 255 "SNA" ;
VAL_ 1860 analogAddr3_BMS05 255 "SNA" ;
VAL_ 1860 analogAddr2_BMS05 255 "SNA" ;
VAL_ 1860 analogAddr1_BMS05 255 "SNA" ;
VAL_ 1860 debugSlowMpex1_BMS05 43 "S43" 42 "S42" 41 "S41" 40 "S40" 39 "S39" 38 "S38" 37 "S37" 36 "S36" 0 "S00" 1 "S01" 2 "S02" 3 "S03" 4 "S04" 5 "S05" 6 "S06" 7 "S07" 8 "S08" 9 "S09" 10 "S10" 11 "S11" 12 "S12" 13 "S13" 14 "S14" 15 "S15" 16 "S16" 17 "S17" 18 "S18" 19 "S19" 20 "S20" 21 "S21" 22 "S22" 23 "S23" 24 "S24" 25 "S25" 26 "S26" 27 "S27" 28 "S28" 29 "S29" 30 "S30" 31 "S31" 32 "S32" 33 "S33" 34 "S34" 35 "S35" ;
VAL_ 1860 analog3V3DSupply_BMS05 255 "SNA" ;
VAL_ 1860 pressure_BMS05 255 "SNA" ;
VAL_ 1860 analog3P3VA_BMS05 255 "SNA" ;
VAL_ 1860 analog5VA_BMS05 255 "SNA" ;
VAL_ 1860 analog5VD_BMS05 255 "SNA" ;
VAL_ 1860 analog5VSensorSupply_BMS05 255 "SNA" ;
VAL_ 1860 analog6V5_BMS05 255 "SNA" ;
VAL_ 1860 isolationResistanceIntern_BMS05 65535 "SNA" ;
VAL_ 1860 isolationResistanceExtern_BMS05 65535 "SNA" ;
VAL_ 1860 linkVoltage_BMS05 65535 "SNA" ;
VAL_ 1860 eepromWriteCyclesBasics_BMS05 65535 "SNA" ;
VAL_ 1860 eepromBlockIndex_BMS05 255 "SNA" ;
VAL_ 1860 regenCurrentOpLimit_BMS05 65535 "SNA" ;
VAL_ 1860 regenCurrentErrorLimit_BMS05 65535 "SNA" ;
VAL_ 1860 lifetime_BMS05 -1 "SNA" ;
VAL_ 1860 eepromReadTime_BMS05 255 "SNA" ;
VAL_ 1860 pumpSpeedReqMaxT_BMS05 65535 "SNA" ;
VAL_ 1860 pumpSpeedReqDeltaT_BMS05 65535 "SNA" ;
VAL_ 1860 packVoltageCMB_BMS05 65535 "SNA" ;
VAL_ 1860 ctrOffTime_BMS05 65535 "SNA" ;
VAL_ 1860 sleepTime_BMS05 65535 "SNA" ;
VAL_ 1860 SPIRxTxTimeAllPckts_BMS05 255 "SNA" ;
VAL_ 1860 isolationTestState_BMS05 3 "ISOLATION_DISABLED" 2 "ISOLATION_TEST_NEG" 1 "ISOLATION_TEST_POS" 0 "ISOLATION_OFF" ;
VAL_ 1732 SPIRxTxHeaderMux3Status_BMS05 1 "SPIRXTX_MUX_MISSING" 0 "SPIRXTX_MUX_GOOD" ;
VAL_ 1732 SPIRxTxHeaderMux2Status_BMS05 1 "SPIRXTX_MUX_MISSING" 0 "SPIRXTX_MUX_GOOD" ;
VAL_ 1732 SPIRxTxHeaderMux1Status_BMS05 1 "SPIRXTX_MUX_MISSING" 0 "SPIRXTX_MUX_GOOD" ;
VAL_ 1732 SPIRxTxHeaderMux0Status_BMS05 1 "SPIRXTX_MUX_MISSING" 0 "SPIRXTX_MUX_GOOD" ;
VAL_ 1732 activeIsoState_BMS05 4 "ISOACTV_COMPLETE" 3 "ISOACTV_TIMEOUT" 2 "ISOACTV_PENDING" 1 "ISOACTV_INIT" 0 "ISOACTV_OFF" ;
VAL_ 1732 activeIsoNegLink_BMS05 65535 "SNA" ;
VAL_ 1732 activeIsoPosLink_BMS05 65535 "SNA" ;
VAL_ 1732 activeIsoPosBuffer_BMS05 65535 "SNA" ;
VAL_ 1732 activeIsoNegBuffer_BMS05 65535 "SNA" ;
VAL_ 1732 activeIsoResRaw_BMS05 65535 "SNA" ;
VAL_ 1732 activeIsoResFilter_BMS05 65535 "SNA" ;
VAL_ 1732 contactorStateAux_BMS05 4 "CTR_INVALID" 3 "CTR_STRING_OPENING" 2 "CTR_STRING_ON" 1 "CTR_STRING_PRECHARGE" 0 "CTR_STRING_OFF" ;
VAL_ 1732 batSwitchOpenReqEssMstr_BMS05 3 "INVALID" 2 "IMMEDIATE_OPEN" 1 "FAST_OPEN" 0 "DO_NOT_OPEN" ;
VAL_ 1732 packShutdownTarget_BMS05 3 "BMS_INVALID" 1 "BMS_STRING_FAULT" 0 "BMS_STANDBY" ;
VAL_ 1732 weldedState_BMS05 3 "CTR_NEG1_WELDED" 2 "CTR_POS1_WELDED" 0 "CTR_NOTWELDED" 1 "CTR_BOTH_WELDED" ;
VAL_ 1732 contactorStateRq_BMS05 4 "CTR_INVALID" 3 "CTR_STRING_OPENING" 2 "CTR_STRING_ON" 1 "CTR_STRING_PRECHARGE" 0 "CTR_STRING_OFF" ;
VAL_ 1732 strMstrStrPrechgState_BMS05 7 "NOT_A_STRING_MASTER" 6 "STRING_PRCHG_NDEF2" 5 "STRING_PRCHG_NDEF1" 4 "STRING_PRCHG_FAULT" 3 "STRING_PRCHG_ON" 2 "STRING_PRCHG_ACTV" 1 "STRING_PRCHG_INIT" 0 "STRING_PRCHG_OFF" ;
VAL_ 1732 packShutdwnTmrQual_BMS05 0 "SHUTDOWN_ACTIVE" 1 "SHUTDOWN_INACTIVE" ;
VAL_ 1732 packStateRequest_BMS05 7 "STATE_INVALID" 6 "STATE_SYSTEM_FAULT" 5 "STATE_STRING_FAULT" 4 "STATE_LIMPHOME" 3 "STATE_ACCESSORY" 2 "STATE_CHARGE" 1 "STATE_DRIVE" 0 "STATE_STANDBY" ;
VAL_ 1732 packState_BMS05 15 "STATE_INVALID" 6 "STATE_ESS_FAULT" 5 "STATE_STRING_FAULT" 4 "STATE_LIMPHOME" 3 "STATE_ACCESSORY" 2 "STATE_CHARGE" 1 "STATE_DRIVE" 0 "STATE_STANDBY" ;
VAL_ 1732 SPIRxTxTimer_BMS05 255 "SNA" ;
VAL_ 1732 moduleTMinMaxMeanQual_BMS05 1 "QUAL_ERROR" 0 "QUAL_VALID" ;
VAL_ 1732 currentQual_BMS05 1 "QUAL_ERROR" 0 "QUAL_VALID" ;
VAL_ 1732 brickVMinMaxMeanQual_BMS05 1 "QUAL_ERROR" 0 "QUAL_VALID" ;
VAL_ 1732 debugFastMpex1_BMS05 0 "F00" 1 "F01" 2 "F02" 3 "F03" 4 "F04" 5 "F05" 6 "F06" 7 "F07" 8 "F08" 9 "F09" 10 "F10" 11 "F11" 12 "F12" 13 "F13" 14 "F14" 15 "F15" ;
VAL_ 1732 itemState_BMS05 3 "ITEM_INVALID" 2 "ITEM_EMERGENCY" 1 "ITEM_OFF" 0 "ITEM_ON" ;
VAL_ 1732 posLink_BMS05 255 "SNA" ;
VAL_ 1732 posPack_BMS05 255 "SNA" ;
VAL_ 1732 prechargeState_BMS05 14 "CTR_PRCHG_WAIT_CY_MATCH" 15 "CTR_PRCHG_NEG_OPEN" 13 "CTR_PRCHG_POS_WELD_CHECK" 12 "CTR_PRCHG_PRE_COND_CHECK" 11 "CTR_PRCHG_NEG2_WELD_CHECK" 10 "CTR_PRCHG_CLOSEMID" 9 "CTR_PRCHG_CLOSEAUX" 8 "CTR_PRCHG_FAILED" 7 "CTR_PRCHG_COMPLETE" 6 "CTR_PRCHG_CLOSE_POS" 5 "CTR_PRCHG_MONITOR_VOLTAGE" 4 "CTR_PRCHG_CLOSE_NEG" 3 "CTR_PRCHG_NEG_WELD_CHECK" 2 "CTR_PRCHG_CLOSE_RELAY" 1 "CTR_PRCHG_WELD_CHECK" 0 "CTR_PRCHG_OFF" ;
VAL_ 1732 contactorState_BMS05 4 "CTR_INVALID" 3 "CTR_STRING_OPENING" 2 "CTR_STRING_ON" 1 "CTR_STRING_PRECHARGE" 0 "CTR_STRING_OFF" ;
VAL_ 1540 DEMEventMultiplexor_BMS05 319 "DEM319_HV_DISABLE_DURING_S" 318 "DEM318_HV_ENABLE_IMPLAUSIB" 317 "DEM317_STRING_SUSPECT_OPEN" 316 "DEM316_UNEXPCTD_BMS_ON_CAN" 315 "DEM315_HV_WITHSTAND_TESTS_" 314 "DEM314_OBC_PILOT_ERROR" 313 "DEM313_OBC_PILOT_HIGH" 312 "DEM312_OBC_PROXIMITY_ERROR" 311 "DEM311_CTRS_END_OF_LIFE_WA" 310 "DEM310_BMSMIA_STRNGMSTR_AL" 309 "DEM309_VOLTAGE_BRICKOV_WAR" 308 "DEM308_PRESSURE_FLT" 307 "DEM307_PRESSURE_MIA" 306 "DEM306_SW_VERSION_MISMATCH" 305 "DEM305_MODULET_OVERTEMP_WA" 304 "DEM304_PCHG_OPENCIRCUIT_IN" 303 "DEM303_MODULET_UNDERTEMP_W" 302 "DEM302_MODULET_UT" 301 "DEM301_FUSI_LOCK" 300 "DEM300_DEBUG_SM_DISABLED" 299 "DEM299_5V_SENSOR_SUPPLY_OU" 298 "DEM298_IMPL_DRIVE_REQUEST" 297 "DEM297_PCHG2_OPENCIRCUIT" 296 "DEM296_CTRSAUX_IMPLAUSIBLE" 295 "DEM295_CTRSAUX_LINKV_UNSAF" 294 "DEM294_CANRX_PT_EMERGENCY" 293 "DEM293_SBC_LDT_IMPLAUSIBLE" 292 "DEM292_NUM_EXPECTED_STRING" 291 "DEM291_NUM_EXPECTED_STRING" 290 "DEM290_CMB_ONBOARD_DEFECT" 289 "DEM289_TEMP_STATE_LATCHED" 288 "DEM288_CURR_STATE_LATCHED" 1 "DEM001_POWERUP" 2 "DEM002_VOLTAGE_BRICK_OV" 3 "DEM003_VOLTAGE_BRICK_UV" 4 "DEM004_VOLTAGE_BRICK_SNA" 5 "DEM005_VOLTAGE_BRICK_IMBAL" 6 "DEM006_VOLTAGE_CAPCY_IMBAL" 7 "DEM007_MODULET_HIGH_DELTA" 8 "DEM008_VOLTAGE_PACK_UV" 9 "DEM009_VOLTAGE_PACK_OV" 10 "DEM010_VOLTAGE_PACK_PLAUSI" 11 "DEM011_VOLTAGE_PCKLINK_MIS" 12 "DEM012_VOLTAGE_BMS_SUPPLY" 13 "DEM013_ADC_ERROR" 14 "DEM014_MODULET_OT" 15 "DEM015_MODULET_SNA" 16 "DEM016_MODULET_LIMPHOME" 17 "DEM017_COOLING_SYS_LHOME" 18 "DEM018_HVIL_LIMPHOME" 19 "DEM019_HVIL_ESS_INHIBIT" 20 "DEM020_MODULET_CHANGE" 21 "DEM021_LG_MAVD_FAULT" 22 "DEM022_LG_RDV_FAULT" 23 "DEM023_BMS_ONBOARDT_SNA" 24 "DEM024_BMS_ONBOARDRH_OH" 25 "DEM025_BMS_ONBOARDRH_SNA" 26 "DEM026_CURRENT_OVERCHARGE" 27 "DEM027_CURRENT_OVERDISCHGE" 28 "DEM028_CURRENT_INVALID" 29 "DEM029_CURRENT_SHORTCIRCT" 30 "DEM030_CRASH_CAN_LATCH" 31 "DEM031_EEPROM_FAIL" 32 "DEM032_PCHG_PACKS_CONNECT" 33 "DEM033_PCHG_ILLEGAL_PRCHG" 34 "DEM034_PCHG_RELAY_FAIL" 35 "DEM035_PCHG_NEG_WELD" 36 "DEM036_PCHG_NEG_PULLIN" 37 "DEM037_PCHG_SHORTCIRCUIT" 38 "DEM038_PCHG_OPENCIRCUIT" 39 "DEM039_PCHG_TIMEOUT" 40 "DEM040_PCHG_FAILED" 41 "DEM041_HVIL_SHUTDOWN" 42 "DEM042_PCHG_POS_WELD" 43 "DEM043_HV_LOCK_TRANSPORT" 44 "DEM044_CTRS_END_OF_LIFE" 45 "DEM045_CTRS_CTRPWRV_HI" 46 "DEM046_CTRS_COILCURR_LOW" 47 "DEM047_CTRS_COILCURR_HIGH" 48 "DEM048_CTRS_CTRPWRV_LOW" 49 "DEM049_CHGE_ILLEGAL_DISCHG" 50 "DEM050_STARTUP_CONDITIONS" 51 "DEM051_VOLTAGE_BMS_SUPPLYH" 52 "DEM052_SAFETYSPI_FAIL" 53 "DEM053_WATCHDOG_ERRORPIN" 54 "DEM054_SAFESTATE_TRIGGERED" 55 "DEM055_DEBUG_CMND_ACTIVE" 56 "DEM056_CRASH_CAN" 57 "DEM057_ISO_EXT_STRAT_4" 58 "DEM058_ISO_EXT_RES_ERR" 59 "DEM059_ISO_EXT_RES_WARN" 60 "DEM060_ISO_INT_RES_ERR" 61 "DEM061_ISO_INT_RES_WARN" 62 "DEM062_EMERGENCY_OPERATION" 63 "DEM063_ENDOFDRIVE" 64 "DEM064_STRINGV_IMBALANCE" 65 "DEM065_STRING_FAULT" 66 "DEM066_ESS_FAULT" 67 "DEM067_ISO_EXT_STRAT_3" 68 "DEM068_MODULE_COUNT_INVALI" 69 "DEM069_PT_MIA" 70 "DEM070_BMSMIA_STRNGMSTR_01" 71 "DEM071_BMSMIA_STRNGMSTR_05" 72 "DEM072_BMSMIA_STRNGMSTR_09" 73 "DEM073_BMSMIA_STRNGMSTR_13" 74 "DEM074_BMSMIA_STRNGMSTR_17" 75 "DEM075_BMSMIA_STRNGMSTR_21" 76 "DEM076_BMSMIA_STRNGMSTR_25" 77 "DEM077_BMSMIA_STRNGMSTR_29" 78 "DEM078_BMSMIA_STRNGMSTR_33" 79 "DEM079_BMSMIA_STRNGMSTR_37" 80 "DEM080_BMSMIA_STRNGMSTR_41" 81 "DEM081_BMSMIA_STRNGMSTR_45" 82 "DEM082_BMSMIA_STRNGMSTR_49" 83 "DEM083_BMSMIA_STRNGMSTR_53" 84 "DEM084_BMSMIA_STRNGMSTR_57" 85 "DEM085_BMSMIA_STRNGMSTR_61" 86 "DEM086_ESSCURRENT_SHORT" 87 "DEM087_PT_MIA_SHUTDOWN" 88 "DEM088_OUTLET_NTC_HI" 89 "DEM089_OUTLET_NTC_LO" 90 "DEM090_BMSMIA_ESSMASTER" 91 "DEM091_PCHG_RES_OVERHEAT" 92 "DEM092_BMSMIA_STRNGSLAVE_0" 93 "DEM093_BMSMIA_STRNGSLAVE_1" 94 "DEM094_BMSMIA_STRNGSLAVE_2" 95 "DEM095_BMSMIA_STRNGSLAVE_3" 96 "DEM096_SC_STATE_SELFTEST" 97 "DEM097_SC_STATE_TEMP" 98 "DEM098_SC_STATE_VOLTAGE" 99 "DEM099_SC_STATE_HVIL" 100 "DEM100_SC_STATE_CONTACTORS" 101 "DEM101_SC_STATE_CURRENT" 102 "DEM102_SC_STATE_CANRX" 103 "DEM103_SC_STATE_CRASH" 104 "DEM104_SC_STATE_CCTRL" 105 "DEM105_SC_STATE_CANTX" 106 "DEM106_SC_STATE_THERMALEVT" 107 "DEM107_SC_STATE_COOLANT" 108 "DEM108_SC_SELFTEST_SFTY_UC" 109 "DEM109_SC_TEMP_HIGH" 110 "DEM110_SC_TEMP_NTC_OPEN" 111 "DEM111_SC_TEMP_NTC_SHORT" 112 "DEM112_CMB_DISCONNECTED" 113 "DEM113_CMB_DEFECT" 114 "DEM114_CMB_COMMERROR" 115 "DEM115_SC_CURR_HALL_PWR_LO" 116 "DEM116_SC_CURR_HALL_VHIGH" 117 "DEM117_SC_CURR_HALL_ADC" 118 "DEM118_SC_CURR_HALL_VLOW" 119 "DEM119_SC_CURR_ISENSE_PWR" 120 "DEM120_SC_CURR_ISENSE1_MIA" 121 "DEM121_SC_CURR_ISENSE2_MIA" 122 "DEM122_SC_CURR_ISENSE3_MIA" 123 "DEM123_SC_CURR_ISENSE4_MIA" 124 "DEM124_SC_CURR_ISENSE5_MIA" 125 "DEM125_SC_CURR_ISENSE1_FLT" 126 "DEM126_SC_CURR_ISENSE2_FLT" 127 "DEM127_SC_CURR_ISENSE3_FLT" 128 "DEM128_SC_CURR_ISENSE4_FLT" 129 "DEM129_SC_CURR_ISENSE5_FLT" 130 "DEM130_SC_CURR_OFFSET" 131 "DEM131_SC_CURR_PLAUSI" 132 "DEM132_SC_CURR_CHARGE_HIGH" 133 "DEM133_SC_CURR_DSCHAR_HIGH" 134 "DEM134_SC_V_CMB_SUMOFCELL" 135 "DEM135_SC_V_SENSE_OPENWIRE" 136 "DEM136_SC_V_CMB_DRV_FROZEN" 137 "DEM137_SC_V_PACK_PLAUSI" 138 "DEM138_SC_HVIL_HW_FLT" 139 "DEM139_SC_HVIL_OPEN" 140 "DEM140_SC_HVIL_TO_SUP" 141 "DEM141_SC_HVIL_TO_CHAS" 142 "DEM142_SC_HVIL_R_HIGH" 143 "DEM143_SC_HVIL_SHORT" 144 "DEM144_SC_CN_ISO_FAIL" 145 "DEM145_HVIL_SYS" 146 "DEM146_SC_CN_POS1_WELDED" 147 "DEM147_SC_CN_NEG1_WELDED" 148 "DEM148_SC_CN_POS2_WELDED" 149 "DEM149_SC_CN_NEG2_WELDED" 150 "DEM150_SC_CN_POS3_WELDED" 151 "DEM151_SC_CN_NEG3_WELDED" 152 "DEM152_SC_CN_HIGH_CY" 153 "DEM153_SC_CN_ISOANDPOTWELD" 154 "DEM154_SC_TEMP_PLAUSI" 155 "DEM155_SC_CURR_HALL_PWR_HI" 156 "DEM156_SC_PYRO_TRIGGERED" 157 "DEM157_SC_PYRO_OPEN" 158 "DEM158_AUX_CTRS_END_OF_LIF" 159 "DEM159_SC_CANRX_PT_MIA" 160 "DEM160_SC_CANRX_PT_CRCALIV" 161 "DEM161_SC_CANRX_LIN_SHUTDN" 162 "DEM162_SC_CANRX_LIN_MIA" 163 "DEM163_SC_CRASH1" 164 "DEM164_SC_CRASH2" 165 "DEM165_SC_CRASHCAN" 166 "DEM166_SC_CCTRL_SELFTEST" 167 "DEM167_SC_CCTRL_DRIVER_FAU" 168 "DEM168_SC_CCTRL_HISIDESTCL" 169 "DEM169_SC_CCTRL_HISIDESTOP" 170 "DEM170_SC_CCTRL_LOSIDESTCL" 171 "DEM171_SC_CCTRL_HVCNDITION" 172 "DEM172_SC_CCTRL_POS1_OPN" 173 "DEM173_SC_CCTRL_POS2_OPN" 174 "DEM174_SC_CCTRL_POS3_OPN" 175 "DEM175_SC_CCTRL_NEG1_OPN" 176 "DEM176_SC_CCTRL_NEG2_OPN" 177 "DEM177_SC_CCTRL_PRE2_OPN" 178 "DEM178_SC_CCTRL_PRE1_OPN" 179 "DEM179_SC_CCTRL_LOSIDESTOP" 180 "DEM180_SC_CCTRL_UNEXPECTED" 181 "DEM181_SC_V_OUT_OF_RANGE" 182 "DEM182_SC_V_LATCHED_UVOV" 183 "DEM183_ISO_EXT_STRAT_2" 184 "DEM184_SC_CANTX_CTRS" 185 "DEM185_SC_CANTX_HVIL" 186 "DEM186_SC_CANTX_ISOL" 187 "DEM187_SC_SBC_WATCHDOG" 188 "DEM188_SC_SBC_FAULT" 189 "DEM189_SC_WATCHDOG" 190 "DEM190_SC_SELFTEST_RAM" 191 "DEM191_SC_SELFTEST_FLASH" 192 "DEM192_CMB_ONBOARDRH_OH" 193 "DEM193_CMB_ONBOARDRH_SNA" 194 "DEM194_CMB_ONBOARDT_OT" 195 "DEM195_CMB_ONBOARDT_CHANGE" 196 "DEM196_PRESSURE_CHANGE" 197 "DEM197_PRESSURE_OVER" 198 "DEM198_PRESSURE_UNDER" 199 "DEM199_PRESSURE_INVALID" 200 "DEM200_THERMAL_EVENT" 201 "DEM201_CMB_ONBOARDT_SNA" 202 "DEM202_REPLACE_DESICCANT" 203 "DEM203_COOLANT_FLOOD_FAULT" 204 "DEM204_LOW_BRICKCAPACITY" 205 "DEM205_BMS_ONBOARDT_OT" 206 "DEM206_HUMIDITY_CHANGE" 207 "DEM207_ISENSE_SUPPLY_CURR" 208 "DEM208_SOC_LOW" 209 "DEM209_SOC_TOOLOW" 210 "DEM210_SOC_TOOHIGH" 211 "DEM211_BALANCING_REQUIRED" 212 "DEM212_DEEP_DISCHARGE" 213 "DEM213_CAN1_BUS_OFF" 214 "DEM214_CAN2_BUS_OFF" 215 "DEM215_CAN3_BUS_OFF" 216 "DEM216_OUTLET_NTC_RATNAL" 217 "DEM217_FUSE_PACK" 218 "DEM218_FUSE_B_OPEN" 219 "DEM219_FUSE_C_OPEN" 220 "DEM220_FUSE_D_OPEN" 221 "DEM221_FUSE_E_OPEN" 222 "DEM222_PUMP_DRY_RUN" 223 "DEM223_PUMP_PERFORMANCE" 224 "DEM224_PUMP_LIN_FAILURE" 225 "DEM225_PUMP_SUPPLY_VOLTAGE" 226 "DEM226_PUMP_RECOVERY_FAIL" 227 "DEM227_CTR_POS_OPENED" 228 "DEM228_CTR_NEG_OPENED" 229 "DEM229_STRSET_SLAVE1_FAULT" 230 "DEM230_STRSET_SLAVE2_FAULT" 231 "DEM231_CTRSAUX_CLFAIL_HVON" 232 "DEM232_CTRSAUX_CLFAIL_VDIF" 233 "DEM233_CTRSAUX_POS1_OPENED" 234 "DEM234_CTRSAUX_NEG1_OPENED" 235 "DEM235_CTRSAUX_POS1_WELDED" 236 "DEM236_CTRSAUX_NEG1_WELDED" 237 "DEM237_CTRSAUX_POS1_PULLIN" 238 "DEM238_CTRSAUX_NEG1_PULLIN" 239 "DEM239_INLET_NTC_RATNAL" 240 "DEM240_INLET_NTC_HI" 241 "DEM241_INLET_NTC_LO" 242 "DEM242_VOLTAGE_LINK2_RATNA" 243 "DEM243_VOLTAGE_LINK2_HI" 244 "DEM244_VOLTAGE_LINK2_LO" 245 "DEM245_CMB_ONBOARD_IMPOSSI" 246 "DEM246_VOLTAGE_LINK1_HI" 247 "DEM247_VOLTAGE_LINK1_LO" 248 "DEM248_NTC_SUPPLY_LO" 249 "DEM249_NTC_SUPPLY_HI" 250 "DEM250_VOLTAGE_LINK3_RATNA" 251 "DEM251_VOLTAGE_LINK3_HI" 252 "DEM252_VOLTAGE_LINK3_LO" 253 "DEM253_BALANCING_STUCK" 254 "DEM254_ARM_EXCEPTION" 255 "DEM255_ERROR_HOOKS" 256 "DEM256_XCP_CAL_CHANGE" 257 "DEM257_XCP_CAL_PERM_CHANGE" 258 "DEM258_TASK_TIME_OVERFLOW" 259 "DEM259_ISO_CIRCUIT" 260 "DEM260_COOLANT_MOIST_FAULT" 261 "DEM261_COOLANT_FLOOD_WARN" 262 "DEM262_COOLANT_MOIST_WARN" 263 "DEM263_MODULET_IMPLAUSIBLE" 264 "DEM264_REQUEST_ON_WITH_HV_" 265 "DEM265_CSERS_PCODE" 266 "DEM266_PRELIM_CNTR_CL_FAIL" 267 "DEM267_FLUIDLVL_LOW" 268 "DEM268_FLUIDLVL_FAILURE" 269 "DEM269_SC_COOLANT_CONTAM" 270 "DEM270_SC_COOLANT_MIA" 271 "DEM271_PRESSURE_VHI" 272 "DEM272_PRESSURE_VLO" 273 "DEM273_SC_COOLANT_FAIL" 274 "DEM274_CTRSAUX_POS2_OPENED" 275 "DEM275_CTRSAUX_POS3_OPENED" 276 "DEM276_CTRSAUX_POS2_WELDED" 277 "DEM277_CTRSAUX_POS3_WELDED" 278 "DEM278_CTRSAUX_POS2_PULLIN" 279 "DEM279_CTRSAUX_POS3_PULLIN" 280 "DEM280_CMB_HUMIDITY_TEMP_C" 281 "DEM281_THERMAL_EVENT_CMB_R" 282 "DEM282_CUS_BRICKOV" 283 "DEM283_CUS_BRICKUV" 284 "DEM284_CUS_OVERCHRG" 285 "DEM285_CUS_OVERDCHRG" 286 "DEM286_CUS_CURRENT_CHG" 287 "DEM287_CUS_CURRENT_DCHG" ;
VAL_ 1028 DEM001_POWERUP_BMS05 3 "DEM_INVALID" 2 "DEM_FAILED" 1 "DEM_PASSED" 0 "DEM_NOTTESTED" ;
VAL_ 1028 DEM002_VOLTAGE_BRICK_OV_BMS05 3 "DEM_INVALID" 2 "DEM_FAILED" 1 "DEM_PASSED" 0 "DEM_NOTTESTED" ;
VAL_ 1028 DEM003_VOLTAGE_BRICK_UV_BMS05 3 "DEM_INVALID" 2 "DEM_FAILED" 1 "DEM_PASSED" 0 "DEM_NOTTESTED" ;
VAL_ 1028 DEM004_VOLTAGE_BRICK_SNA_BMS05 3 "DEM_INVALID" 2 "DEM_FAILED" 1 "DEM_PASSED" 0 "DEM_NOTTESTED" ;
VAL_ 1028 DEM005_VOLTAGE_BRICK_IMBAL_BMS05 3 "DEM_INVALID" 2 "DEM_FAILED" 1 "DEM_PASSED" 0 "DEM_NOTTESTED" ;
VAL_ 1028 DEM006_VOLTAGE_CAPCY_IMBAL_BMS05 3 "DEM_INVALID" 2 "DEM_FAILED" 1 "DEM_PASSED" 0 "DEM_NOTTESTED" ;
VAL_ 1028 DEM007_MODULET_HIGH_DELTA_BMS05 3 "DEM_INVALID" 2 "DEM_FAILED" 1 "DEM_PASSED" 0 "DEM_NOTTESTED" ;
VAL_ 1028 DEM008_VOLTAGE_PACK_UV_BMS05 3 "DEM_INVALID" 2 "DEM_FAILED" 1 "DEM_PASSED" 0 "DEM_NOTTESTED" ;
VAL_ 1028 DEM009_VOLTAGE_PACK_OV_BMS05 3 "DEM_INVALID" 2 "DEM_FAILED" 1 "DEM_PASSED" 0 "DEM_NOTTESTED" ;
VAL_ 1028 DEM010_VOLTAGE_PACK_PLAUSI_BMS05 3 "DEM_INVALID" 2 "DEM_FAILED" 1 "DEM_PASSED" 0 "DEM_NOTTESTED" ;
VAL_ 1028 DEM011_VOLTAGE_PCKLINK_MIS_BMS05 3 "DEM_INVALID" 2 "DEM_FAILED" 1 "DEM_PASSED" 0 "DEM_NOTTESTED" ;
VAL_ 1028 DEM012_VOLTAGE_BMS_SUPPLY_BMS05 3 "DEM_INVALID" 2 "DEM_FAILED" 1 "DEM_PASSED" 0 "DEM_NOTTESTED" ;
VAL_ 1028 DEM013_ADC_ERROR_BMS05 3 "DEM_INVALID" 2 "DEM_FAILED" 1 "DEM_PASSED" 0 "DEM_NOTTESTED" ;
VAL_ 1028 DEM014_MODULET_OT_BMS05 3 "DEM_INVALID" 2 "DEM_FAILED" 1 "DEM_PASSED" 0 "DEM_NOTTESTED" ;
VAL_ 1028 DEM015_MODULET_SNA_BMS05 3 "DEM_INVALID" 2 "DEM_FAILED" 1 "DEM_PASSED" 0 "DEM_NOTTESTED" ;
VAL_ 1028 DEM016_MODULET_LIMPHOME_BMS05 3 "DEM_INVALID" 2 "DEM_FAILED" 1 "DEM_PASSED" 0 "DEM_NOTTESTED" ;
VAL_ 1028 DEM017_COOLING_SYS_LHOME_BMS05 3 "DEM_INVALID" 2 "DEM_FAILED" 1 "DEM_PASSED" 0 "DEM_NOTTESTED" ;
VAL_ 1028 DEM018_HVIL_LIMPHOME_BMS05 3 "DEM_INVALID" 2 "DEM_FAILED" 1 "DEM_PASSED" 0 "DEM_NOTTESTED" ;
VAL_ 1028 DEM019_HVIL_ESS_INHIBIT_BMS05 3 "DEM_INVALID" 2 "DEM_FAILED" 1 "DEM_PASSED" 0 "DEM_NOTTESTED" ;
VAL_ 1028 DEM020_MODULET_CHANGE_BMS05 3 "DEM_INVALID" 2 "DEM_FAILED" 1 "DEM_PASSED" 0 "DEM_NOTTESTED" ;
VAL_ 1028 DEM021_LG_MAVD_FAULT_BMS05 3 "DEM_INVALID" 2 "DEM_FAILED" 1 "DEM_PASSED" 0 "DEM_NOTTESTED" ;
VAL_ 1028 DEM022_LG_RDV_FAULT_BMS05 3 "DEM_INVALID" 2 "DEM_FAILED" 1 "DEM_PASSED" 0 "DEM_NOTTESTED" ;
VAL_ 1028 DEM023_BMS_ONBOARDT_SNA_BMS05 3 "DEM_INVALID" 2 "DEM_FAILED" 1 "DEM_PASSED" 0 "DEM_NOTTESTED" ;
VAL_ 1028 DEM024_BMS_ONBOARDRH_OH_BMS05 3 "DEM_INVALID" 2 "DEM_FAILED" 1 "DEM_PASSED" 0 "DEM_NOTTESTED" ;
VAL_ 1028 DEM025_BMS_ONBOARDRH_SNA_BMS05 3 "DEM_INVALID" 2 "DEM_FAILED" 1 "DEM_PASSED" 0 "DEM_NOTTESTED" ;
VAL_ 1028 DEM026_CURRENT_OVERCHARGE_BMS05 3 "DEM_INVALID" 2 "DEM_FAILED" 1 "DEM_PASSED" 0 "DEM_NOTTESTED" ;
VAL_ 1028 DEM027_CURRENT_OVERDISCHGE_BMS05 3 "DEM_INVALID" 2 "DEM_FAILED" 1 "DEM_PASSED" 0 "DEM_NOTTESTED" ;
VAL_ 1028 DEM028_CURRENT_INVALID_BMS05 3 "DEM_INVALID" 2 "DEM_FAILED" 1 "DEM_PASSED" 0 "DEM_NOTTESTED" ;
VAL_ 1028 DEM029_CURRENT_SHORTCIRCT_BMS05 3 "DEM_INVALID" 2 "DEM_FAILED" 1 "DEM_PASSED" 0 "DEM_NOTTESTED" ;
VAL_ 1028 DEM030_CRASH_CAN_LATCH_BMS05 3 "DEM_INVALID" 2 "DEM_FAILED" 1 "DEM_PASSED" 0 "DEM_NOTTESTED" ;
VAL_ 1028 DEM031_EEPROM_FAIL_BMS05 3 "DEM_INVALID" 2 "DEM_FAILED" 1 "DEM_PASSED" 0 "DEM_NOTTESTED" ;
VAL_ 1092 DEM032_PCHG_PACKS_CONNECT_BMS05 3 "DEM_INVALID" 2 "DEM_FAILED" 1 "DEM_PASSED" 0 "DEM_NOTTESTED" ;
VAL_ 1092 DEM033_PCHG_ILLEGAL_PRCHG_BMS05 3 "DEM_INVALID" 2 "DEM_FAILED" 1 "DEM_PASSED" 0 "DEM_NOTTESTED" ;
VAL_ 1092 DEM034_PCHG_RELAY_FAIL_BMS05 3 "DEM_INVALID" 2 "DEM_FAILED" 1 "DEM_PASSED" 0 "DEM_NOTTESTED" ;
VAL_ 1092 DEM035_PCHG_NEG_WELD_BMS05 3 "DEM_INVALID" 2 "DEM_FAILED" 1 "DEM_PASSED" 0 "DEM_NOTTESTED" ;
VAL_ 1092 DEM036_PCHG_NEG_PULLIN_BMS05 3 "DEM_INVALID" 2 "DEM_FAILED" 1 "DEM_PASSED" 0 "DEM_NOTTESTED" ;
VAL_ 1092 DEM037_PCHG_SHORTCIRCUIT_BMS05 3 "DEM_INVALID" 2 "DEM_FAILED" 1 "DEM_PASSED" 0 "DEM_NOTTESTED" ;
VAL_ 1092 DEM038_PCHG_OPENCIRCUIT_BMS05 3 "DEM_INVALID" 2 "DEM_FAILED" 1 "DEM_PASSED" 0 "DEM_NOTTESTED" ;
VAL_ 1092 DEM039_PCHG_TIMEOUT_BMS05 3 "DEM_INVALID" 2 "DEM_FAILED" 1 "DEM_PASSED" 0 "DEM_NOTTESTED" ;
VAL_ 1092 DEM040_PCHG_FAILED_BMS05 3 "DEM_INVALID" 2 "DEM_FAILED" 1 "DEM_PASSED" 0 "DEM_NOTTESTED" ;
VAL_ 1092 DEM041_HVIL_SHUTDOWN_BMS05 3 "DEM_INVALID" 2 "DEM_FAILED" 1 "DEM_PASSED" 0 "DEM_NOTTESTED" ;
VAL_ 1092 DEM042_PCHG_POS_WELD_BMS05 3 "DEM_INVALID" 2 "DEM_FAILED" 1 "DEM_PASSED" 0 "DEM_NOTTESTED" ;
VAL_ 1092 DEM043_HV_LOCK_TRANSPORT_BMS05 3 "DEM_INVALID" 2 "DEM_FAILED" 1 "DEM_PASSED" 0 "DEM_NOTTESTED" ;
VAL_ 1092 DEM044_CTRS_END_OF_LIFE_BMS05 3 "DEM_INVALID" 2 "DEM_FAILED" 1 "DEM_PASSED" 0 "DEM_NOTTESTED" ;
VAL_ 1092 DEM045_CTRS_CTRPWRV_HI_BMS05 3 "DEM_INVALID" 2 "DEM_FAILED" 1 "DEM_PASSED" 0 "DEM_NOTTESTED" ;
VAL_ 1092 DEM046_CTRS_COILCURR_LOW_BMS05 3 "DEM_INVALID" 2 "DEM_FAILED" 1 "DEM_PASSED" 0 "DEM_NOTTESTED" ;
VAL_ 1092 DEM047_CTRS_COILCURR_HIGH_BMS05 3 "DEM_INVALID" 2 "DEM_FAILED" 1 "DEM_PASSED" 0 "DEM_NOTTESTED" ;
VAL_ 1092 DEM048_CTRS_CTRPWRV_LOW_BMS05 3 "DEM_INVALID" 2 "DEM_FAILED" 1 "DEM_PASSED" 0 "DEM_NOTTESTED" ;
VAL_ 1092 DEM049_CHGE_ILLEGAL_DISCHG_BMS05 3 "DEM_INVALID" 2 "DEM_FAILED" 1 "DEM_PASSED" 0 "DEM_NOTTESTED" ;
VAL_ 1092 DEM050_STARTUP_CONDITIONS_BMS05 3 "DEM_INVALID" 2 "DEM_FAILED" 1 "DEM_PASSED" 0 "DEM_NOTTESTED" ;
VAL_ 1092 DEM051_VOLTAGE_BMS_SUPPLYH_BMS05 3 "DEM_INVALID" 2 "DEM_FAILED" 1 "DEM_PASSED" 0 "DEM_NOTTESTED" ;
VAL_ 1092 DEM052_SAFETYSPI_FAIL_BMS05 3 "DEM_INVALID" 2 "DEM_FAILED" 1 "DEM_PASSED" 0 "DEM_NOTTESTED" ;
VAL_ 1092 DEM053_WATCHDOG_ERRORPIN_BMS05 3 "DEM_INVALID" 2 "DEM_FAILED" 1 "DEM_PASSED" 0 "DEM_NOTTESTED" ;
VAL_ 1092 DEM054_SAFESTATE_TRIGGERED_BMS05 3 "DEM_INVALID" 2 "DEM_FAILED" 1 "DEM_PASSED" 0 "DEM_NOTTESTED" ;
VAL_ 1092 DEM055_DEBUG_CMND_ACTIVE_BMS05 3 "DEM_INVALID" 2 "DEM_FAILED" 1 "DEM_PASSED" 0 "DEM_NOTTESTED" ;
VAL_ 1092 DEM056_CRASH_CAN_BMS05 3 "DEM_INVALID" 2 "DEM_FAILED" 1 "DEM_PASSED" 0 "DEM_NOTTESTED" ;
VAL_ 1092 DEM057_ISO_EXT_STRAT_4_BMS05 3 "DEM_INVALID" 2 "DEM_FAILED" 1 "DEM_PASSED" 0 "DEM_NOTTESTED" ;
VAL_ 1092 DEM058_ISO_EXT_RES_ERR_BMS05 3 "DEM_INVALID" 2 "DEM_FAILED" 1 "DEM_PASSED" 0 "DEM_NOTTESTED" ;
VAL_ 1092 DEM059_ISO_EXT_RES_WARN_BMS05 3 "DEM_INVALID" 2 "DEM_FAILED" 1 "DEM_PASSED" 0 "DEM_NOTTESTED" ;
VAL_ 1092 DEM060_ISO_INT_RES_ERR_BMS05 3 "DEM_INVALID" 2 "DEM_FAILED" 1 "DEM_PASSED" 0 "DEM_NOTTESTED" ;
VAL_ 1092 DEM061_ISO_INT_RES_WARN_BMS05 3 "DEM_INVALID" 2 "DEM_FAILED" 1 "DEM_PASSED" 0 "DEM_NOTTESTED" ;
VAL_ 1092 DEM062_EMERGENCY_OPERATION_BMS05 3 "DEM_INVALID" 2 "DEM_FAILED" 1 "DEM_PASSED" 0 "DEM_NOTTESTED" ;
VAL_ 1092 DEM063_ENDOFDRIVE_BMS05 3 "DEM_INVALID" 2 "DEM_FAILED" 1 "DEM_PASSED" 0 "DEM_NOTTESTED" ;
VAL_ 1156 DEM064_STRINGV_IMBALANCE_BMS05 3 "DEM_INVALID" 2 "DEM_FAILED" 1 "DEM_PASSED" 0 "DEM_NOTTESTED" ;
VAL_ 1156 DEM065_STRING_FAULT_BMS05 3 "DEM_INVALID" 2 "DEM_FAILED" 1 "DEM_PASSED" 0 "DEM_NOTTESTED" ;
VAL_ 1156 DEM066_ESS_FAULT_BMS05 3 "DEM_INVALID" 2 "DEM_FAILED" 1 "DEM_PASSED" 0 "DEM_NOTTESTED" ;
VAL_ 1156 DEM067_ISO_EXT_STRAT_3_BMS05 3 "DEM_INVALID" 2 "DEM_FAILED" 1 "DEM_PASSED" 0 "DEM_NOTTESTED" ;
VAL_ 1156 DEM068_MODULE_COUNT_INVALI_BMS05 3 "DEM_INVALID" 2 "DEM_FAILED" 1 "DEM_PASSED" 0 "DEM_NOTTESTED" ;
VAL_ 1156 DEM069_PT_MIA_BMS05 3 "DEM_INVALID" 2 "DEM_FAILED" 1 "DEM_PASSED" 0 "DEM_NOTTESTED" ;
VAL_ 1156 DEM070_BMSMIA_STRNGMSTR_01_BMS05 3 "DEM_INVALID" 2 "DEM_FAILED" 1 "DEM_PASSED" 0 "DEM_NOTTESTED" ;
VAL_ 1156 DEM071_BMSMIA_STRNGMSTR_05_BMS05 3 "DEM_INVALID" 2 "DEM_FAILED" 1 "DEM_PASSED" 0 "DEM_NOTTESTED" ;
VAL_ 1156 DEM072_BMSMIA_STRNGMSTR_09_BMS05 3 "DEM_INVALID" 2 "DEM_FAILED" 1 "DEM_PASSED" 0 "DEM_NOTTESTED" ;
VAL_ 1156 DEM073_BMSMIA_STRNGMSTR_13_BMS05 3 "DEM_INVALID" 2 "DEM_FAILED" 1 "DEM_PASSED" 0 "DEM_NOTTESTED" ;
VAL_ 1156 DEM074_BMSMIA_STRNGMSTR_17_BMS05 3 "DEM_INVALID" 2 "DEM_FAILED" 1 "DEM_PASSED" 0 "DEM_NOTTESTED" ;
VAL_ 1156 DEM075_BMSMIA_STRNGMSTR_21_BMS05 3 "DEM_INVALID" 2 "DEM_FAILED" 1 "DEM_PASSED" 0 "DEM_NOTTESTED" ;
VAL_ 1156 DEM076_BMSMIA_STRNGMSTR_25_BMS05 3 "DEM_INVALID" 2 "DEM_FAILED" 1 "DEM_PASSED" 0 "DEM_NOTTESTED" ;
VAL_ 1156 DEM077_BMSMIA_STRNGMSTR_29_BMS05 3 "DEM_INVALID" 2 "DEM_FAILED" 1 "DEM_PASSED" 0 "DEM_NOTTESTED" ;
VAL_ 1156 DEM078_BMSMIA_STRNGMSTR_33_BMS05 3 "DEM_INVALID" 2 "DEM_FAILED" 1 "DEM_PASSED" 0 "DEM_NOTTESTED" ;
VAL_ 1156 DEM079_BMSMIA_STRNGMSTR_37_BMS05 3 "DEM_INVALID" 2 "DEM_FAILED" 1 "DEM_PASSED" 0 "DEM_NOTTESTED" ;
VAL_ 1156 DEM080_BMSMIA_STRNGMSTR_41_BMS05 3 "DEM_INVALID" 2 "DEM_FAILED" 1 "DEM_PASSED" 0 "DEM_NOTTESTED" ;
VAL_ 1156 DEM081_BMSMIA_STRNGMSTR_45_BMS05 3 "DEM_INVALID" 2 "DEM_FAILED" 1 "DEM_PASSED" 0 "DEM_NOTTESTED" ;
VAL_ 1156 DEM082_BMSMIA_STRNGMSTR_49_BMS05 3 "DEM_INVALID" 2 "DEM_FAILED" 1 "DEM_PASSED" 0 "DEM_NOTTESTED" ;
VAL_ 1156 DEM083_BMSMIA_STRNGMSTR_53_BMS05 3 "DEM_INVALID" 2 "DEM_FAILED" 1 "DEM_PASSED" 0 "DEM_NOTTESTED" ;
VAL_ 1156 DEM084_BMSMIA_STRNGMSTR_57_BMS05 3 "DEM_INVALID" 2 "DEM_FAILED" 1 "DEM_PASSED" 0 "DEM_NOTTESTED" ;
VAL_ 1156 DEM085_BMSMIA_STRNGMSTR_61_BMS05 3 "DEM_INVALID" 2 "DEM_FAILED" 1 "DEM_PASSED" 0 "DEM_NOTTESTED" ;
VAL_ 1156 DEM086_ESSCURRENT_SHORT_BMS05 3 "DEM_INVALID" 2 "DEM_FAILED" 1 "DEM_PASSED" 0 "DEM_NOTTESTED" ;
VAL_ 1156 DEM087_PT_MIA_SHUTDOWN_BMS05 3 "DEM_INVALID" 2 "DEM_FAILED" 1 "DEM_PASSED" 0 "DEM_NOTTESTED" ;
VAL_ 1156 DEM088_OUTLET_NTC_HI_BMS05 3 "DEM_INVALID" 2 "DEM_FAILED" 1 "DEM_PASSED" 0 "DEM_NOTTESTED" ;
VAL_ 1156 DEM089_OUTLET_NTC_LO_BMS05 3 "DEM_INVALID" 2 "DEM_FAILED" 1 "DEM_PASSED" 0 "DEM_NOTTESTED" ;
VAL_ 1156 DEM090_BMSMIA_ESSMASTER_BMS05 3 "DEM_INVALID" 2 "DEM_FAILED" 1 "DEM_PASSED" 0 "DEM_NOTTESTED" ;
VAL_ 1156 DEM091_PCHG_RES_OVERHEAT_BMS05 3 "DEM_INVALID" 2 "DEM_FAILED" 1 "DEM_PASSED" 0 "DEM_NOTTESTED" ;
VAL_ 1156 DEM092_BMSMIA_STRNGSLAVE_0_BMS05 3 "DEM_INVALID" 2 "DEM_FAILED" 1 "DEM_PASSED" 0 "DEM_NOTTESTED" ;
VAL_ 1156 DEM093_BMSMIA_STRNGSLAVE_1_BMS05 3 "DEM_INVALID" 2 "DEM_FAILED" 1 "DEM_PASSED" 0 "DEM_NOTTESTED" ;
VAL_ 1156 DEM094_BMSMIA_STRNGSLAVE_2_BMS05 3 "DEM_INVALID" 2 "DEM_FAILED" 1 "DEM_PASSED" 0 "DEM_NOTTESTED" ;
VAL_ 1156 DEM095_BMSMIA_STRNGSLAVE_3_BMS05 3 "DEM_INVALID" 2 "DEM_FAILED" 1 "DEM_PASSED" 0 "DEM_NOTTESTED" ;
VAL_ 1220 DEM096_SC_STATE_SELFTEST_BMS05 3 "DEM_INVALID" 2 "DEM_FAILED" 1 "DEM_PASSED" 0 "DEM_NOTTESTED" ;
VAL_ 1220 DEM097_SC_STATE_TEMP_BMS05 3 "DEM_INVALID" 2 "DEM_FAILED" 1 "DEM_PASSED" 0 "DEM_NOTTESTED" ;
VAL_ 1220 DEM098_SC_STATE_VOLTAGE_BMS05 3 "DEM_INVALID" 2 "DEM_FAILED" 1 "DEM_PASSED" 0 "DEM_NOTTESTED" ;
VAL_ 1220 DEM099_SC_STATE_HVIL_BMS05 3 "DEM_INVALID" 2 "DEM_FAILED" 1 "DEM_PASSED" 0 "DEM_NOTTESTED" ;
VAL_ 1220 DEM100_SC_STATE_CONTACTORS_BMS05 3 "DEM_INVALID" 2 "DEM_FAILED" 1 "DEM_PASSED" 0 "DEM_NOTTESTED" ;
VAL_ 1220 DEM101_SC_STATE_CURRENT_BMS05 3 "DEM_INVALID" 2 "DEM_FAILED" 1 "DEM_PASSED" 0 "DEM_NOTTESTED" ;
VAL_ 1220 DEM102_SC_STATE_CANRX_BMS05 3 "DEM_INVALID" 2 "DEM_FAILED" 1 "DEM_PASSED" 0 "DEM_NOTTESTED" ;
VAL_ 1220 DEM103_SC_STATE_CRASH_BMS05 3 "DEM_INVALID" 2 "DEM_FAILED" 1 "DEM_PASSED" 0 "DEM_NOTTESTED" ;
VAL_ 1220 DEM104_SC_STATE_CCTRL_BMS05 3 "DEM_INVALID" 2 "DEM_FAILED" 1 "DEM_PASSED" 0 "DEM_NOTTESTED" ;
VAL_ 1220 DEM105_SC_STATE_CANTX_BMS05 3 "DEM_INVALID" 2 "DEM_FAILED" 1 "DEM_PASSED" 0 "DEM_NOTTESTED" ;
VAL_ 1220 DEM106_SC_STATE_THERMALEVT_BMS05 3 "DEM_INVALID" 2 "DEM_FAILED" 1 "DEM_PASSED" 0 "DEM_NOTTESTED" ;
VAL_ 1220 DEM107_SC_STATE_COOLANT_BMS05 3 "DEM_INVALID" 2 "DEM_FAILED" 1 "DEM_PASSED" 0 "DEM_NOTTESTED" ;
VAL_ 1220 DEM108_SC_SELFTEST_SFTY_UC_BMS05 3 "DEM_INVALID" 2 "DEM_FAILED" 1 "DEM_PASSED" 0 "DEM_NOTTESTED" ;
VAL_ 1220 DEM109_SC_TEMP_HIGH_BMS05 3 "DEM_INVALID" 2 "DEM_FAILED" 1 "DEM_PASSED" 0 "DEM_NOTTESTED" ;
VAL_ 1220 DEM110_SC_TEMP_NTC_OPEN_BMS05 3 "DEM_INVALID" 2 "DEM_FAILED" 1 "DEM_PASSED" 0 "DEM_NOTTESTED" ;
VAL_ 1220 DEM111_SC_TEMP_NTC_SHORT_BMS05 3 "DEM_INVALID" 2 "DEM_FAILED" 1 "DEM_PASSED" 0 "DEM_NOTTESTED" ;
VAL_ 1220 DEM112_CMB_DISCONNECTED_BMS05 3 "DEM_INVALID" 2 "DEM_FAILED" 1 "DEM_PASSED" 0 "DEM_NOTTESTED" ;
VAL_ 1220 DEM113_CMB_DEFECT_BMS05 3 "DEM_INVALID" 2 "DEM_FAILED" 1 "DEM_PASSED" 0 "DEM_NOTTESTED" ;
VAL_ 1220 DEM114_CMB_COMMERROR_BMS05 3 "DEM_INVALID" 2 "DEM_FAILED" 1 "DEM_PASSED" 0 "DEM_NOTTESTED" ;
VAL_ 1220 DEM115_SC_CURR_HALL_PWR_LO_BMS05 3 "DEM_INVALID" 2 "DEM_FAILED" 1 "DEM_PASSED" 0 "DEM_NOTTESTED" ;
VAL_ 1220 DEM116_SC_CURR_HALL_VHIGH_BMS05 3 "DEM_INVALID" 2 "DEM_FAILED" 1 "DEM_PASSED" 0 "DEM_NOTTESTED" ;
VAL_ 1220 DEM117_SC_CURR_HALL_ADC_BMS05 3 "DEM_INVALID" 2 "DEM_FAILED" 1 "DEM_PASSED" 0 "DEM_NOTTESTED" ;
VAL_ 1220 DEM118_SC_CURR_HALL_VLOW_BMS05 3 "DEM_INVALID" 2 "DEM_FAILED" 1 "DEM_PASSED" 0 "DEM_NOTTESTED" ;
VAL_ 1220 DEM119_SC_CURR_ISENSE_PWR_BMS05 3 "DEM_INVALID" 2 "DEM_FAILED" 1 "DEM_PASSED" 0 "DEM_NOTTESTED" ;
VAL_ 1220 DEM120_SC_CURR_ISENSE1_MIA_BMS05 3 "DEM_INVALID" 2 "DEM_FAILED" 1 "DEM_PASSED" 0 "DEM_NOTTESTED" ;
VAL_ 1220 DEM121_SC_CURR_ISENSE2_MIA_BMS05 3 "DEM_INVALID" 2 "DEM_FAILED" 1 "DEM_PASSED" 0 "DEM_NOTTESTED" ;
VAL_ 1220 DEM122_SC_CURR_ISENSE3_MIA_BMS05 3 "DEM_INVALID" 2 "DEM_FAILED" 1 "DEM_PASSED" 0 "DEM_NOTTESTED" ;
VAL_ 1220 DEM123_SC_CURR_ISENSE4_MIA_BMS05 3 "DEM_INVALID" 2 "DEM_FAILED" 1 "DEM_PASSED" 0 "DEM_NOTTESTED" ;
VAL_ 1220 DEM124_SC_CURR_ISENSE5_MIA_BMS05 3 "DEM_INVALID" 2 "DEM_FAILED" 1 "DEM_PASSED" 0 "DEM_NOTTESTED" ;
VAL_ 1220 DEM125_SC_CURR_ISENSE1_FLT_BMS05 3 "DEM_INVALID" 2 "DEM_FAILED" 1 "DEM_PASSED" 0 "DEM_NOTTESTED" ;
VAL_ 1220 DEM126_SC_CURR_ISENSE2_FLT_BMS05 3 "DEM_INVALID" 2 "DEM_FAILED" 1 "DEM_PASSED" 0 "DEM_NOTTESTED" ;
VAL_ 1220 DEM127_SC_CURR_ISENSE3_FLT_BMS05 3 "DEM_INVALID" 2 "DEM_FAILED" 1 "DEM_PASSED" 0 "DEM_NOTTESTED" ;
VAL_ 1284 DEM128_SC_CURR_ISENSE4_FLT_BMS05 3 "DEM_INVALID" 2 "DEM_FAILED" 1 "DEM_PASSED" 0 "DEM_NOTTESTED" ;
VAL_ 1284 DEM129_SC_CURR_ISENSE5_FLT_BMS05 3 "DEM_INVALID" 2 "DEM_FAILED" 1 "DEM_PASSED" 0 "DEM_NOTTESTED" ;
VAL_ 1284 DEM130_SC_CURR_OFFSET_BMS05 3 "DEM_INVALID" 2 "DEM_FAILED" 1 "DEM_PASSED" 0 "DEM_NOTTESTED" ;
VAL_ 1284 DEM131_SC_CURR_PLAUSI_BMS05 3 "DEM_INVALID" 2 "DEM_FAILED" 1 "DEM_PASSED" 0 "DEM_NOTTESTED" ;
VAL_ 1284 DEM132_SC_CURR_CHARGE_HIGH_BMS05 3 "DEM_INVALID" 2 "DEM_FAILED" 1 "DEM_PASSED" 0 "DEM_NOTTESTED" ;
VAL_ 1284 DEM133_SC_CURR_DSCHAR_HIGH_BMS05 3 "DEM_INVALID" 2 "DEM_FAILED" 1 "DEM_PASSED" 0 "DEM_NOTTESTED" ;
VAL_ 1284 DEM134_SC_V_CMB_SUMOFCELL_BMS05 3 "DEM_INVALID" 2 "DEM_FAILED" 1 "DEM_PASSED" 0 "DEM_NOTTESTED" ;
VAL_ 1284 DEM135_SC_V_SENSE_OPENWIRE_BMS05 3 "DEM_INVALID" 2 "DEM_FAILED" 1 "DEM_PASSED" 0 "DEM_NOTTESTED" ;
VAL_ 1284 DEM136_SC_V_CMB_DRV_FROZEN_BMS05 3 "DEM_INVALID" 2 "DEM_FAILED" 1 "DEM_PASSED" 0 "DEM_NOTTESTED" ;
VAL_ 1284 DEM137_SC_V_PACK_PLAUSI_BMS05 3 "DEM_INVALID" 2 "DEM_FAILED" 1 "DEM_PASSED" 0 "DEM_NOTTESTED" ;
VAL_ 1284 DEM138_SC_HVIL_HW_FLT_BMS05 3 "DEM_INVALID" 2 "DEM_FAILED" 1 "DEM_PASSED" 0 "DEM_NOTTESTED" ;
VAL_ 1284 DEM139_SC_HVIL_OPEN_BMS05 3 "DEM_INVALID" 2 "DEM_FAILED" 1 "DEM_PASSED" 0 "DEM_NOTTESTED" ;
VAL_ 1284 DEM140_SC_HVIL_TO_SUP_BMS05 3 "DEM_INVALID" 2 "DEM_FAILED" 1 "DEM_PASSED" 0 "DEM_NOTTESTED" ;
VAL_ 1284 DEM141_SC_HVIL_TO_CHAS_BMS05 3 "DEM_INVALID" 2 "DEM_FAILED" 1 "DEM_PASSED" 0 "DEM_NOTTESTED" ;
VAL_ 1284 DEM142_SC_HVIL_R_HIGH_BMS05 3 "DEM_INVALID" 2 "DEM_FAILED" 1 "DEM_PASSED" 0 "DEM_NOTTESTED" ;
VAL_ 1284 DEM143_SC_HVIL_SHORT_BMS05 3 "DEM_INVALID" 2 "DEM_FAILED" 1 "DEM_PASSED" 0 "DEM_NOTTESTED" ;
VAL_ 1284 DEM144_SC_CN_ISO_FAIL_BMS05 3 "DEM_INVALID" 2 "DEM_FAILED" 1 "DEM_PASSED" 0 "DEM_NOTTESTED" ;
VAL_ 1284 DEM145_HVIL_SYS_BMS05 3 "DEM_INVALID" 2 "DEM_FAILED" 1 "DEM_PASSED" 0 "DEM_NOTTESTED" ;
VAL_ 1284 DEM146_SC_CN_POS1_WELDED_BMS05 3 "DEM_INVALID" 2 "DEM_FAILED" 1 "DEM_PASSED" 0 "DEM_NOTTESTED" ;
VAL_ 1284 DEM147_SC_CN_NEG1_WELDED_BMS05 3 "DEM_INVALID" 2 "DEM_FAILED" 1 "DEM_PASSED" 0 "DEM_NOTTESTED" ;
VAL_ 1284 DEM148_SC_CN_POS2_WELDED_BMS05 3 "DEM_INVALID" 2 "DEM_FAILED" 1 "DEM_PASSED" 0 "DEM_NOTTESTED" ;
VAL_ 1284 DEM149_SC_CN_NEG2_WELDED_BMS05 3 "DEM_INVALID" 2 "DEM_FAILED" 1 "DEM_PASSED" 0 "DEM_NOTTESTED" ;
VAL_ 1284 DEM150_SC_CN_POS3_WELDED_BMS05 3 "DEM_INVALID" 2 "DEM_FAILED" 1 "DEM_PASSED" 0 "DEM_NOTTESTED" ;
VAL_ 1284 DEM151_SC_CN_NEG3_WELDED_BMS05 3 "DEM_INVALID" 2 "DEM_FAILED" 1 "DEM_PASSED" 0 "DEM_NOTTESTED" ;
VAL_ 1284 DEM152_SC_CN_HIGH_CY_BMS05 3 "DEM_INVALID" 2 "DEM_FAILED" 1 "DEM_PASSED" 0 "DEM_NOTTESTED" ;
VAL_ 1284 DEM153_SC_CN_ISOANDPOTWELD_BMS05 3 "DEM_INVALID" 2 "DEM_FAILED" 1 "DEM_PASSED" 0 "DEM_NOTTESTED" ;
VAL_ 1284 DEM154_SC_TEMP_PLAUSI_BMS05 3 "DEM_INVALID" 2 "DEM_FAILED" 1 "DEM_PASSED" 0 "DEM_NOTTESTED" ;
VAL_ 1284 DEM155_SC_CURR_HALL_PWR_HI_BMS05 3 "DEM_INVALID" 2 "DEM_FAILED" 1 "DEM_PASSED" 0 "DEM_NOTTESTED" ;
VAL_ 1284 DEM156_SC_PYRO_TRIGGERED_BMS05 3 "DEM_INVALID" 2 "DEM_FAILED" 1 "DEM_PASSED" 0 "DEM_NOTTESTED" ;
VAL_ 1284 DEM157_SC_PYRO_OPEN_BMS05 3 "DEM_INVALID" 2 "DEM_FAILED" 1 "DEM_PASSED" 0 "DEM_NOTTESTED" ;
VAL_ 1284 DEM158_AUX_CTRS_END_OF_LIF_BMS05 3 "DEM_INVALID" 2 "DEM_FAILED" 1 "DEM_PASSED" 0 "DEM_NOTTESTED" ;
VAL_ 1284 DEM159_SC_CANRX_PT_MIA_BMS05 3 "DEM_INVALID" 2 "DEM_FAILED" 1 "DEM_PASSED" 0 "DEM_NOTTESTED" ;
VAL_ 1348 DEM160_SC_CANRX_PT_CRCALIV_BMS05 3 "DEM_INVALID" 2 "DEM_FAILED" 1 "DEM_PASSED" 0 "DEM_NOTTESTED" ;
VAL_ 1348 DEM161_SC_CANRX_LIN_SHUTDN_BMS05 3 "DEM_INVALID" 2 "DEM_FAILED" 1 "DEM_PASSED" 0 "DEM_NOTTESTED" ;
VAL_ 1348 DEM162_SC_CANRX_LIN_MIA_BMS05 3 "DEM_INVALID" 2 "DEM_FAILED" 1 "DEM_PASSED" 0 "DEM_NOTTESTED" ;
VAL_ 1348 DEM163_SC_CRASH1_BMS05 3 "DEM_INVALID" 2 "DEM_FAILED" 1 "DEM_PASSED" 0 "DEM_NOTTESTED" ;
VAL_ 1348 DEM164_SC_CRASH2_BMS05 3 "DEM_INVALID" 2 "DEM_FAILED" 1 "DEM_PASSED" 0 "DEM_NOTTESTED" ;
VAL_ 1348 DEM165_SC_CRASHCAN_BMS05 3 "DEM_INVALID" 2 "DEM_FAILED" 1 "DEM_PASSED" 0 "DEM_NOTTESTED" ;
VAL_ 1348 DEM166_SC_CCTRL_SELFTEST_BMS05 3 "DEM_INVALID" 2 "DEM_FAILED" 1 "DEM_PASSED" 0 "DEM_NOTTESTED" ;
VAL_ 1348 DEM167_SC_CCTRL_DRIVER_FAU_BMS05 3 "DEM_INVALID" 2 "DEM_FAILED" 1 "DEM_PASSED" 0 "DEM_NOTTESTED" ;
VAL_ 1348 DEM168_SC_CCTRL_HISIDESTCL_BMS05 3 "DEM_INVALID" 2 "DEM_FAILED" 1 "DEM_PASSED" 0 "DEM_NOTTESTED" ;
VAL_ 1348 DEM169_SC_CCTRL_HISIDESTOP_BMS05 3 "DEM_INVALID" 2 "DEM_FAILED" 1 "DEM_PASSED" 0 "DEM_NOTTESTED" ;
VAL_ 1348 DEM170_SC_CCTRL_LOSIDESTCL_BMS05 3 "DEM_INVALID" 2 "DEM_FAILED" 1 "DEM_PASSED" 0 "DEM_NOTTESTED" ;
VAL_ 1348 DEM171_SC_CCTRL_HVCNDITION_BMS05 3 "DEM_INVALID" 2 "DEM_FAILED" 1 "DEM_PASSED" 0 "DEM_NOTTESTED" ;
VAL_ 1348 DEM172_SC_CCTRL_POS1_OPN_BMS05 3 "DEM_INVALID" 2 "DEM_FAILED" 1 "DEM_PASSED" 0 "DEM_NOTTESTED" ;
VAL_ 1348 DEM173_SC_CCTRL_POS2_OPN_BMS05 3 "DEM_INVALID" 2 "DEM_FAILED" 1 "DEM_PASSED" 0 "DEM_NOTTESTED" ;
VAL_ 1348 DEM174_SC_CCTRL_POS3_OPN_BMS05 3 "DEM_INVALID" 2 "DEM_FAILED" 1 "DEM_PASSED" 0 "DEM_NOTTESTED" ;
VAL_ 1348 DEM175_SC_CCTRL_NEG1_OPN_BMS05 3 "DEM_INVALID" 2 "DEM_FAILED" 1 "DEM_PASSED" 0 "DEM_NOTTESTED" ;
VAL_ 1348 DEM176_SC_CCTRL_NEG2_OPN_BMS05 3 "DEM_INVALID" 2 "DEM_FAILED" 1 "DEM_PASSED" 0 "DEM_NOTTESTED" ;
VAL_ 1348 DEM177_SC_CCTRL_PRE2_OPN_BMS05 3 "DEM_INVALID" 2 "DEM_FAILED" 1 "DEM_PASSED" 0 "DEM_NOTTESTED" ;
VAL_ 1348 DEM178_SC_CCTRL_PRE1_OPN_BMS05 3 "DEM_INVALID" 2 "DEM_FAILED" 1 "DEM_PASSED" 0 "DEM_NOTTESTED" ;
VAL_ 1348 DEM179_SC_CCTRL_LOSIDESTOP_BMS05 3 "DEM_INVALID" 2 "DEM_FAILED" 1 "DEM_PASSED" 0 "DEM_NOTTESTED" ;
VAL_ 1348 DEM180_SC_CCTRL_UNEXPECTED_BMS05 3 "DEM_INVALID" 2 "DEM_FAILED" 1 "DEM_PASSED" 0 "DEM_NOTTESTED" ;
VAL_ 1348 DEM181_SC_V_OUT_OF_RANGE_BMS05 3 "DEM_INVALID" 2 "DEM_FAILED" 1 "DEM_PASSED" 0 "DEM_NOTTESTED" ;
VAL_ 1348 DEM182_SC_V_LATCHED_UVOV_BMS05 3 "DEM_INVALID" 2 "DEM_FAILED" 1 "DEM_PASSED" 0 "DEM_NOTTESTED" ;
VAL_ 1348 DEM183_ISO_EXT_STRAT_2_BMS05 3 "DEM_INVALID" 2 "DEM_FAILED" 1 "DEM_PASSED" 0 "DEM_NOTTESTED" ;
VAL_ 1348 DEM184_SC_CANTX_CTRS_BMS05 3 "DEM_INVALID" 2 "DEM_FAILED" 1 "DEM_PASSED" 0 "DEM_NOTTESTED" ;
VAL_ 1348 DEM185_SC_CANTX_HVIL_BMS05 3 "DEM_INVALID" 2 "DEM_FAILED" 1 "DEM_PASSED" 0 "DEM_NOTTESTED" ;
VAL_ 1348 DEM186_SC_CANTX_ISOL_BMS05 3 "DEM_INVALID" 2 "DEM_FAILED" 1 "DEM_PASSED" 0 "DEM_NOTTESTED" ;
VAL_ 1348 DEM187_SC_SBC_WATCHDOG_BMS05 3 "DEM_INVALID" 2 "DEM_FAILED" 1 "DEM_PASSED" 0 "DEM_NOTTESTED" ;
VAL_ 1348 DEM188_SC_SBC_FAULT_BMS05 3 "DEM_INVALID" 2 "DEM_FAILED" 1 "DEM_PASSED" 0 "DEM_NOTTESTED" ;
VAL_ 1348 DEM189_SC_WATCHDOG_BMS05 3 "DEM_INVALID" 2 "DEM_FAILED" 1 "DEM_PASSED" 0 "DEM_NOTTESTED" ;
VAL_ 1348 DEM190_SC_SELFTEST_RAM_BMS05 3 "DEM_INVALID" 2 "DEM_FAILED" 1 "DEM_PASSED" 0 "DEM_NOTTESTED" ;
VAL_ 1348 DEM191_SC_SELFTEST_FLASH_BMS05 3 "DEM_INVALID" 2 "DEM_FAILED" 1 "DEM_PASSED" 0 "DEM_NOTTESTED" ;
VAL_ 1412 DEM192_CMB_ONBOARDRH_OH_BMS05 3 "DEM_INVALID" 2 "DEM_FAILED" 1 "DEM_PASSED" 0 "DEM_NOTTESTED" ;
VAL_ 1412 DEM193_CMB_ONBOARDRH_SNA_BMS05 3 "DEM_INVALID" 2 "DEM_FAILED" 1 "DEM_PASSED" 0 "DEM_NOTTESTED" ;
VAL_ 1412 DEM194_CMB_ONBOARDT_OT_BMS05 3 "DEM_INVALID" 2 "DEM_FAILED" 1 "DEM_PASSED" 0 "DEM_NOTTESTED" ;
VAL_ 1412 DEM195_CMB_ONBOARDT_CHANGE_BMS05 3 "DEM_INVALID" 2 "DEM_FAILED" 1 "DEM_PASSED" 0 "DEM_NOTTESTED" ;
VAL_ 1412 DEM196_PRESSURE_CHANGE_BMS05 3 "DEM_INVALID" 2 "DEM_FAILED" 1 "DEM_PASSED" 0 "DEM_NOTTESTED" ;
VAL_ 1412 DEM197_PRESSURE_OVER_BMS05 3 "DEM_INVALID" 2 "DEM_FAILED" 1 "DEM_PASSED" 0 "DEM_NOTTESTED" ;
VAL_ 1412 DEM198_PRESSURE_UNDER_BMS05 3 "DEM_INVALID" 2 "DEM_FAILED" 1 "DEM_PASSED" 0 "DEM_NOTTESTED" ;
VAL_ 1412 DEM199_PRESSURE_INVALID_BMS05 3 "DEM_INVALID" 2 "DEM_FAILED" 1 "DEM_PASSED" 0 "DEM_NOTTESTED" ;
VAL_ 1412 DEM200_THERMAL_EVENT_BMS05 3 "DEM_INVALID" 2 "DEM_FAILED" 1 "DEM_PASSED" 0 "DEM_NOTTESTED" ;
VAL_ 1412 DEM201_CMB_ONBOARDT_SNA_BMS05 3 "DEM_INVALID" 2 "DEM_FAILED" 1 "DEM_PASSED" 0 "DEM_NOTTESTED" ;
VAL_ 1412 DEM202_REPLACE_DESICCANT_BMS05 3 "DEM_INVALID" 2 "DEM_FAILED" 1 "DEM_PASSED" 0 "DEM_NOTTESTED" ;
VAL_ 1412 DEM203_COOLANT_FLOOD_FAULT_BMS05 3 "DEM_INVALID" 2 "DEM_FAILED" 1 "DEM_PASSED" 0 "DEM_NOTTESTED" ;
VAL_ 1412 DEM204_LOW_BRICKCAPACITY_BMS05 3 "DEM_INVALID" 2 "DEM_FAILED" 1 "DEM_PASSED" 0 "DEM_NOTTESTED" ;
VAL_ 1412 DEM205_BMS_ONBOARDT_OT_BMS05 3 "DEM_INVALID" 2 "DEM_FAILED" 1 "DEM_PASSED" 0 "DEM_NOTTESTED" ;
VAL_ 1412 DEM206_HUMIDITY_CHANGE_BMS05 3 "DEM_INVALID" 2 "DEM_FAILED" 1 "DEM_PASSED" 0 "DEM_NOTTESTED" ;
VAL_ 1412 DEM207_ISENSE_SUPPLY_CURR_BMS05 3 "DEM_INVALID" 2 "DEM_FAILED" 1 "DEM_PASSED" 0 "DEM_NOTTESTED" ;
VAL_ 1412 DEM208_SOC_LOW_BMS05 3 "DEM_INVALID" 2 "DEM_FAILED" 1 "DEM_PASSED" 0 "DEM_NOTTESTED" ;
VAL_ 1412 DEM209_SOC_TOOLOW_BMS05 3 "DEM_INVALID" 2 "DEM_FAILED" 1 "DEM_PASSED" 0 "DEM_NOTTESTED" ;
VAL_ 1412 DEM210_SOC_TOOHIGH_BMS05 3 "DEM_INVALID" 2 "DEM_FAILED" 1 "DEM_PASSED" 0 "DEM_NOTTESTED" ;
VAL_ 1412 DEM211_BALANCING_REQUIRED_BMS05 3 "DEM_INVALID" 2 "DEM_FAILED" 1 "DEM_PASSED" 0 "DEM_NOTTESTED" ;
VAL_ 1412 DEM212_DEEP_DISCHARGE_BMS05 3 "DEM_INVALID" 2 "DEM_FAILED" 1 "DEM_PASSED" 0 "DEM_NOTTESTED" ;
VAL_ 1412 DEM213_CAN1_BUS_OFF_BMS05 3 "DEM_INVALID" 2 "DEM_FAILED" 1 "DEM_PASSED" 0 "DEM_NOTTESTED" ;
VAL_ 1412 DEM214_CAN2_BUS_OFF_BMS05 3 "DEM_INVALID" 2 "DEM_FAILED" 1 "DEM_PASSED" 0 "DEM_NOTTESTED" ;
VAL_ 1412 DEM215_CAN3_BUS_OFF_BMS05 3 "DEM_INVALID" 2 "DEM_FAILED" 1 "DEM_PASSED" 0 "DEM_NOTTESTED" ;
VAL_ 1412 DEM216_OUTLET_NTC_RATNAL_BMS05 3 "DEM_INVALID" 2 "DEM_FAILED" 1 "DEM_PASSED" 0 "DEM_NOTTESTED" ;
VAL_ 1412 DEM217_FUSE_PACK_BMS05 3 "DEM_INVALID" 2 "DEM_FAILED" 1 "DEM_PASSED" 0 "DEM_NOTTESTED" ;
VAL_ 1412 DEM218_FUSE_B_OPEN_BMS05 3 "DEM_INVALID" 2 "DEM_FAILED" 1 "DEM_PASSED" 0 "DEM_NOTTESTED" ;
VAL_ 1412 DEM219_FUSE_C_OPEN_BMS05 3 "DEM_INVALID" 2 "DEM_FAILED" 1 "DEM_PASSED" 0 "DEM_NOTTESTED" ;
VAL_ 1412 DEM220_FUSE_D_OPEN_BMS05 3 "DEM_INVALID" 2 "DEM_FAILED" 1 "DEM_PASSED" 0 "DEM_NOTTESTED" ;
VAL_ 1412 DEM221_FUSE_E_OPEN_BMS05 3 "DEM_INVALID" 2 "DEM_FAILED" 1 "DEM_PASSED" 0 "DEM_NOTTESTED" ;
VAL_ 1412 DEM222_PUMP_DRY_RUN_BMS05 3 "DEM_INVALID" 2 "DEM_FAILED" 1 "DEM_PASSED" 0 "DEM_NOTTESTED" ;
VAL_ 1412 DEM223_PUMP_PERFORMANCE_BMS05 3 "DEM_INVALID" 2 "DEM_FAILED" 1 "DEM_PASSED" 0 "DEM_NOTTESTED" ;
VAL_ 1476 DEM224_PUMP_LIN_FAILURE_BMS05 3 "DEM_INVALID" 2 "DEM_FAILED" 1 "DEM_PASSED" 0 "DEM_NOTTESTED" ;
VAL_ 1476 DEM225_PUMP_SUPPLY_VOLTAGE_BMS05 3 "DEM_INVALID" 2 "DEM_FAILED" 1 "DEM_PASSED" 0 "DEM_NOTTESTED" ;
VAL_ 1476 DEM226_PUMP_RECOVERY_FAIL_BMS05 3 "DEM_INVALID" 2 "DEM_FAILED" 1 "DEM_PASSED" 0 "DEM_NOTTESTED" ;
VAL_ 1476 DEM227_CTR_POS_OPENED_BMS05 3 "DEM_INVALID" 2 "DEM_FAILED" 1 "DEM_PASSED" 0 "DEM_NOTTESTED" ;
VAL_ 1476 DEM228_CTR_NEG_OPENED_BMS05 3 "DEM_INVALID" 2 "DEM_FAILED" 1 "DEM_PASSED" 0 "DEM_NOTTESTED" ;
VAL_ 1476 DEM229_STRSET_SLAVE1_FAULT_BMS05 3 "DEM_INVALID" 2 "DEM_FAILED" 1 "DEM_PASSED" 0 "DEM_NOTTESTED" ;
VAL_ 1476 DEM230_STRSET_SLAVE2_FAULT_BMS05 3 "DEM_INVALID" 2 "DEM_FAILED" 1 "DEM_PASSED" 0 "DEM_NOTTESTED" ;
VAL_ 1476 DEM231_CTRSAUX_CLFAIL_HVON_BMS05 3 "DEM_INVALID" 2 "DEM_FAILED" 1 "DEM_PASSED" 0 "DEM_NOTTESTED" ;
VAL_ 1476 DEM232_CTRSAUX_CLFAIL_VDIF_BMS05 3 "DEM_INVALID" 2 "DEM_FAILED" 1 "DEM_PASSED" 0 "DEM_NOTTESTED" ;
VAL_ 1476 DEM233_CTRSAUX_POS1_OPENED_BMS05 3 "DEM_INVALID" 2 "DEM_FAILED" 1 "DEM_PASSED" 0 "DEM_NOTTESTED" ;
VAL_ 1476 DEM234_CTRSAUX_NEG1_OPENED_BMS05 3 "DEM_INVALID" 2 "DEM_FAILED" 1 "DEM_PASSED" 0 "DEM_NOTTESTED" ;
VAL_ 1476 DEM235_CTRSAUX_POS1_WELDED_BMS05 3 "DEM_INVALID" 2 "DEM_FAILED" 1 "DEM_PASSED" 0 "DEM_NOTTESTED" ;
VAL_ 1476 DEM236_CTRSAUX_NEG1_WELDED_BMS05 3 "DEM_INVALID" 2 "DEM_FAILED" 1 "DEM_PASSED" 0 "DEM_NOTTESTED" ;
VAL_ 1476 DEM237_CTRSAUX_POS1_PULLIN_BMS05 3 "DEM_INVALID" 2 "DEM_FAILED" 1 "DEM_PASSED" 0 "DEM_NOTTESTED" ;
VAL_ 1476 DEM238_CTRSAUX_NEG1_PULLIN_BMS05 3 "DEM_INVALID" 2 "DEM_FAILED" 1 "DEM_PASSED" 0 "DEM_NOTTESTED" ;
VAL_ 1476 DEM239_INLET_NTC_RATNAL_BMS05 3 "DEM_INVALID" 2 "DEM_FAILED" 1 "DEM_PASSED" 0 "DEM_NOTTESTED" ;
VAL_ 1476 DEM240_INLET_NTC_HI_BMS05 3 "DEM_INVALID" 2 "DEM_FAILED" 1 "DEM_PASSED" 0 "DEM_NOTTESTED" ;
VAL_ 1476 DEM241_INLET_NTC_LO_BMS05 3 "DEM_INVALID" 2 "DEM_FAILED" 1 "DEM_PASSED" 0 "DEM_NOTTESTED" ;
VAL_ 1476 DEM242_VOLTAGE_LINK2_RATNA_BMS05 3 "DEM_INVALID" 2 "DEM_FAILED" 1 "DEM_PASSED" 0 "DEM_NOTTESTED" ;
VAL_ 1476 DEM243_VOLTAGE_LINK2_HI_BMS05 3 "DEM_INVALID" 2 "DEM_FAILED" 1 "DEM_PASSED" 0 "DEM_NOTTESTED" ;
VAL_ 1476 DEM244_VOLTAGE_LINK2_LO_BMS05 3 "DEM_INVALID" 2 "DEM_FAILED" 1 "DEM_PASSED" 0 "DEM_NOTTESTED" ;
VAL_ 1476 DEM245_CMB_ONBOARD_IMPOSSI_BMS05 3 "DEM_INVALID" 2 "DEM_FAILED" 1 "DEM_PASSED" 0 "DEM_NOTTESTED" ;
VAL_ 1476 DEM246_VOLTAGE_LINK1_HI_BMS05 3 "DEM_INVALID" 2 "DEM_FAILED" 1 "DEM_PASSED" 0 "DEM_NOTTESTED" ;
VAL_ 1476 DEM247_VOLTAGE_LINK1_LO_BMS05 3 "DEM_INVALID" 2 "DEM_FAILED" 1 "DEM_PASSED" 0 "DEM_NOTTESTED" ;
VAL_ 1476 DEM248_NTC_SUPPLY_LO_BMS05 3 "DEM_INVALID" 2 "DEM_FAILED" 1 "DEM_PASSED" 0 "DEM_NOTTESTED" ;
VAL_ 1476 DEM249_NTC_SUPPLY_HI_BMS05 3 "DEM_INVALID" 2 "DEM_FAILED" 1 "DEM_PASSED" 0 "DEM_NOTTESTED" ;
VAL_ 1476 DEM250_VOLTAGE_LINK3_RATNA_BMS05 3 "DEM_INVALID" 2 "DEM_FAILED" 1 "DEM_PASSED" 0 "DEM_NOTTESTED" ;
VAL_ 1476 DEM251_VOLTAGE_LINK3_HI_BMS05 3 "DEM_INVALID" 2 "DEM_FAILED" 1 "DEM_PASSED" 0 "DEM_NOTTESTED" ;
VAL_ 1476 DEM252_VOLTAGE_LINK3_LO_BMS05 3 "DEM_INVALID" 2 "DEM_FAILED" 1 "DEM_PASSED" 0 "DEM_NOTTESTED" ;
VAL_ 1476 DEM253_BALANCING_STUCK_BMS05 3 "DEM_INVALID" 2 "DEM_FAILED" 1 "DEM_PASSED" 0 "DEM_NOTTESTED" ;
VAL_ 1476 DEM254_ARM_EXCEPTION_BMS05 3 "DEM_INVALID" 2 "DEM_FAILED" 1 "DEM_PASSED" 0 "DEM_NOTTESTED" ;
VAL_ 1476 DEM255_ERROR_HOOKS_BMS05 3 "DEM_INVALID" 2 "DEM_FAILED" 1 "DEM_PASSED" 0 "DEM_NOTTESTED" ;
VAL_ 836 DEM256_XCP_CAL_CHANGE_BMS05 3 "DEM_INVALID" 2 "DEM_FAILED" 1 "DEM_PASSED" 0 "DEM_NOTTESTED" ;
VAL_ 836 DEM257_XCP_CAL_PERM_CHANGE_BMS05 3 "DEM_INVALID" 2 "DEM_FAILED" 1 "DEM_PASSED" 0 "DEM_NOTTESTED" ;
VAL_ 836 DEM258_TASK_TIME_OVERFLOW_BMS05 3 "DEM_INVALID" 2 "DEM_FAILED" 1 "DEM_PASSED" 0 "DEM_NOTTESTED" ;
VAL_ 836 DEM259_ISO_CIRCUIT_BMS05 3 "DEM_INVALID" 2 "DEM_FAILED" 1 "DEM_PASSED" 0 "DEM_NOTTESTED" ;
VAL_ 836 DEM260_COOLANT_MOIST_FAULT_BMS05 3 "DEM_INVALID" 2 "DEM_FAILED" 1 "DEM_PASSED" 0 "DEM_NOTTESTED" ;
VAL_ 836 DEM261_COOLANT_FLOOD_WARN_BMS05 3 "DEM_INVALID" 2 "DEM_FAILED" 1 "DEM_PASSED" 0 "DEM_NOTTESTED" ;
VAL_ 836 DEM262_COOLANT_MOIST_WARN_BMS05 3 "DEM_INVALID" 2 "DEM_FAILED" 1 "DEM_PASSED" 0 "DEM_NOTTESTED" ;
VAL_ 836 DEM263_MODULET_IMPLAUSIBLE_BMS05 3 "DEM_INVALID" 2 "DEM_FAILED" 1 "DEM_PASSED" 0 "DEM_NOTTESTED" ;
VAL_ 836 DEM264_REQUEST_ON_WITH_HV__BMS05 3 "DEM_INVALID" 2 "DEM_FAILED" 1 "DEM_PASSED" 0 "DEM_NOTTESTED" ;
VAL_ 836 DEM265_CSERS_PCODE_BMS05 3 "DEM_INVALID" 2 "DEM_FAILED" 1 "DEM_PASSED" 0 "DEM_NOTTESTED" ;
VAL_ 836 DEM266_PRELIM_CNTR_CL_FAIL_BMS05 3 "DEM_INVALID" 2 "DEM_FAILED" 1 "DEM_PASSED" 0 "DEM_NOTTESTED" ;
VAL_ 836 DEM267_FLUIDLVL_LOW_BMS05 3 "DEM_INVALID" 2 "DEM_FAILED" 1 "DEM_PASSED" 0 "DEM_NOTTESTED" ;
VAL_ 836 DEM268_FLUIDLVL_FAILURE_BMS05 3 "DEM_INVALID" 2 "DEM_FAILED" 1 "DEM_PASSED" 0 "DEM_NOTTESTED" ;
VAL_ 836 DEM269_SC_COOLANT_CONTAM_BMS05 3 "DEM_INVALID" 2 "DEM_FAILED" 1 "DEM_PASSED" 0 "DEM_NOTTESTED" ;
VAL_ 836 DEM270_SC_COOLANT_MIA_BMS05 3 "DEM_INVALID" 2 "DEM_FAILED" 1 "DEM_PASSED" 0 "DEM_NOTTESTED" ;
VAL_ 836 DEM271_PRESSURE_VHI_BMS05 3 "DEM_INVALID" 2 "DEM_FAILED" 1 "DEM_PASSED" 0 "DEM_NOTTESTED" ;
VAL_ 836 DEM272_PRESSURE_VLO_BMS05 3 "DEM_INVALID" 2 "DEM_FAILED" 1 "DEM_PASSED" 0 "DEM_NOTTESTED" ;
VAL_ 836 DEM273_SC_COOLANT_FAIL_BMS05 3 "DEM_INVALID" 2 "DEM_FAILED" 1 "DEM_PASSED" 0 "DEM_NOTTESTED" ;
VAL_ 836 DEM274_CTRSAUX_POS2_OPENED_BMS05 3 "DEM_INVALID" 2 "DEM_FAILED" 1 "DEM_PASSED" 0 "DEM_NOTTESTED" ;
VAL_ 836 DEM275_CTRSAUX_POS3_OPENED_BMS05 3 "DEM_INVALID" 2 "DEM_FAILED" 1 "DEM_PASSED" 0 "DEM_NOTTESTED" ;
VAL_ 836 DEM276_CTRSAUX_POS2_WELDED_BMS05 3 "DEM_INVALID" 2 "DEM_FAILED" 1 "DEM_PASSED" 0 "DEM_NOTTESTED" ;
VAL_ 836 DEM277_CTRSAUX_POS3_WELDED_BMS05 3 "DEM_INVALID" 2 "DEM_FAILED" 1 "DEM_PASSED" 0 "DEM_NOTTESTED" ;
VAL_ 836 DEM278_CTRSAUX_POS2_PULLIN_BMS05 3 "DEM_INVALID" 2 "DEM_FAILED" 1 "DEM_PASSED" 0 "DEM_NOTTESTED" ;
VAL_ 836 DEM279_CTRSAUX_POS3_PULLIN_BMS05 3 "DEM_INVALID" 2 "DEM_FAILED" 1 "DEM_PASSED" 0 "DEM_NOTTESTED" ;
VAL_ 836 DEM280_CMB_HUMIDITY_TEMP_C_BMS05 3 "DEM_INVALID" 2 "DEM_FAILED" 1 "DEM_PASSED" 0 "DEM_NOTTESTED" ;
VAL_ 836 DEM281_THERMAL_EVENT_CMB_R_BMS05 3 "DEM_INVALID" 2 "DEM_FAILED" 1 "DEM_PASSED" 0 "DEM_NOTTESTED" ;
VAL_ 836 DEM282_CUS_BRICKOV_BMS05 3 "DEM_INVALID" 2 "DEM_FAILED" 1 "DEM_PASSED" 0 "DEM_NOTTESTED" ;
VAL_ 836 DEM283_CUS_BRICKUV_BMS05 3 "DEM_INVALID" 2 "DEM_FAILED" 1 "DEM_PASSED" 0 "DEM_NOTTESTED" ;
VAL_ 836 DEM284_CUS_OVERCHRG_BMS05 3 "DEM_INVALID" 2 "DEM_FAILED" 1 "DEM_PASSED" 0 "DEM_NOTTESTED" ;
VAL_ 836 DEM285_CUS_OVERDCHRG_BMS05 3 "DEM_INVALID" 2 "DEM_FAILED" 1 "DEM_PASSED" 0 "DEM_NOTTESTED" ;
VAL_ 836 DEM286_CUS_CURRENT_CHG_BMS05 3 "DEM_INVALID" 2 "DEM_FAILED" 1 "DEM_PASSED" 0 "DEM_NOTTESTED" ;
VAL_ 836 DEM287_CUS_CURRENT_DCHG_BMS05 3 "DEM_INVALID" 2 "DEM_FAILED" 1 "DEM_PASSED" 0 "DEM_NOTTESTED" ;
VAL_ 1604 selfTestStartupFault_SC05 6 "SELFTEST_PBIST_OTHER_RAM_FAULT" 5 "SELFTEST_PBIST_CPU_RAM_FAULT" 4 "SELFTEST_PBIST_ROM_FAULT" 3 "SELFTEST_PBIST_STC_ROM_FAULT" 2 "SELFTEST_STC_FAULT" 1 "SELFTEST_CPU_FAULT" 0 "SELFTEST_STARTUP_OK" ;
VAL_ 1604 sbcARTimerStatus_SC05 15 "SNA" 6 "SBC_AR_COMPLETE" 5 "SBC_AR_INTERRUPTED" 4 "SBC_AR_READ_SUCCESS" 3 "SBC_AR_STOPPED" 2 "SBC_AR_RUNTOSTOP" 0 "SBC_AR_INIT" 1 "SBC_AR_RUNNING" ;
VAL_ 1604 sbcARTimerValue_SC05 255 "SNA" ;
VAL_ 1604 cmbVAIndex_SC05 255 "CMB_NONE" ;
VAL_ 1604 minVACMB_SC05 65535 "SNA" ;
VAL_ 1604 maxVACMB_SC05 65535 "SNA" ;
VAL_ 1604 pumpInternalFaultError_SC05 1 "ERROR" 0 "NO_ERROR" ;
VAL_ 1604 pumpShortCircuitError_SC05 1 "ERROR" 0 "NO_ERROR" ;
VAL_ 1604 pumpElectricError_SC05 1 "ERROR" 0 "NO_ERROR" 3 "SNA" ;
VAL_ 1604 pumpPostRunMode_SC05 7 "SNA" 4 "SPEED_4" 3 "SPEED_3" 2 "SPEED_2" 1 "SPEED_1" 0 "NO_POST_RUN" ;
VAL_ 1604 pumpRsError_SC05 1 "ERROR" 0 "NO_ERROR" ;
VAL_ 1604 pumpWakeUpStatus_SC05 2 "NDEF2" 1 "ACTIVE_WUP" 0 "NO_WUP" 3 "SNA" ;
VAL_ 1604 pumpRpmMonStat_SC05 1 "NO_MON" 0 "MON_ACTIVE" 3 "SNA" ;
VAL_ 1604 pumpPwmInStat_SC05 1 "HIGH" 0 "LOW" 3 "SNA" ;
VAL_ 1604 pumpDiagTriggered_SC05 1 "TRUE" 0 "FALSE" ;
VAL_ 1604 pumpHwFault_SC05 1 "ERROR" 0 "NO_ERROR" ;
VAL_ 1604 pumpPumpState_SC05 6 "ERROR" 5 "HARDWARE_ERROR" 1 "RUN" 0 "IDLE" 7 "SNA" ;
VAL_ 1604 pumpBlockError_SC05 0 "NO_ERROR" 1 "ERROR" 3 "SNA" ;
VAL_ 1604 pumpLinError_SC05 1 "ERROR" 0 "NO_ERROR" ;
VAL_ 1604 pumpDryRun_SC05 1 "ERROR" 0 "NO_ERROR" 3 "SNA" ;
VAL_ 1604 pumpOverCurrent_SC05 1 "ERROR" 0 "NO_ERROR" 3 "SNA" ;
VAL_ 1604 pumpVoltageDeratingError_SC05 1 "ERROR" 0 "NO_ERROR" ;
VAL_ 1604 pumpSupVoltageError_SC05 1 "ERROR" 0 "NO_ERROR" 3 "SNA" ;
VAL_ 1604 pumpUnderVoltage_SC05 1 "ERROR" 0 "NO_ERROR" ;
VAL_ 1604 pumpOverVoltage_SC05 1 "ERROR" 0 "NO_ERROR" ;
VAL_ 1604 pumpTempProtect_SC05 1 "ERROR" 0 "NO_ERROR" ;
VAL_ 1604 pumpOverTempDeratingErr_SC05 1 "ERROR" 0 "NO_ERROR" ;
VAL_ 1604 pumpOverTemperature_SC05 1 "ERROR" 0 "NO_ERROR" 3 "SNA" ;
VAL_ 1604 pressure2_SC05 255 "SNA" ;
VAL_ 1604 cmbSM29ScoutTempIndex_SC05 255 "SNA" ;
VAL_ 1604 cmbSM19ScoutPDO_SC05 65535 "SNA" ;
VAL_ 1604 isolationResInternRelaxed_SC05 65535 "SNA" ;
VAL_ 1604 appTask500HzMaxAvg_SC05 255 "SNA" ;
VAL_ 1604 safetyHangLastLinkReg_SC05 -1 "SNA" ;
VAL_ 1604 safetyHangPresentLinkReg_SC05 -1 "SNA" ;
VAL_ 1604 safetyHangDataFaultStatus_SC05 -1 "SNA" ;
VAL_ 1604 safetyHangDataFaultAddr_SC05 -1 "SNA" ;
VAL_ 1604 safetyHangLastARMMode_SC05 255 "MODE_UNKNOWN" 6 "MODE_SYS" 5 "MODE_UND" 4 "MODE_ABT" 3 "MODE_SVC" 2 "MODE_IRQ" 1 "MODE_FIQ" 0 "MODE_USER" ;
VAL_ 1604 safetyHangPresARMMode_SC05 255 "MODE_UNKNOWN" 6 "MODE_SYS" 5 "MODE_UND" 4 "MODE_ABT" 3 "MODE_SVC" 2 "MODE_IRQ" 1 "MODE_FIQ" 0 "MODE_USER" ;
VAL_ 1604 safetyHangESMGrp3Reg_SC05 -1 "SNA" ;
VAL_ 1604 safetyHangInstrFaultStatus_SC05 -1 "SNA" ;
VAL_ 1604 safetyHangInstrFaultAddr_SC05 -1 "SNA" ;
VAL_ 1604 pressure_SC05 255 "SNA" ;
VAL_ 1604 cmbMaxSM33Diff_SC05 255 "SNA" ;
VAL_ 1604 cmbMinSM29Diff_SC05 255 "SNA" ;
VAL_ 1604 cmbMinSM4Diff_SC05 65535 "SNA" ;
VAL_ 1604 cmbMaxSM4Diff_SC05 65535 "SNA" ;
VAL_ 1604 cmbMinSM27Diff_SC05 65535 "SNA" ;
VAL_ 1604 cmbMaxSM27Diff_SC05 65535 "SNA" ;
VAL_ 1604 adcDriverFail_SC05 12 "ADCDRIVER_SBCSUPPLY_FF" 11 "ADCDRIVER_MUX960_FF" 10 "ADCDRIVER_MUX910_FF" 9 "ADCDRIVER_UNDEF" 8 "ADCDRIVER_ADCVAR" 7 "ADCDRIVER_SLEEP_FF" 6 "ADCDRIVER_PYRO_FF" 5 "ADCDRIVER_MUX710_FF" 4 "ADCDRIVER_MUX440_FF" 3 "ADCDRIVER_MUX302A_FF" 2 "ADCDRIVER_MUX301B_FF" 1 "ADCDRIVER_MUX301A_FF" 0 "ADCDRIVER_NO_ISSUE" ;
VAL_ 1604 mainUcHvilState_SC05 2 "CANTX_HVIL_CLOSE" 3 "CANTX_HVIL_SNA" 1 "CANTX_HVIL_OPEN" 0 "CANTX_HVIL_NOT_AVAIL" ;
VAL_ 1604 mainUcIntIsoErr_SC05 3 "ISOLATION_SNA" 2 "ISOLATION_ERR_OFF" 1 "ISOLATION_ERROR" 0 "ISOLATION_OK" ;
VAL_ 1604 mainUcExtIsoErr_SC05 3 "ISOLATION_SNA" 2 "ISOLATION_ERR_OFF" 1 "ISOLATION_ERROR" 0 "ISOLATION_OK" ;
VAL_ 1604 safetyUcThermalStatus_SC05 3 "THERMALEVENT_SNA" 2 "THERMALEVENT_WARN_2" 1 "THERMALEVENT_WARN_1" 0 "THERMALEVENT_NO_WARN" ;
VAL_ 1604 mainUcThermalStatus_SC05 3 "THERMALEVENT_SNA" 2 "THERMALEVENT_WARN_2" 1 "THERMALEVENT_WARN_1" 0 "THERMALEVENT_NO_WARN" ;
VAL_ 1604 selfTestDataFaultStatus_SC05 -1 "SNA" ;
VAL_ 1604 selfTestInstrFaultAddr_SC05 -1 "SNA" ;
VAL_ 1604 selfTestDataFaultAddr_SC05 -1 "SNA" ;
VAL_ 1604 selfTestInstrFaultStatus_SC05 -1 "SNA" ;
VAL_ 1604 internalIsolationError_SC05 3 "ISOLATION_SNA" 2 "ISOLATION_ERR_OFF" 1 "ISOLATION_ERROR" 0 "ISOLATION_OK" ;
VAL_ 1604 externalIsolationError_SC05 3 "ISOLATION_SNA" 2 "ISOLATION_ERR_OFF" 1 "ISOLATION_ERROR" 0 "ISOLATION_OK" ;
VAL_ 1604 isolationTestState_SC05 3 "ISOLATION_TEST_POSNEG" 2 "ISOLATION_TEST_NEG" 1 "ISOLATION_TEST_POS" 0 "ISOLATION_OFF" ;
VAL_ 1604 isolationResistanceIntern_SC05 65535 "SNA" ;
VAL_ 1604 isolationResistanceExtern_SC05 65535 "SNA" ;
VAL_ 1604 maxAdolV13Diff_SC05 65535 "SNA" ;
VAL_ 1604 pumpType_SC05 0 "PUMP_NONE" 1 "PUMP_MAL" 2 "PUMP_BOSCH" 3 "PUMP_JOMA" 4 "PUMP_MAHLE" 255 "SNA" ;
VAL_ 1604 pumpPhaseCurrent_SC05 255 "SNA" ;
VAL_ 1604 hvWithstandTestQual_SC05 1 "QUAL_ERROR" 0 "QUAL_VALID" ;
VAL_ 1604 currentModuleMax_SC05 65535 "SNA" ;
VAL_ 1604 currentModuleMin_SC05 65535 "SNA" ;
VAL_ 1604 maxCMBDieTemp_SC05 255 "SNA" ;
VAL_ 1604 minCMBDieTemp_SC05 255 "SNA" ;
VAL_ 1604 appTaskSpiRxTx_SC05 255 "SNA" ;
VAL_ 1604 variantCodingCounts_SC05 255 "SNA" ;
VAL_ 1604 cmbMaxUpdateTime_SC05 255 "SNA" ;
VAL_ 1604 pumpSetSpeed_SC05 255 "SNA" ;
VAL_ 1604 hvilResistance_SC05 255 "SNA" ;
VAL_ 1604 cmbAvgUpdateTime_SC05 255 "SNA" ;
VAL_ 1604 pumpTemperature_SC05 255 "SNA" ;
VAL_ 1604 pumpSpeed_SC05 255 "SNA" ;
VAL_ 1604 pumpVoltage_SC05 255 "SNA" ;
VAL_ 1604 pumpCurrent_SC05 255 "SNA" ;
VAL_ 1604 posLink3_SC05 65535 "SNA" ;
VAL_ 1604 negLink3_SC05 65535 "SNA" ;
VAL_ 1604 posLink2_SC05 65535 "SNA" ;
VAL_ 1604 negLink2_SC05 65535 "SNA" ;
VAL_ 1604 cmbNrOfSamples_SC05 65535 "SNA" ;
VAL_ 1604 cmbTaskTime_SC05 65535 "SNA" ;
VAL_ 1604 appTask500HzMax_SC05 255 "SNA" ;
VAL_ 1604 analogHallSense_SC05 65535 "SNA" ;
VAL_ 1604 cmbMaxDiagStepPeriodicity_SC05 255 "SNA" ;
VAL_ 1604 minBrickVoltageLimit_SC05 65535 "SNA" ;
VAL_ 1604 appTask100Hz_SC05 255 "SNA" ;
VAL_ 1604 appTask10Hz_SC05 255 "SNA" ;
VAL_ 1604 appTaskAnalog_SC05 255 "SNA" ;
VAL_ 1604 appTaskADC_SC05 255 "SNA" ;
VAL_ 1604 appTask500HzAvg_SC05 255 "SNA" ;
VAL_ 1604 appTaskSBC_SC05 255 "SNA" ;
VAL_ 1604 appTaskCMBDriver_SC05 255 "SNA" ;
VAL_ 1604 safetyInitTime_SC05 255 "SNA" ;
VAL_ 1604 debugSlowMpex_SC05 45 "S45" 44 "S44" 43 "S43" 42 "S42" 41 "S41" 0 "S00" 1 "S01" 2 "S02" 3 "S03" 4 "S04" 5 "S05" 6 "S06" 7 "S07" 8 "S08" 9 "S09" 10 "S10" 11 "S11" 12 "S12" 13 "S13" 14 "S14" 15 "S15" 16 "S16" 17 "S17" 18 "S18" 19 "S19" 20 "S20" 21 "S21" 22 "S22" 23 "S23" 24 "S24" 25 "S25" 26 "S26" 27 "S27" 28 "S28" 29 "S29" 30 "S30" 31 "S31" 32 "S32" 33 "S33" 34 "S34" 35 "S35" 36 "S36" 37 "S37" 38 "S38" 39 "S39" 40 "S40" ;
VAL_ 1604 mux440Gnd_SC05 255 "SNA" ;
VAL_ 1604 analogHallGain_SC05 65535 "SNA" ;
VAL_ 1604 analogHallOffset_SC05 255 "SNA" ;
VAL_ 1604 negPackPrime_SC05 65535 "SNA" ;
VAL_ 1604 posPackPrime_SC05 65535 "SNA" ;
VAL_ 1604 packVoltage_SC05 65535 "SNA" ;
VAL_ 1604 sleepTime_SC05 65535 "SNA" ;
VAL_ 1604 analogNegHVOffset_SC05 255 "SNA" ;
VAL_ 1604 analogPosHVOffset_SC05 255 "SNA" ;
VAL_ 1604 analogNegHVGain_SC05 65535 "SNA" ;
VAL_ 1604 analogPosHVGain_SC05 65535 "SNA" ;
VAL_ 1604 mux910Gnd_SC05 255 "SNA" ;
VAL_ 1604 mux960Gnd_SC05 255 "SNA" ;
VAL_ 1604 analogAddr5_SC05 65535 "SNA" ;
VAL_ 1604 analogAddr4_SC05 65535 "SNA" ;
VAL_ 1604 analogAddr3_SC05 65535 "SNA" ;
VAL_ 1604 analogAddr2_SC05 65535 "SNA" ;
VAL_ 1604 analogAddr1_SC05 65535 "SNA" ;
VAL_ 1604 analogAddr0_SC05 65535 "SNA" ;
VAL_ 1604 sbcVREF2P5_SC05 255 "SNA" ;
VAL_ 1604 mux910N3VRef_SC05 65535 "SNA" ;
VAL_ 1604 mux910P2P5VRef_SC05 65535 "SNA" ;
VAL_ 1604 analogHvilCurrentPWM_SC05 255 "SNA" ;
VAL_ 1604 analogSBCSupply_SC05 255 "SNA" ;
VAL_ 1604 analogHvilCurrent_SC05 255 "SNA" ;
VAL_ 1604 analogPressureSense_SC05 255 "SNA" ;
VAL_ 1604 analog5VSensorSupply_SC05 255 "SNA" ;
VAL_ 1604 analogPrechgRel2CoilMinus_SC05 255 "SNA" ;
VAL_ 1604 analogPrechgRel1CoilMinus_SC05 255 "SNA" ;
VAL_ 1604 analogNegCntr3CoilMinus_SC05 255 "SNA" ;
VAL_ 1604 analogNegCntr2CoilMinus_SC05 255 "SNA" ;
VAL_ 1604 analogNegCntr1CoilMinus_SC05 255 "SNA" ;
VAL_ 1604 analogPosCntr3CoilMinus_SC05 255 "SNA" ;
VAL_ 1604 analogPosCntr2CoilMinus_SC05 255 "SNA" ;
VAL_ 1604 analogPosCntr1CoilMinus_SC05 255 "SNA" ;
VAL_ 1604 minModuleTemperature_SC05 255 "SNA" ;
VAL_ 1604 maxModuleTemperature_SC05 255 "SNA" ;
VAL_ 1604 analogHvilReturn_SC05 255 "SNA" ;
VAL_ 1604 analog5VDSupply_SC05 255 "SNA" ;
VAL_ 1604 analogHvilOut_SC05 255 "SNA" ;
VAL_ 1604 analogCurrentSensor12V_SC05 255 "SNA" ;
VAL_ 1604 maxVREF2_SC05 65535 "SNA" ;
VAL_ 1604 minVREF2_SC05 65535 "SNA" ;
VAL_ 1604 hallCurrentOffset_SC05 65535 "SNA" ;
VAL_ 1604 sumOfCurrentsFiltered_SC05 65535 "SNA" ;
VAL_ 1604 hallCurrentAveraged_SC05 65535 "SNA" ;
VAL_ 1604 analogHallSupply_SC05 65535 "SNA" ;
VAL_ 1604 contactorControlPos1_SC05 4 "CTRCTRL_CTRFAIL" 3 "CTRCTRL_CTRON" 2 "CTRCTRL_CTRCHECK" 1 "CTRCTRL_ADDITIONAL_CTRCHECK" 0 "CTRCTRL_CTROFF" ;
VAL_ 1604 contactorControlNeg1_SC05 4 "CTRCTRL_CTRFAIL" 3 "CTRCTRL_CTRON" 2 "CTRCTRL_CTRCHECK" 1 "CTRCTRL_ADDITIONAL_CTRCHECK" 0 "CTRCTRL_CTROFF" ;
VAL_ 1604 contactorControlPre1_SC05 4 "CTRCTRL_CTRFAIL" 3 "CTRCTRL_CTRON" 2 "CTRCTRL_CTRCHECK" 1 "CTRCTRL_ADDITIONAL_CTRCHECK" 0 "CTRCTRL_CTROFF" ;
VAL_ 1604 contactorControlPos2_SC05 4 "CTRCTRL_CTRFAIL" 3 "CTRCTRL_CTRON" 2 "CTRCTRL_CTRCHECK" 1 "CTRCTRL_ADDITIONAL_CTRCHECK" 0 "CTRCTRL_CTROFF" ;
VAL_ 1604 contactorControlNeg2_SC05 4 "CTRCTRL_CTRFAIL" 3 "CTRCTRL_CTRON" 2 "CTRCTRL_CTRCHECK" 1 "CTRCTRL_ADDITIONAL_CTRCHECK" 0 "CTRCTRL_CTROFF" ;
VAL_ 1604 contactorControlPre2_SC05 4 "CTRCTRL_CTRFAIL" 3 "CTRCTRL_CTRON" 2 "CTRCTRL_CTRCHECK" 1 "CTRCTRL_ADDITIONAL_CTRCHECK" 0 "CTRCTRL_CTROFF" ;
VAL_ 1604 contactorControlPos3_SC05 4 "CTRCTRL_CTRFAIL" 3 "CTRCTRL_CTRON" 2 "CTRCTRL_CTRCHECK" 1 "CTRCTRL_ADDITIONAL_CTRCHECK" 0 "CTRCTRL_CTROFF" ;
VAL_ 1604 contactorControlNeg3_SC05 4 "CTRCTRL_CTRFAIL" 3 "CTRCTRL_CTRON" 2 "CTRCTRL_CTRCHECK" 1 "CTRCTRL_ADDITIONAL_CTRCHECK" 0 "CTRCTRL_CTROFF" ;
VAL_ 1668 selfTestFaultCntrCtrl_SC05 4 "CTRCTRL_SELFTEST_NONE" 3 "CTRCTRL_SELFTEST_4" 2 "CTRCTRL_SELFTEST_3" 1 "CTRCTRL_SELFTEST_2" 0 "CTRCTRL_SELFTEST_1" ;
VAL_ 1668 cmbASICFault_SC05 20 "CMBDRIVER_ASIC_UNEXPECTED_MODULE" 19 "CMBDRIVER_ASIC_PEC_DIAGN_READ" 18 "CMBDRIVER_ASIC_PEC_DIAGN_DATA" 17 "CMBDRIVER_ASIC_PEC_DIAGN_CMD" 16 "CMBDRIVER_ASIC_REDUNDANT_FILTER" 15 "CMBDRIVER_ASIC_REDUNDANT_ADC" 14 "CMB_ASIC_CLOCK_LF" 13 "CMB_ASIC_CHARGE_PUMP_LF" 12 "CMB_ASIC_MUX_CHECK_LF" 11 "CMB_ASIC_INTERNAL_SUP_LF" 10 "CMB_ASIC_MUX_COMP_FAIL" 9 "CMB_ASIC_CHARGE_PUMP_FAIL" 8 "CMB_ASIC_OPEN_WIRE_CURR_FAIL" 255 "CMB_ASIC_FAULT_NONE" 7 "CMB_ASIC_VREF3_FAIL" 6 "CMB_ASIC_VREF2_FAIL" 5 "CMB_ASIC_ITEMP_FAIL" 4 "CMB_ASIC_VD_FAIL" 3 "CMB_ASIC_VA_FAIL" 2 "CMB_ASIC_TESTMODE" 1 "CMB_ASIC_CLOCK_FAIL" 0 "CMB_ASIC_MUX_FAIL" ;
VAL_ 1668 mainUcExtIsoResistance_SC05 65535 "SNA" ;
VAL_ 1668 BMS_C38_AR2MsgFault_SC05 3 "MSG_MISSING" 2 "MSG_SEQ_CNT_FAULT" 1 "MSG_CRC_FAULT" 0 "MSG_VALID" ;
VAL_ 1668 stateCoolant_SC05 1 "SAFESTATE_UNSAFE" 0 "SAFESTATE_SAFE" ;
VAL_ 1668 stateThermalEvent_SC05 1 "SAFESTATE_UNSAFE" 0 "SAFESTATE_SAFE" ;
VAL_ 1668 stateCANTx_SC05 1 "SAFESTATE_UNSAFE" 0 "SAFESTATE_SAFE" ;
VAL_ 1668 mainUcCntrCtrlReq_SC05 3 "SAFETYCAN_CNTR_CTRL_SNA" 1 "SAFETYCAN_CNTR_CTRL_CLS" 0 "SAFETYCAN_CNTR_CTRL_OPEN" ;
VAL_ 1668 mainUcCntrWeldState_SC05 7 "SAFETYCAN_WELD_HV_ALL_ERR" 6 "SAFETYCAN_WELD_HV_PLUS_MINUS_ERR" 15 "SAFETYCAN_WELD_SNA" 5 "SAFETYCAN_WELD_PRE_HV_MINUS_ERR" 4 "SAFETYCAN_WELD_HV_MINUS_ERR" 3 "SAFETYCAN_WELD_PRE_HV_PLUS_ERR" 2 "SAFETYCAN_WELD_HV_PLUS_ERR" 1 "SAFETYCAN_WELD_PRE_ERR" 0 "SAFETYCAN_WELD_NO_ERR" ;
VAL_ 1668 safetyUcCntrState_SC05 2 "SAFETYCAN_CNTR_CLS" 3 "SAFETYCAN_CNTR_SNA" 1 "SAFETYCAN_CNTR_PRECHRG" 0 "SAFETYCAN_CNTR_OPEN" ;
VAL_ 1668 mainUcCntrState_SC05 2 "SAFETYCAN_CNTR_CLS" 3 "SAFETYCAN_CNTR_SNA" 1 "SAFETYCAN_CNTR_PRECHRG" 0 "SAFETYCAN_CNTR_OPEN" ;
VAL_ 1668 safetyCANMsg4Fault_SC05 6 "SAFETYCAN_E2E_CRC" 15 "SAFETYCAN_SNA" 5 "SAFETYCAN_SPI_FAIL" 4 "SAFETYCAN_MSG_MISSING" 3 "SAFETYCAN_MSG_CNT_MISMATCH" 2 "SAFETYCAN_ALIVE_CNT" 1 "SAFETYCAN_SPI_CRC" 0 "SAFETYCAN_GOOD" ;
VAL_ 1668 safetyCANMsg3Fault_SC05 6 "SAFETYCAN_E2E_CRC" 15 "SAFETYCAN_SNA" 5 "SAFETYCAN_SPI_FAIL" 4 "SAFETYCAN_MSG_MISSING" 3 "SAFETYCAN_MSG_CNT_MISMATCH" 2 "SAFETYCAN_ALIVE_CNT" 1 "SAFETYCAN_SPI_CRC" 0 "SAFETYCAN_GOOD" ;
VAL_ 1668 safetyCANMsg2Fault_SC05 6 "SAFETYCAN_E2E_CRC" 15 "SAFETYCAN_SNA" 5 "SAFETYCAN_SPI_FAIL" 4 "SAFETYCAN_MSG_MISSING" 3 "SAFETYCAN_MSG_CNT_MISMATCH" 2 "SAFETYCAN_ALIVE_CNT" 1 "SAFETYCAN_SPI_CRC" 0 "SAFETYCAN_GOOD" ;
VAL_ 1668 safetyCANMsg1Fault_SC05 6 "SAFETYCAN_E2E_CRC" 15 "SAFETYCAN_SNA" 5 "SAFETYCAN_SPI_FAIL" 4 "SAFETYCAN_MSG_MISSING" 3 "SAFETYCAN_MSG_CNT_MISMATCH" 2 "SAFETYCAN_ALIVE_CNT" 1 "SAFETYCAN_SPI_CRC" 0 "SAFETYCAN_GOOD" ;
VAL_ 1668 contactorCntrSelfTest_SC05 9 "CTRCTRL_CHKLOSIDE_OPEN_CIRC" 8 "CTRCTRL_FAILED" 7 "CTRCTRL_PASSED" 6 "CTRCTRL_CHKHISIDE_STUCK_OPEN" 5 "CTRCTRL_CHK_CLOSE_OK_CIRCUIT" 4 "CTRCTRL_CHKLOSIDE_CTRL_OK" 3 "CTRCTRL_CHKLOSIDE_STUCK_CLOSED" 2 "CTRCTRL_CHKHISIDE_STUCK_CLOSED" 1 "CTRCTRL_PENDING" 0 "CTRCTRL_INIT" ;
VAL_ 1668 maxBrickVoltage_SC05 65535 "SNA" ;
VAL_ 1668 minBrickVoltage_SC05 65535 "SNA" ;
VAL_ 1668 cmbLastUpdateTime_SC05 255 "SNA" ;
VAL_ 1668 weldCheckState_SC05 4 "WELDCHECK_IDLE" 3 "WELDCHECK" 2 "WELDCHECK_ISO_2" 1 "WELDCHECK_ISO_1" 0 "WELDCHECK_INIT" ;
VAL_ 1668 debugFastMpex_SC05 0 "F00" 1 "F01" 2 "F02" 3 "F03" 4 "F04" 5 "F05" 6 "F06" 7 "F07" 8 "F08" 9 "F09" 10 "F10" 11 "F11" 12 "F12" 13 "F13" 14 "F14" 15 "F15" ;
VAL_ 1668 SPIRxTxTimeAllPckts_SC05 255 "SNA" ;
VAL_ 1668 stateContactorControl_SC05 1 "SAFESTATE_UNSAFE" 0 "SAFESTATE_SAFE" ;
VAL_ 1668 analogCntrPwrPlus_SC05 255 "SNA" ;
VAL_ 1668 weldedState_SC05 2 "CTR_WELD_SNA" 0 "CTR_NOTWELDED" 1 "CTR_ATLEASTONE_WELDED" ;
VAL_ 1668 stateVoltage_SC05 1 "SAFESTATE_UNSAFE" 0 "SAFESTATE_SAFE" ;
VAL_ 1668 stateTemperature_SC05 1 "SAFESTATE_UNSAFE" 0 "SAFESTATE_SAFE" ;
VAL_ 1668 stateSelfTest_SC05 1 "SAFESTATE_UNSAFE" 0 "SAFESTATE_SAFE" ;
VAL_ 1668 stateHVIL_SC05 1 "SAFESTATE_UNSAFE" 0 "SAFESTATE_SAFE" ;
VAL_ 1668 stateCurrent_SC05 1 "SAFESTATE_UNSAFE" 0 "SAFESTATE_SAFE" ;
VAL_ 1668 stateCrash2_SC05 1 "SAFESTATE_UNSAFE" 0 "SAFESTATE_SAFE" ;
VAL_ 1668 stateCrash1_SC05 1 "SAFESTATE_UNSAFE" 0 "SAFESTATE_SAFE" ;
VAL_ 1668 stateContactors_SC05 1 "SAFESTATE_UNSAFE" 0 "SAFESTATE_SAFE" ;
VAL_ 1668 stateCANRx_SC05 1 "SAFESTATE_UNSAFE" 0 "SAFESTATE_SAFE" ;
VAL_ 1668 itemState_SC05 15 "ITEM_INVALID" 2 "ITEM_EMERGENCY" 1 "ITEM_OFF" 0 "ITEM_ON" ;
VAL_ 1668 posPack_SC05 65535 "SNA" ;
VAL_ 1668 posLink_SC05 65535 "SNA" ;
VAL_ 1668 negPack_SC05 65535 "SNA" ;
VAL_ 1668 negLink_SC05 65535 "SNA" ;
VAL_ 1668 hallCurrent_SC05 4095 "SNA" ;
VAL_ 1668 analogCntrPwrPlusISense_SC05 255 "SNA" ;
VAL_ 1668 analogCntrPwrPlusSwitched_SC05 255 "SNA" ;
VAL_ 1924 cmbCoolantTemp08_BMS05 255 "SNA" ;
VAL_ 1924 cmbCoolantTemp07_BMS05 255 "SNA" ;
VAL_ 1924 cmbCoolantTemp06_BMS05 255 "SNA" ;
VAL_ 1924 cmbCoolantTemp05_BMS05 255 "SNA" ;
VAL_ 1924 cmbCoolantTemp04_BMS05 255 "SNA" ;
VAL_ 1924 cmbCoolantTemp03_BMS05 255 "SNA" ;
VAL_ 1924 cmbCoolantTemp02_BMS05 255 "SNA" ;
VAL_ 1924 cmbCoolantTemp01_BMS05 255 "SNA" ;
VAL_ 1924 cmbOnboardPressure32_BMS05 65535 "SNA" ;
VAL_ 1924 cmbOnboardPressure31_BMS05 65535 "SNA" ;
VAL_ 1924 cmbOnboardPressure30_BMS05 65535 "SNA" ;
VAL_ 1924 cmbOnboardPressure29_BMS05 65535 "SNA" ;
VAL_ 1924 cmbOnboardPressure28_BMS05 65535 "SNA" ;
VAL_ 1924 cmbOnboardPressure27_BMS05 65535 "SNA" ;
VAL_ 1924 cmbOnboardPressure26_BMS05 65535 "SNA" ;
VAL_ 1924 cmbOnboardPressure25_BMS05 65535 "SNA" ;
VAL_ 1924 cmbOnboardPressure24_BMS05 65535 "SNA" ;
VAL_ 1924 cmbOnboardPressure23_BMS05 65535 "SNA" ;
VAL_ 1924 cmbOnboardPressure22_BMS05 65535 "SNA" ;
VAL_ 1924 cmbOnboardPressure21_BMS05 65535 "SNA" ;
VAL_ 1924 cmbOnboardPressure20_BMS05 65535 "SNA" ;
VAL_ 1924 cmbOnboardPressure19_BMS05 65535 "SNA" ;
VAL_ 1924 cmbOnboardPressure18_BMS05 65535 "SNA" ;
VAL_ 1924 cmbOnboardPressure17_BMS05 65535 "SNA" ;
VAL_ 1924 cmbOnboardPressure16_BMS05 65535 "SNA" ;
VAL_ 1924 cmbOnboardPressure15_BMS05 65535 "SNA" ;
VAL_ 1924 cmbOnboardPressure14_BMS05 65535 "SNA" ;
VAL_ 1924 cmbOnboardPressure13_BMS05 65535 "SNA" ;
VAL_ 1924 cmbOnboardPressure12_BMS05 65535 "SNA" ;
VAL_ 1924 cmbOnboardPressure11_BMS05 65535 "SNA" ;
VAL_ 1924 cmbOnboardPressure10_BMS05 65535 "SNA" ;
VAL_ 1924 cmbOnboardPressure09_BMS05 65535 "SNA" ;
VAL_ 1924 cmbOnboardPressure08_BMS05 65535 "SNA" ;
VAL_ 1924 cmbOnboardPressure07_BMS05 65535 "SNA" ;
VAL_ 1924 cmbOnboardPressure06_BMS05 65535 "SNA" ;
VAL_ 1924 cmbOnboardPressure05_BMS05 65535 "SNA" ;
VAL_ 1924 cmbOnboardPressure04_BMS05 65535 "SNA" ;
VAL_ 1924 cmbOnboardPressure03_BMS05 65535 "SNA" ;
VAL_ 1924 cmbOnboardPressure02_BMS05 65535 "SNA" ;
VAL_ 1924 cmbOnboardPressure01_BMS05 65535 "SNA" ;
VAL_ 1924 onboardMultiplexor_BMS05 32 "O32" 31 "O31" 30 "O30" 29 "O29" 28 "O28" 27 "O27" 26 "O26" 25 "O25" 24 "O24" 23 "O23" 22 "O22" 21 "O21" 20 "O20" 19 "O19" 18 "O18" 17 "O17" 16 "O16" 15 "O15" 14 "O14" 13 "O13" 0 "O00" 1 "O01" 2 "O02" 3 "O03" 4 "O04" 5 "O05" 6 "O06" 7 "O07" 8 "O08" 9 "O09" 10 "O10" 11 "O11" 12 "O12" ;
VAL_ 1924 minCmbOnboardTemperature_BMS05 255 "SNA" ;
VAL_ 1924 minCmbOnboardHumidity_BMS05 255 "SNA" ;
VAL_ 1924 maxCmbOnboardTemperature_BMS05 255 "SNA" ;
VAL_ 1924 maxCmbOnboardHumidity_BMS05 255 "SNA" ;
VAL_ 1924 bmsOnboardTemperature_BMS05 255 "SNA" ;
VAL_ 1924 bmsOnboardHumidity_BMS05 255 "SNA" ;
VAL_ 1924 cmbOnboardTemperature01_BMS05 255 "SNA" ;
VAL_ 1924 cmbOnboardHumidity01_BMS05 255 "SNA" ;
VAL_ 1924 moduleHeaterCurrent01_BMS05 255 "SNA" ;
VAL_ 1924 cmbOnboardTemperature02_BMS05 255 "SNA" ;
VAL_ 1924 cmbOnboardHumidity02_BMS05 255 "SNA" ;
VAL_ 1924 moduleHeaterCurrent02_BMS05 255 "SNA" ;
VAL_ 1924 cmbOnboardTemperature03_BMS05 255 "SNA" ;
VAL_ 1924 cmbOnboardHumidity03_BMS05 255 "SNA" ;
VAL_ 1924 moduleHeaterCurrent03_BMS05 255 "SNA" ;
VAL_ 1924 cmbOnboardTemperature04_BMS05 255 "SNA" ;
VAL_ 1924 cmbOnboardHumidity04_BMS05 255 "SNA" ;
VAL_ 1924 moduleHeaterCurrent04_BMS05 255 "SNA" ;
VAL_ 1924 cmbOnboardTemperature05_BMS05 255 "SNA" ;
VAL_ 1924 cmbOnboardHumidity05_BMS05 255 "SNA" ;
VAL_ 1924 moduleHeaterCurrent05_BMS05 255 "SNA" ;
VAL_ 1924 cmbOnboardTemperature06_BMS05 255 "SNA" ;
VAL_ 1924 cmbOnboardHumidity06_BMS05 255 "SNA" ;
VAL_ 1924 moduleHeaterCurrent06_BMS05 255 "SNA" ;
VAL_ 1924 cmbOnboardTemperature07_BMS05 255 "SNA" ;
VAL_ 1924 cmbOnboardHumidity07_BMS05 255 "SNA" ;
VAL_ 1924 moduleHeaterCurrent07_BMS05 255 "SNA" ;
VAL_ 1924 cmbOnboardTemperature08_BMS05 255 "SNA" ;
VAL_ 1924 cmbOnboardHumidity08_BMS05 255 "SNA" ;
VAL_ 1924 moduleHeaterCurrent08_BMS05 255 "SNA" ;
VAL_ 1924 cmbOnboardTemperature09_BMS05 255 "SNA" ;
VAL_ 1924 cmbOnboardHumidity09_BMS05 255 "SNA" ;
VAL_ 1924 moduleHeaterCurrent09_BMS05 255 "SNA" ;
VAL_ 1924 cmbOnboardTemperature10_BMS05 255 "SNA" ;
VAL_ 1924 cmbOnboardHumidity10_BMS05 255 "SNA" ;
VAL_ 1924 moduleHeaterCurrent10_BMS05 255 "SNA" ;
VAL_ 1924 cmbOnboardTemperature11_BMS05 255 "SNA" ;
VAL_ 1924 cmbOnboardHumidity11_BMS05 255 "SNA" ;
VAL_ 1924 moduleHeaterCurrent11_BMS05 255 "SNA" ;
VAL_ 1924 cmbOnboardTemperature12_BMS05 255 "SNA" ;
VAL_ 1924 cmbOnboardHumidity12_BMS05 255 "SNA" ;
VAL_ 1924 moduleHeaterCurrent12_BMS05 255 "SNA" ;
VAL_ 1924 cmbOnboardTemperature13_BMS05 255 "SNA" ;
VAL_ 1924 cmbOnboardHumidity13_BMS05 255 "SNA" ;
VAL_ 1924 moduleHeaterCurrent13_BMS05 255 "SNA" ;
VAL_ 1924 cmbOnboardTemperature14_BMS05 255 "SNA" ;
VAL_ 1924 cmbOnboardHumidity14_BMS05 255 "SNA" ;
VAL_ 1924 moduleHeaterCurrent14_BMS05 255 "SNA" ;
VAL_ 1924 cmbOnboardTemperature15_BMS05 255 "SNA" ;
VAL_ 1924 cmbOnboardHumidity15_BMS05 255 "SNA" ;
VAL_ 1924 moduleHeaterCurrent15_BMS05 255 "SNA" ;
VAL_ 1924 cmbOnboardTemperature16_BMS05 255 "SNA" ;
VAL_ 1924 cmbOnboardHumidity16_BMS05 255 "SNA" ;
VAL_ 1924 moduleHeaterCurrent16_BMS05 255 "SNA" ;
VAL_ 1924 cmbOnboardTemperature17_BMS05 255 "SNA" ;
VAL_ 1924 cmbOnboardHumidity17_BMS05 255 "SNA" ;
VAL_ 1924 moduleHeaterCurrent17_BMS05 255 "SNA" ;
VAL_ 1924 cmbOnboardTemperature18_BMS05 255 "SNA" ;
VAL_ 1924 cmbOnboardHumidity18_BMS05 255 "SNA" ;
VAL_ 1924 moduleHeaterCurrent18_BMS05 255 "SNA" ;
VAL_ 1924 cmbOnboardTemperature19_BMS05 255 "SNA" ;
VAL_ 1924 cmbOnboardHumidity19_BMS05 255 "SNA" ;
VAL_ 1924 moduleHeaterCurrent19_BMS05 255 "SNA" ;
VAL_ 1924 cmbOnboardTemperature20_BMS05 255 "SNA" ;
VAL_ 1924 cmbOnboardHumidity20_BMS05 255 "SNA" ;
VAL_ 1924 moduleHeaterCurrent20_BMS05 255 "SNA" ;
VAL_ 1924 cmbOnboardTemperature21_BMS05 255 "SNA" ;
VAL_ 1924 cmbOnboardHumidity21_BMS05 255 "SNA" ;
VAL_ 1924 moduleHeaterCurrent21_BMS05 255 "SNA" ;
VAL_ 1924 cmbOnboardTemperature22_BMS05 255 "SNA" ;
VAL_ 1924 cmbOnboardHumidity22_BMS05 255 "SNA" ;
VAL_ 1924 moduleHeaterCurrent22_BMS05 255 "SNA" ;
VAL_ 1924 cmbOnboardTemperature23_BMS05 255 "SNA" ;
VAL_ 1924 cmbOnboardHumidity23_BMS05 255 "SNA" ;
VAL_ 1924 moduleHeaterCurrent23_BMS05 255 "SNA" ;
VAL_ 1924 cmbOnboardTemperature24_BMS05 255 "SNA" ;
VAL_ 1924 cmbOnboardHumidity24_BMS05 255 "SNA" ;
VAL_ 1924 moduleHeaterCurrent24_BMS05 255 "SNA" ;
VAL_ 1924 cmbOnboardTemperature25_BMS05 255 "SNA" ;
VAL_ 1924 cmbOnboardHumidity25_BMS05 255 "SNA" ;
VAL_ 1924 moduleHeaterCurrent25_BMS05 255 "SNA" ;
VAL_ 1924 cmbOnboardTemperature26_BMS05 255 "SNA" ;
VAL_ 1924 cmbOnboardHumidity26_BMS05 255 "SNA" ;
VAL_ 1924 moduleHeaterCurrent26_BMS05 255 "SNA" ;
VAL_ 1924 cmbOnboardTemperature27_BMS05 255 "SNA" ;
VAL_ 1924 cmbOnboardHumidity27_BMS05 255 "SNA" ;
VAL_ 1924 moduleHeaterCurrent27_BMS05 255 "SNA" ;
VAL_ 1924 cmbOnboardTemperature28_BMS05 255 "SNA" ;
VAL_ 1924 cmbOnboardHumidity28_BMS05 255 "SNA" ;
VAL_ 1924 moduleHeaterCurrent28_BMS05 255 "SNA" ;
VAL_ 1924 cmbOnboardTemperature29_BMS05 255 "SNA" ;
VAL_ 1924 cmbOnboardHumidity29_BMS05 255 "SNA" ;
VAL_ 1924 moduleHeaterCurrent29_BMS05 255 "SNA" ;
VAL_ 1924 cmbOnboardTemperature30_BMS05 255 "SNA" ;
VAL_ 1924 cmbOnboardHumidity30_BMS05 255 "SNA" ;
VAL_ 1924 moduleHeaterCurrent30_BMS05 255 "SNA" ;
VAL_ 1924 cmbOnboardTemperature31_BMS05 255 "SNA" ;
VAL_ 1924 cmbOnboardHumidity31_BMS05 255 "SNA" ;
VAL_ 1924 moduleHeaterCurrent31_BMS05 255 "SNA" ;
VAL_ 1924 cmbOnboardTemperature32_BMS05 255 "SNA" ;
VAL_ 1924 cmbOnboardHumidity32_BMS05 255 "SNA" ;
VAL_ 1924 moduleHeaterCurrent32_BMS05 255 "SNA" ;
